VERSION ""

NS_ :

BS_:

BU_: Vector__XXX
BA_DEF_ BO_ "VFrameFormat" ENUM "StandardCAN","ExtendedCAN","reserved","J1939PG";
BA_DEF_DEF_ "VFrameFormat" 0;

BO_ 2565933008 ZT_18F107D0: 8 Vector__XXX
 SG_ 驱动电机序号 : 0|8@1+ (1,0) [0|0] "" Vector__XXX
 SG_ 加速踏板行程值 : 40|8@1+ (1,0) [0|0] "%" Vector__XXX
 SG_ 制动踏板状态 : 48|8@1+ (1,0) [0|0] "%" Vector__XXX
 SG_ 电机控制器输入电压 : 15|16@0+ (0.1,0) [0|0] "V" Vector__XXX

BA_ "VFrameFormat" BO_ 2565933008 1;
CM_ BO_ 2565933008 "制动踏板状态 / 加速踏板行程值 | 信号数 5";
CM_ SG_ 2565933008 驱动电机序号 "驱动电机序号";
CM_ SG_ 2565933008 加速踏板行程值 "加速踏板行程值";
CM_ SG_ 2565933008 制动踏板状态 "制动踏板状态";
CM_ SG_ 2565933008 电机控制器输入电压 "电机控制器输入电压";

BO_ 2565933043 ZT_UNKNOWN_18F107F3: 8 Vector__XXX
 SG_ 字节0 : 0|8@1+ (1,0) [0|255] "" Vector__XXX
 SG_ 字节1 : 8|8@1+ (1,0) [0|255] "" Vector__XXX
 SG_ 字节2 : 16|8@1+ (1,0) [0|255] "" Vector__XXX
 SG_ 字节3 : 24|8@1+ (1,0) [0|255] "" Vector__XXX
 SG_ 字节4 : 32|8@1+ (1,0) [0|255] "" Vector__XXX
 SG_ 字节5 : 40|8@1+ (1,0) [0|255] "" Vector__XXX
 SG_ 字节6 : 48|8@1+ (1,0) [0|255] "" Vector__XXX
 SG_ 字节7 : 56|8@1+ (1,0) [0|255] "" Vector__XXX

BA_ "VFrameFormat" BO_ 2565933043 1;
CM_ BO_ 2565933043 "电池管理系统 | 无信号定义, 按原始字节输出";
CM_ SG_ 2565933043 字节0 "字节0（原始值，无信号定义）";
CM_ SG_ 2565933043 字节1 "字节1（原始值，无信号定义）";
CM_ SG_ 2565933043 字节2 "字节2（原始值，无信号定义）";
CM_ SG_ 2565933043 字节3 "字节3（原始值，无信号定义）";
CM_ SG_ 2565933043 字节4 "字节4（原始值，无信号定义）";
CM_ SG_ 2565933043 字节5 "字节5（原始值，无信号定义）";
CM_ SG_ 2565933043 字节6 "字节6（原始值，无信号定义）";
CM_ SG_ 2565933043 字节7 "字节7（原始值，无信号定义）";

BO_ 2565933264 ZT_18F108D0: 8 Vector__XXX
 SG_ 温度差异报警 : 8|1@1+ (1,0) [0|0] "" Vector__XXX
 SG_ 电池高温报警 : 9|1@1+ (1,0) [0|0] "" Vector__XXX
 SG_ 车载储能装置过压报警 : 10|1@1+ (1,0) [0|0] "" Vector__XXX
 SG_ 车载储能装置欠压报警 : 11|1@1+ (1,0) [0|0] "" Vector__XXX
 SG_ SOC(电池可用容量)低报警 : 12|1@1+ (1,0) [0|0] "" Vector__XXX
 SG_ 单体过压报警 : 13|1@1+ (1,0) [0|0] "" Vector__XXX
 SG_ 单体欠压报警 : 14|1@1+ (1,0) [0|0] "" Vector__XXX
 SG_ SOC(电池可用容量)过高报警 : 15|1@1+ (1,0) [0|0] "" Vector__XXX
 SG_ SOC(电池可用容量)跳变报警 : 16|1@1+ (1,0) [0|0] "" Vector__XXX
 SG_ 可充电储能系统不匹配报警 : 17|1@1+ (1,0) [0|0] "" Vector__XXX
 SG_ 电池单体一致性差报警 : 18|1@1+ (1,0) [0|0] "" Vector__XXX
 SG_ 绝缘报警 : 19|1@1+ (1,0) [0|0] "" Vector__XXX
 SG_ DCDC(直流转化直流)温度报警 : 20|1@1+ (1,0) [0|0] "" Vector__XXX
 SG_ 制动系统报警 : 21|1@1+ (1,0) [0|0] "" Vector__XXX
 SG_ DCDC(直流转化直流)状态报警 : 22|1@1+ (1,0) [0|0] "" Vector__XXX
 SG_ 驱动电机控制器温度报警 : 23|1@1+ (1,0) [0|0] "" Vector__XXX
 SG_ 高压互锁状态报警 : 24|1@1+ (1,0) [0|0] "" Vector__XXX
 SG_ 驱动电机温度报警 : 25|1@1+ (1,0) [0|0] "" Vector__XXX
 SG_ 车载储能装置过充 : 26|1@1+ (1,0) [0|0] "" Vector__XXX
 SG_ 最高报警等级 : 0|8@1+ (1,0) [0|0] "" Vector__XXX
 SG_ 可充电储能装置故障总数 : 40|8@1+ (1,0) [0|0] "" Vector__XXX
 SG_ 驱动电机故障总数 : 48|8@1+ (1,0) [0|0] "" Vector__XXX
 SG_ 其他故障总数 : 56|8@1+ (1,0) [0|0] "" Vector__XXX

BA_ "VFrameFormat" BO_ 2565933264 1;
CM_ BO_ 2565933264 "DCDC(直流转化直流)温度报警 / DCDC(直流转化直流)状态报警 | 信号数 23";
CM_ SG_ 2565933264 温度差异报警 "温度差异报警 [枚举: 报警|无]";
VAL_ 2565933264 温度差异报警 0 "无" 1 "报警";
CM_ SG_ 2565933264 电池高温报警 "电池高温报警 [枚举: 报警|无]";
VAL_ 2565933264 电池高温报警 0 "无" 1 "报警";
CM_ SG_ 2565933264 车载储能装置过压报警 "车载储能装置过压报警 [枚举: 报警|无]";
VAL_ 2565933264 车载储能装置过压报警 0 "无" 1 "报警";
CM_ SG_ 2565933264 车载储能装置欠压报警 "车载储能装置欠压报警 [枚举: 报警|无]";
VAL_ 2565933264 车载储能装置欠压报警 0 "无" 1 "报警";
CM_ SG_ 2565933264 SOC(电池可用容量)低报警 "SOC(电池可用容量)低报警 [枚举: 报警|无]";
VAL_ 2565933264 SOC(电池可用容量)低报警 0 "无" 1 "报警";
CM_ SG_ 2565933264 单体过压报警 "单体过压报警 [枚举: 报警|无]";
VAL_ 2565933264 单体过压报警 0 "无" 1 "报警";
CM_ SG_ 2565933264 单体欠压报警 "单体欠压报警 [枚举: 报警|无]";
VAL_ 2565933264 单体欠压报警 0 "无" 1 "报警";
CM_ SG_ 2565933264 SOC(电池可用容量)过高报警 "SOC(电池可用容量)过高报警 [枚举: 报警|无]";
VAL_ 2565933264 SOC(电池可用容量)过高报警 0 "无" 1 "报警";
CM_ SG_ 2565933264 SOC(电池可用容量)跳变报警 "SOC(电池可用容量)跳变报警 [枚举: 报警|无]";
VAL_ 2565933264 SOC(电池可用容量)跳变报警 0 "无" 1 "报警";
CM_ SG_ 2565933264 可充电储能系统不匹配报警 "可充电储能系统不匹配报警 [枚举: 报警|无]";
VAL_ 2565933264 可充电储能系统不匹配报警 0 "无" 1 "报警";
CM_ SG_ 2565933264 电池单体一致性差报警 "电池单体一致性差报警 [枚举: 报警|无]";
VAL_ 2565933264 电池单体一致性差报警 0 "无" 1 "报警";
CM_ SG_ 2565933264 绝缘报警 "绝缘报警 [枚举: 报警|无]";
VAL_ 2565933264 绝缘报警 0 "无" 1 "报警";
CM_ SG_ 2565933264 DCDC(直流转化直流)温度报警 "DCDC(直流转化直流)温度报警 [枚举: 报警|无]";
VAL_ 2565933264 DCDC(直流转化直流)温度报警 0 "无" 1 "报警";
CM_ SG_ 2565933264 制动系统报警 "制动系统报警 [枚举: 报警|无]";
VAL_ 2565933264 制动系统报警 0 "无" 1 "报警";
CM_ SG_ 2565933264 DCDC(直流转化直流)状态报警 "DCDC(直流转化直流)状态报警 [枚举: 报警|无]";
VAL_ 2565933264 DCDC(直流转化直流)状态报警 0 "无" 1 "报警";
CM_ SG_ 2565933264 驱动电机控制器温度报警 "驱动电机控制器温度报警 [枚举: 报警|无]";
VAL_ 2565933264 驱动电机控制器温度报警 0 "无" 1 "报警";
CM_ SG_ 2565933264 高压互锁状态报警 "高压互锁状态报警 [枚举: 报警|无]";
VAL_ 2565933264 高压互锁状态报警 0 "无" 1 "报警";
CM_ SG_ 2565933264 驱动电机温度报警 "驱动电机温度报警 [枚举: 报警|无]";
VAL_ 2565933264 驱动电机温度报警 0 "无" 1 "报警";
CM_ SG_ 2565933264 车载储能装置过充 "车载储能装置过充 [枚举: 报警|无]";
VAL_ 2565933264 车载储能装置过充 0 "无" 1 "报警";
CM_ SG_ 2565933264 最高报警等级 "最高报警等级 [枚举: 无故障|1级故障（轻微）|2级故障（较严重）|3级故障（严重）|异常|无效|无效数据]";
VAL_ 2565933264 最高报警等级 0 "无故障" 1 "1级故障（轻微）" 2 "2级故障（较严重）" 3 "3级故障（严重）" 254 "异常" 255 "无效";
CM_ SG_ 2565933264 可充电储能装置故障总数 "可充电储能装置故障总数";
CM_ SG_ 2565933264 驱动电机故障总数 "驱动电机故障总数";
CM_ SG_ 2565933264 其他故障总数 "其他故障总数";

BO_ 2565933299 ZT_UNKNOWN_18F108F3: 8 Vector__XXX
 SG_ 字节0 : 0|8@1+ (1,0) [0|255] "" Vector__XXX
 SG_ 字节1 : 8|8@1+ (1,0) [0|255] "" Vector__XXX
 SG_ 字节2 : 16|8@1+ (1,0) [0|255] "" Vector__XXX
 SG_ 字节3 : 24|8@1+ (1,0) [0|255] "" Vector__XXX
 SG_ 字节4 : 32|8@1+ (1,0) [0|255] "" Vector__XXX
 SG_ 字节5 : 40|8@1+ (1,0) [0|255] "" Vector__XXX
 SG_ 字节6 : 48|8@1+ (1,0) [0|255] "" Vector__XXX
 SG_ 字节7 : 56|8@1+ (1,0) [0|255] "" Vector__XXX

BA_ "VFrameFormat" BO_ 2565933299 1;
CM_ BO_ 2565933299 "电池管理系统 | 无信号定义, 按原始字节输出";
CM_ SG_ 2565933299 字节0 "字节0（原始值，无信号定义）";
CM_ SG_ 2565933299 字节1 "字节1（原始值，无信号定义）";
CM_ SG_ 2565933299 字节2 "字节2（原始值，无信号定义）";
CM_ SG_ 2565933299 字节3 "字节3（原始值，无信号定义）";
CM_ SG_ 2565933299 字节4 "字节4（原始值，无信号定义）";
CM_ SG_ 2565933299 字节5 "字节5（原始值，无信号定义）";
CM_ SG_ 2565933299 字节6 "字节6（原始值，无信号定义）";
CM_ SG_ 2565933299 字节7 "字节7（原始值，无信号定义）";

BO_ 2565933520 ZT_18F109D0: 8 Vector__XXX
 SG_ 母线过流三级故障 : 0|1@1+ (1,0) [0|0] "" Vector__XXX
 SG_ 母线过压三级故障 : 1|1@1+ (1,0) [0|0] "" Vector__XXX
 SG_ 逆变器过温三级故障 : 2|1@1+ (1,0) [0|0] "" Vector__XXX
 SG_ 电机过温三级故障 : 3|1@1+ (1,0) [0|0] "" Vector__XXX
 SG_ 模块故障三级故障 : 4|1@1+ (1,0) [0|0] "" Vector__XXX
 SG_ CAN通信故障三级故障 : 5|1@1+ (1,0) [0|0] "" Vector__XXX
 SG_ 相电流过流三级故障 : 6|1@1+ (1,0) [0|0] "" Vector__XXX
 SG_ 电机欠压三级故障 : 7|1@1+ (1,0) [0|0] "" Vector__XXX
 SG_ 电机超速三级故障 : 8|1@1+ (1,0) [0|0] "" Vector__XXX
 SG_ 电机温度偏大一级故障 : 9|1@1+ (1,0) [0|0] "" Vector__XXX
 SG_ 母线电压偏小一级故障 : 10|1@1+ (1,0) [0|0] "" Vector__XXX
 SG_ 母线电压偏大一级故障 : 11|1@1+ (1,0) [0|0] "" Vector__XXX
 SG_ 逆变器温度偏大一级故障 : 12|1@1+ (1,0) [0|0] "" Vector__XXX
 SG_ 相电流过载一级故障 : 13|1@1+ (1,0) [0|0] "" Vector__XXX
 SG_ 电机堵转故障三级故障 : 14|1@1+ (1,0) [0|0] "" Vector__XXX
 SG_ 软件检测过流三级故障 : 15|1@1+ (1,0) [0|0] "" Vector__XXX
 SG_ 控制器硬件检测有故障三级故障 : 16|1@1+ (1,0) [0|0] "" Vector__XXX
 SG_ 控制器过温三级故障 : 17|1@1+ (1,0) [0|0] "" Vector__XXX
 SG_ SDUerror三级故障 : 18|1@1+ (1,0) [0|0] "" Vector__XXX
 SG_ 初始化故障一级故障 : 19|1@1+ (1,0) [0|0] "" Vector__XXX
 SG_ VCU(整车控制器)硬件三级故障 : 32|1@1+ (1,0) [0|0] "" Vector__XXX
 SG_ VCU(整车控制器)供电异常三级故障 : 33|1@1+ (1,0) [0|0] "" Vector__XXX
 SG_ 电机控制器预充三级故障 : 34|1@1+ (1,0) [0|0] "" Vector__XXX
 SG_ VCU(整车控制器)与BMS(电池管理系统)通信三级故障 : 35|1@1+ (1,0) [0|0] "" Vector__XXX
 SG_ VCU(整车控制器)与MCU(驱动电机控制单元)通信三级故障 : 36|1@1+ (1,0) [0|0] "" Vector__XXX
 SG_ VCU(整车控制器)与换档面板通信三级故障 : 37|1@1+ (1,0) [0|0] "" Vector__XXX
 SG_ 制动踏板三级故障 : 38|1@1+ (1,0) [0|0] "" Vector__XXX
 SG_ 加速踏板三级故障 : 39|1@1+ (1,0) [0|0] "" Vector__XXX
 SG_ 换档面板三级故障 : 40|1@1+ (1,0) [0|0] "" Vector__XXX
 SG_ 电机转速传感器故障三级故障 : 41|1@1+ (1,0) [0|0] "" Vector__XXX
 SG_ 变速器三级故障 : 42|1@1+ (1,0) [0|0] "" Vector__XXX
 SG_ 变速器转速传感器三级故障 : 43|1@1+ (1,0) [0|0] "" Vector__XXX
 SG_ 变速器位置传感器三级故障 : 44|1@1+ (1,0) [0|0] "" Vector__XXX
 SG_ 变速器执行器三级故障 : 45|1@1+ (1,0) [0|0] "" Vector__XXX
 SG_ 档位啮合三级故障 : 46|1@1+ (1,0) [0|0] "" Vector__XXX
 SG_ 摘挡三级故障 : 47|1@1+ (1,0) [0|0] "" Vector__XXX
 SG_ 选档三级故障 : 48|1@1+ (1,0) [0|0] "" Vector__XXX
 SG_ 挂档三级故障 : 49|1@1+ (1,0) [0|0] "" Vector__XXX
 SG_ VCU(整车控制器)系统三级故障 : 50|1@1+ (1,0) [0|0] "" Vector__XXX
 SG_ 车速二级故障 : 56|1@1+ (1,0) [0|0] "" Vector__XXX

BA_ "VFrameFormat" BO_ 2565933520 1;
CM_ BO_ 2565933520 "CAN通信故障三级故障 / SDUerror三级故障 | 信号数 40";
CM_ SG_ 2565933520 母线过流三级故障 "母线过流三级故障 [枚举: 故障|无故障]";
VAL_ 2565933520 母线过流三级故障 0 "无故障" 1 "故障";
CM_ SG_ 2565933520 母线过压三级故障 "母线过压三级故障 [枚举: 故障|无故障]";
VAL_ 2565933520 母线过压三级故障 0 "无故障" 1 "故障";
CM_ SG_ 2565933520 逆变器过温三级故障 "逆变器过温三级故障 [枚举: 故障|无故障]";
VAL_ 2565933520 逆变器过温三级故障 0 "无故障" 1 "故障";
CM_ SG_ 2565933520 电机过温三级故障 "电机过温三级故障 [枚举: 故障|无故障]";
VAL_ 2565933520 电机过温三级故障 0 "无故障" 1 "故障";
CM_ SG_ 2565933520 模块故障三级故障 "模块故障三级故障 [枚举: 故障|无故障]";
VAL_ 2565933520 模块故障三级故障 0 "无故障" 1 "故障";
CM_ SG_ 2565933520 CAN通信故障三级故障 "CAN通信故障三级故障 [枚举: 故障|无故障]";
VAL_ 2565933520 CAN通信故障三级故障 0 "无故障" 1 "故障";
CM_ SG_ 2565933520 相电流过流三级故障 "相电流过流三级故障 [枚举: 故障|无故障]";
VAL_ 2565933520 相电流过流三级故障 0 "无故障" 1 "故障";
CM_ SG_ 2565933520 电机欠压三级故障 "电机欠压三级故障 [枚举: 故障|无故障]";
VAL_ 2565933520 电机欠压三级故障 0 "无故障" 1 "故障";
CM_ SG_ 2565933520 电机超速三级故障 "电机超速三级故障 [枚举: 故障|无故障]";
VAL_ 2565933520 电机超速三级故障 0 "无故障" 1 "故障";
CM_ SG_ 2565933520 电机温度偏大一级故障 "电机温度偏大一级故障 [枚举: 故障|无故障]";
VAL_ 2565933520 电机温度偏大一级故障 0 "无故障" 1 "故障";
CM_ SG_ 2565933520 母线电压偏小一级故障 "母线电压偏小一级故障 [枚举: 故障|无故障]";
VAL_ 2565933520 母线电压偏小一级故障 0 "无故障" 1 "故障";
CM_ SG_ 2565933520 母线电压偏大一级故障 "母线电压偏大一级故障 [枚举: 故障|无故障]";
VAL_ 2565933520 母线电压偏大一级故障 0 "无故障" 1 "故障";
CM_ SG_ 2565933520 逆变器温度偏大一级故障 "逆变器温度偏大一级故障 [枚举: 故障|无故障]";
VAL_ 2565933520 逆变器温度偏大一级故障 0 "无故障" 1 "故障";
CM_ SG_ 2565933520 相电流过载一级故障 "相电流过载一级故障 [枚举: 故障|无故障]";
VAL_ 2565933520 相电流过载一级故障 0 "无故障" 1 "故障";
CM_ SG_ 2565933520 电机堵转故障三级故障 "电机堵转故障三级故障 [枚举: 故障|无故障]";
VAL_ 2565933520 电机堵转故障三级故障 0 "无故障" 1 "故障";
CM_ SG_ 2565933520 软件检测过流三级故障 "软件检测过流三级故障 [枚举: 故障|无故障]";
VAL_ 2565933520 软件检测过流三级故障 0 "无故障" 1 "故障";
CM_ SG_ 2565933520 控制器硬件检测有故障三级故障 "控制器硬件检测有故障三级故障 [枚举: 故障|无故障]";
VAL_ 2565933520 控制器硬件检测有故障三级故障 0 "无故障" 1 "故障";
CM_ SG_ 2565933520 控制器过温三级故障 "控制器过温三级故障 [枚举: 故障|无故障]";
VAL_ 2565933520 控制器过温三级故障 0 "无故障" 1 "故障";
CM_ SG_ 2565933520 SDUerror三级故障 "SDUerror三级故障 [枚举: 故障|无故障]";
VAL_ 2565933520 SDUerror三级故障 0 "无故障" 1 "故障";
CM_ SG_ 2565933520 初始化故障一级故障 "初始化故障一级故障 [枚举: 故障|无故障]";
VAL_ 2565933520 初始化故障一级故障 0 "无故障" 1 "故障";
CM_ SG_ 2565933520 VCU(整车控制器)硬件三级故障 "VCU(整车控制器)硬件三级故障 [枚举: 故障|无故障]";
VAL_ 2565933520 VCU(整车控制器)硬件三级故障 0 "无故障" 1 "故障";
CM_ SG_ 2565933520 VCU(整车控制器)供电异常三级故障 "VCU(整车控制器)供电异常三级故障 [枚举: 故障|无故障]";
VAL_ 2565933520 VCU(整车控制器)供电异常三级故障 0 "无故障" 1 "故障";
CM_ SG_ 2565933520 电机控制器预充三级故障 "电机控制器预充三级故障 [枚举: 故障|无故障]";
VAL_ 2565933520 电机控制器预充三级故障 0 "无故障" 1 "故障";
CM_ SG_ 2565933520 VCU(整车控制器)与BMS(电池管理系统)通信三级故障 "VCU(整车控制器)与BMS(电池管理系统)通信三级故障 [枚举: 故障|无故障]";
VAL_ 2565933520 VCU(整车控制器)与BMS(电池管理系统)通信三级故障 0 "无故障" 1 "故障";
CM_ SG_ 2565933520 VCU(整车控制器)与MCU(驱动电机控制单元)通信三级故障 "VCU(整车控制器)与MCU(驱动电机控制单元)通信三级故障 [枚举: 故障|无故障]";
VAL_ 2565933520 VCU(整车控制器)与MCU(驱动电机控制单元)通信三级故障 0 "无故障" 1 "故障";
CM_ SG_ 2565933520 VCU(整车控制器)与换档面板通信三级故障 "VCU(整车控制器)与换档面板通信三级故障 [枚举: 故障|无故障]";
VAL_ 2565933520 VCU(整车控制器)与换档面板通信三级故障 0 "无故障" 1 "故障";
CM_ SG_ 2565933520 制动踏板三级故障 "制动踏板三级故障 [枚举: 故障|无故障]";
VAL_ 2565933520 制动踏板三级故障 0 "无故障" 1 "故障";
CM_ SG_ 2565933520 加速踏板三级故障 "加速踏板三级故障 [枚举: 故障|无故障]";
VAL_ 2565933520 加速踏板三级故障 0 "无故障" 1 "故障";
CM_ SG_ 2565933520 换档面板三级故障 "换档面板三级故障 [枚举: 故障|无故障]";
VAL_ 2565933520 换档面板三级故障 0 "无故障" 1 "故障";
CM_ SG_ 2565933520 电机转速传感器故障三级故障 "电机转速传感器故障三级故障 [枚举: 故障|无故障]";
VAL_ 2565933520 电机转速传感器故障三级故障 0 "无故障" 1 "故障";
CM_ SG_ 2565933520 变速器三级故障 "变速器三级故障 [枚举: 故障|无故障]";
VAL_ 2565933520 变速器三级故障 0 "无故障" 1 "故障";
CM_ SG_ 2565933520 变速器转速传感器三级故障 "变速器转速传感器三级故障 [枚举: 故障|无故障]";
VAL_ 2565933520 变速器转速传感器三级故障 0 "无故障" 1 "故障";
CM_ SG_ 2565933520 变速器位置传感器三级故障 "变速器位置传感器三级故障 [枚举: 故障|无故障]";
VAL_ 2565933520 变速器位置传感器三级故障 0 "无故障" 1 "故障";
CM_ SG_ 2565933520 变速器执行器三级故障 "变速器执行器三级故障 [枚举: 故障|无故障]";
VAL_ 2565933520 变速器执行器三级故障 0 "无故障" 1 "故障";
CM_ SG_ 2565933520 档位啮合三级故障 "档位啮合三级故障 [枚举: 故障|无故障]";
VAL_ 2565933520 档位啮合三级故障 0 "无故障" 1 "故障";
CM_ SG_ 2565933520 摘挡三级故障 "摘挡三级故障 [枚举: 故障|无故障]";
VAL_ 2565933520 摘挡三级故障 0 "无故障" 1 "故障";
CM_ SG_ 2565933520 选档三级故障 "选档三级故障 [枚举: 故障|无故障]";
VAL_ 2565933520 选档三级故障 0 "无故障" 1 "故障";
CM_ SG_ 2565933520 挂档三级故障 "挂档三级故障 [枚举: 故障|无故障]";
VAL_ 2565933520 挂档三级故障 0 "无故障" 1 "故障";
CM_ SG_ 2565933520 VCU(整车控制器)系统三级故障 "VCU(整车控制器)系统三级故障 [枚举: 故障|无故障]";
VAL_ 2565933520 VCU(整车控制器)系统三级故障 0 "无故障" 1 "故障";
CM_ SG_ 2565933520 车速二级故障 "车速二级故障 [枚举: 故障|无故障]";
VAL_ 2565933520 车速二级故障 0 "无故障" 1 "故障";

BO_ 2565933555 ZT_UNKNOWN_18F109F3: 8 Vector__XXX
 SG_ 字节0 : 0|8@1+ (1,0) [0|255] "" Vector__XXX
 SG_ 字节1 : 8|8@1+ (1,0) [0|255] "" Vector__XXX
 SG_ 字节2 : 16|8@1+ (1,0) [0|255] "" Vector__XXX
 SG_ 字节3 : 24|8@1+ (1,0) [0|255] "" Vector__XXX
 SG_ 字节4 : 32|8@1+ (1,0) [0|255] "" Vector__XXX
 SG_ 字节5 : 40|8@1+ (1,0) [0|255] "" Vector__XXX
 SG_ 字节6 : 48|8@1+ (1,0) [0|255] "" Vector__XXX
 SG_ 字节7 : 56|8@1+ (1,0) [0|255] "" Vector__XXX

BA_ "VFrameFormat" BO_ 2565933555 1;
CM_ BO_ 2565933555 "电池管理系统 | 无信号定义, 按原始字节输出";
CM_ SG_ 2565933555 字节0 "字节0（原始值，无信号定义）";
CM_ SG_ 2565933555 字节1 "字节1（原始值，无信号定义）";
CM_ SG_ 2565933555 字节2 "字节2（原始值，无信号定义）";
CM_ SG_ 2565933555 字节3 "字节3（原始值，无信号定义）";
CM_ SG_ 2565933555 字节4 "字节4（原始值，无信号定义）";
CM_ SG_ 2565933555 字节5 "字节5（原始值，无信号定义）";
CM_ SG_ 2565933555 字节6 "字节6（原始值，无信号定义）";
CM_ SG_ 2565933555 字节7 "字节7（原始值，无信号定义）";

BO_ 2565933776 ZT_18F10AD0: 8 Vector__XXX
 SG_ 发送包序号 : 0|8@1+ (1,0) [0|0] "" Vector__XXX

BA_ "VFrameFormat" BO_ 2565933776 1;
CM_ BO_ 2565933776 "发送包序号 | 信号数 1";
CM_ SG_ 2565933776 发送包序号 "发送包序号";

BO_ 2565933811 ZT_UNKNOWN_18F10AF3: 8 Vector__XXX
 SG_ 字节0 : 0|8@1+ (1,0) [0|255] "" Vector__XXX
 SG_ 字节1 : 8|8@1+ (1,0) [0|255] "" Vector__XXX
 SG_ 字节2 : 16|8@1+ (1,0) [0|255] "" Vector__XXX
 SG_ 字节3 : 24|8@1+ (1,0) [0|255] "" Vector__XXX
 SG_ 字节4 : 32|8@1+ (1,0) [0|255] "" Vector__XXX
 SG_ 字节5 : 40|8@1+ (1,0) [0|255] "" Vector__XXX
 SG_ 字节6 : 48|8@1+ (1,0) [0|255] "" Vector__XXX
 SG_ 字节7 : 56|8@1+ (1,0) [0|255] "" Vector__XXX

BA_ "VFrameFormat" BO_ 2565933811 1;
CM_ BO_ 2565933811 "电池管理系统 | 无信号定义, 按原始字节输出";
CM_ SG_ 2565933811 字节0 "字节0（原始值，无信号定义）";
CM_ SG_ 2565933811 字节1 "字节1（原始值，无信号定义）";
CM_ SG_ 2565933811 字节2 "字节2（原始值，无信号定义）";
CM_ SG_ 2565933811 字节3 "字节3（原始值，无信号定义）";
CM_ SG_ 2565933811 字节4 "字节4（原始值，无信号定义）";
CM_ SG_ 2565933811 字节5 "字节5（原始值，无信号定义）";
CM_ SG_ 2565933811 字节6 "字节6（原始值，无信号定义）";
CM_ SG_ 2565933811 字节7 "字节7（原始值，无信号定义）";

BO_ 2565934032 ZT_18F10BD0: 8 Vector__XXX
 SG_ 驱动电机状态 : 8|8@1+ (1,0) [0|0] "" Vector__XXX
 SG_ 驱动电机序号 : 0|8@1+ (1,0) [0|0] "" Vector__XXX
 SG_ 驱动电机控制器温度 : 16|8@1+ (1,-40) [0|0] "℃" Vector__XXX
 SG_ 驱动电机温度 : 56|8@1+ (1,-40) [0|0] "℃" Vector__XXX
 SG_ 驱动电机转速 : 31|16@0+ (1,-20000) [0|0] "rpm" Vector__XXX

BA_ "VFrameFormat" BO_ 2565934032 1;
CM_ BO_ 2565934032 "驱动电机序号 / 驱动电机控制器温度 | 信号数 6";
CM_ SG_ 2565934032 驱动电机状态 "驱动电机状态 [枚举: 耗电|发电|关闭状态|准备状态|异常|无效|无效数据]";
VAL_ 2565934032 驱动电机状态 1 "耗电" 2 "发电" 3 "关闭状态" 4 "准备状态" 254 "异常" 255 "无效";
CM_ SG_ 2565934032 驱动电机序号 "驱动电机序号";
CM_ SG_ 2565934032 驱动电机控制器温度 "驱动电机控制器温度";
CM_ SG_ 2565934032 驱动电机温度 "驱动电机温度";
CM_ SG_ 2565934032 驱动电机转速 "驱动电机转速";

BO_ 2565934067 ZT_UNKNOWN_18F10BF3: 8 Vector__XXX
 SG_ 字节0 : 0|8@1+ (1,0) [0|255] "" Vector__XXX
 SG_ 字节1 : 8|8@1+ (1,0) [0|255] "" Vector__XXX
 SG_ 字节2 : 16|8@1+ (1,0) [0|255] "" Vector__XXX
 SG_ 字节3 : 24|8@1+ (1,0) [0|255] "" Vector__XXX
 SG_ 字节4 : 32|8@1+ (1,0) [0|255] "" Vector__XXX
 SG_ 字节5 : 40|8@1+ (1,0) [0|255] "" Vector__XXX
 SG_ 字节6 : 48|8@1+ (1,0) [0|255] "" Vector__XXX
 SG_ 字节7 : 56|8@1+ (1,0) [0|255] "" Vector__XXX

BA_ "VFrameFormat" BO_ 2565934067 1;
CM_ BO_ 2565934067 "电池管理系统 | 无信号定义, 按原始字节输出";
CM_ SG_ 2565934067 字节0 "字节0（原始值，无信号定义）";
CM_ SG_ 2565934067 字节1 "字节1（原始值，无信号定义）";
CM_ SG_ 2565934067 字节2 "字节2（原始值，无信号定义）";
CM_ SG_ 2565934067 字节3 "字节3（原始值，无信号定义）";
CM_ SG_ 2565934067 字节4 "字节4（原始值，无信号定义）";
CM_ SG_ 2565934067 字节5 "字节5（原始值，无信号定义）";
CM_ SG_ 2565934067 字节6 "字节6（原始值，无信号定义）";
CM_ SG_ 2565934067 字节7 "字节7（原始值，无信号定义）";

BO_ 2565934323 ZT_UNKNOWN_18F10CF3: 8 Vector__XXX
 SG_ 字节0 : 0|8@1+ (1,0) [0|255] "" Vector__XXX
 SG_ 字节1 : 8|8@1+ (1,0) [0|255] "" Vector__XXX
 SG_ 字节2 : 16|8@1+ (1,0) [0|255] "" Vector__XXX
 SG_ 字节3 : 24|8@1+ (1,0) [0|255] "" Vector__XXX
 SG_ 字节4 : 32|8@1+ (1,0) [0|255] "" Vector__XXX
 SG_ 字节5 : 40|8@1+ (1,0) [0|255] "" Vector__XXX
 SG_ 字节6 : 48|8@1+ (1,0) [0|255] "" Vector__XXX
 SG_ 字节7 : 56|8@1+ (1,0) [0|255] "" Vector__XXX

BA_ "VFrameFormat" BO_ 2565934323 1;
CM_ BO_ 2565934323 "电池管理系统 | 无信号定义, 按原始字节输出";
CM_ SG_ 2565934323 字节0 "字节0（原始值，无信号定义）";
CM_ SG_ 2565934323 字节1 "字节1（原始值，无信号定义）";
CM_ SG_ 2565934323 字节2 "字节2（原始值，无信号定义）";
CM_ SG_ 2565934323 字节3 "字节3（原始值，无信号定义）";
CM_ SG_ 2565934323 字节4 "字节4（原始值，无信号定义）";
CM_ SG_ 2565934323 字节5 "字节5（原始值，无信号定义）";
CM_ SG_ 2565934323 字节6 "字节6（原始值，无信号定义）";
CM_ SG_ 2565934323 字节7 "字节7（原始值，无信号定义）";

BO_ 2565934579 ZT_UNKNOWN_18F10DF3: 8 Vector__XXX
 SG_ 字节0 : 0|8@1+ (1,0) [0|255] "" Vector__XXX
 SG_ 字节1 : 8|8@1+ (1,0) [0|255] "" Vector__XXX
 SG_ 字节2 : 16|8@1+ (1,0) [0|255] "" Vector__XXX
 SG_ 字节3 : 24|8@1+ (1,0) [0|255] "" Vector__XXX
 SG_ 字节4 : 32|8@1+ (1,0) [0|255] "" Vector__XXX
 SG_ 字节5 : 40|8@1+ (1,0) [0|255] "" Vector__XXX
 SG_ 字节6 : 48|8@1+ (1,0) [0|255] "" Vector__XXX
 SG_ 字节7 : 56|8@1+ (1,0) [0|255] "" Vector__XXX

BA_ "VFrameFormat" BO_ 2565934579 1;
CM_ BO_ 2565934579 "电池管理系统 | 无信号定义, 按原始字节输出";
CM_ SG_ 2565934579 字节0 "字节0（原始值，无信号定义）";
CM_ SG_ 2565934579 字节1 "字节1（原始值，无信号定义）";
CM_ SG_ 2565934579 字节2 "字节2（原始值，无信号定义）";
CM_ SG_ 2565934579 字节3 "字节3（原始值，无信号定义）";
CM_ SG_ 2565934579 字节4 "字节4（原始值，无信号定义）";
CM_ SG_ 2565934579 字节5 "字节5（原始值，无信号定义）";
CM_ SG_ 2565934579 字节6 "字节6（原始值，无信号定义）";
CM_ SG_ 2565934579 字节7 "字节7（原始值，无信号定义）";

BO_ 2565934835 ZT_UNKNOWN_18F10EF3: 8 Vector__XXX
 SG_ 字节0 : 0|8@1+ (1,0) [0|255] "" Vector__XXX
 SG_ 字节1 : 8|8@1+ (1,0) [0|255] "" Vector__XXX
 SG_ 字节2 : 16|8@1+ (1,0) [0|255] "" Vector__XXX
 SG_ 字节3 : 24|8@1+ (1,0) [0|255] "" Vector__XXX
 SG_ 字节4 : 32|8@1+ (1,0) [0|255] "" Vector__XXX
 SG_ 字节5 : 40|8@1+ (1,0) [0|255] "" Vector__XXX
 SG_ 字节6 : 48|8@1+ (1,0) [0|255] "" Vector__XXX
 SG_ 字节7 : 56|8@1+ (1,0) [0|255] "" Vector__XXX

BA_ "VFrameFormat" BO_ 2565934835 1;
CM_ BO_ 2565934835 "电池管理系统 | 无信号定义, 按原始字节输出";
CM_ SG_ 2565934835 字节0 "字节0（原始值，无信号定义）";
CM_ SG_ 2565934835 字节1 "字节1（原始值，无信号定义）";
CM_ SG_ 2565934835 字节2 "字节2（原始值，无信号定义）";
CM_ SG_ 2565934835 字节3 "字节3（原始值，无信号定义）";
CM_ SG_ 2565934835 字节4 "字节4（原始值，无信号定义）";
CM_ SG_ 2565934835 字节5 "字节5（原始值，无信号定义）";
CM_ SG_ 2565934835 字节6 "字节6（原始值，无信号定义）";
CM_ SG_ 2565934835 字节7 "字节7（原始值，无信号定义）";

BO_ 2565935091 ZT_UNKNOWN_18F10FF3: 8 Vector__XXX
 SG_ 字节0 : 0|8@1+ (1,0) [0|255] "" Vector__XXX
 SG_ 字节1 : 8|8@1+ (1,0) [0|255] "" Vector__XXX
 SG_ 字节2 : 16|8@1+ (1,0) [0|255] "" Vector__XXX
 SG_ 字节3 : 24|8@1+ (1,0) [0|255] "" Vector__XXX
 SG_ 字节4 : 32|8@1+ (1,0) [0|255] "" Vector__XXX
 SG_ 字节5 : 40|8@1+ (1,0) [0|255] "" Vector__XXX
 SG_ 字节6 : 48|8@1+ (1,0) [0|255] "" Vector__XXX
 SG_ 字节7 : 56|8@1+ (1,0) [0|255] "" Vector__XXX

BA_ "VFrameFormat" BO_ 2565935091 1;
CM_ BO_ 2565935091 "电池管理系统 | 无信号定义, 按原始字节输出";
CM_ SG_ 2565935091 字节0 "字节0（原始值，无信号定义）";
CM_ SG_ 2565935091 字节1 "字节1（原始值，无信号定义）";
CM_ SG_ 2565935091 字节2 "字节2（原始值，无信号定义）";
CM_ SG_ 2565935091 字节3 "字节3（原始值，无信号定义）";
CM_ SG_ 2565935091 字节4 "字节4（原始值，无信号定义）";
CM_ SG_ 2565935091 字节5 "字节5（原始值，无信号定义）";
CM_ SG_ 2565935091 字节6 "字节6（原始值，无信号定义）";
CM_ SG_ 2565935091 字节7 "字节7（原始值，无信号定义）";

BO_ 2565935347 ZT_UNKNOWN_18F110F3: 8 Vector__XXX
 SG_ 字节0 : 0|8@1+ (1,0) [0|255] "" Vector__XXX
 SG_ 字节1 : 8|8@1+ (1,0) [0|255] "" Vector__XXX
 SG_ 字节2 : 16|8@1+ (1,0) [0|255] "" Vector__XXX
 SG_ 字节3 : 24|8@1+ (1,0) [0|255] "" Vector__XXX
 SG_ 字节4 : 32|8@1+ (1,0) [0|255] "" Vector__XXX
 SG_ 字节5 : 40|8@1+ (1,0) [0|255] "" Vector__XXX
 SG_ 字节6 : 48|8@1+ (1,0) [0|255] "" Vector__XXX
 SG_ 字节7 : 56|8@1+ (1,0) [0|255] "" Vector__XXX

BA_ "VFrameFormat" BO_ 2565935347 1;
CM_ BO_ 2565935347 "电池管理系统 | 无信号定义, 按原始字节输出";
CM_ SG_ 2565935347 字节0 "字节0（原始值，无信号定义）";
CM_ SG_ 2565935347 字节1 "字节1（原始值，无信号定义）";
CM_ SG_ 2565935347 字节2 "字节2（原始值，无信号定义）";
CM_ SG_ 2565935347 字节3 "字节3（原始值，无信号定义）";
CM_ SG_ 2565935347 字节4 "字节4（原始值，无信号定义）";
CM_ SG_ 2565935347 字节5 "字节5（原始值，无信号定义）";
CM_ SG_ 2565935347 字节6 "字节6（原始值，无信号定义）";
CM_ SG_ 2565935347 字节7 "字节7（原始值，无信号定义）";

BO_ 2565935603 ZT_UNKNOWN_18F111F3: 8 Vector__XXX
 SG_ 字节0 : 0|8@1+ (1,0) [0|255] "" Vector__XXX
 SG_ 字节1 : 8|8@1+ (1,0) [0|255] "" Vector__XXX
 SG_ 字节2 : 16|8@1+ (1,0) [0|255] "" Vector__XXX
 SG_ 字节3 : 24|8@1+ (1,0) [0|255] "" Vector__XXX
 SG_ 字节4 : 32|8@1+ (1,0) [0|255] "" Vector__XXX
 SG_ 字节5 : 40|8@1+ (1,0) [0|255] "" Vector__XXX
 SG_ 字节6 : 48|8@1+ (1,0) [0|255] "" Vector__XXX
 SG_ 字节7 : 56|8@1+ (1,0) [0|255] "" Vector__XXX

BA_ "VFrameFormat" BO_ 2565935603 1;
CM_ BO_ 2565935603 "电池管理系统 | 无信号定义, 按原始字节输出";
CM_ SG_ 2565935603 字节0 "字节0（原始值，无信号定义）";
CM_ SG_ 2565935603 字节1 "字节1（原始值，无信号定义）";
CM_ SG_ 2565935603 字节2 "字节2（原始值，无信号定义）";
CM_ SG_ 2565935603 字节3 "字节3（原始值，无信号定义）";
CM_ SG_ 2565935603 字节4 "字节4（原始值，无信号定义）";
CM_ SG_ 2565935603 字节5 "字节5（原始值，无信号定义）";
CM_ SG_ 2565935603 字节6 "字节6（原始值，无信号定义）";
CM_ SG_ 2565935603 字节7 "字节7（原始值，无信号定义）";

BO_ 2565935859 ZT_18F112F3: 8 Vector__XXX
 SG_ 电池组18-单体电压4 : 48|16@1+ (0.001,0) [0|60] "V" Vector__XXX

BA_ "VFrameFormat" BO_ 2565935859 1;
CM_ BO_ 2565935859 "电池组18-单体电压4 | 信号数 1";
CM_ SG_ 2565935859 电池组18-单体电压4 "电池组18-单体电压4";

BO_ 2565936115 ZT_18F113F3: 8 Vector__XXX
 SG_ 电池组19-单体电压1 : 0|16@1+ (0.001,0) [0|60] "V" Vector__XXX
 SG_ 电池组19-单体电压2 : 16|16@1+ (0.001,0) [0|60] "V" Vector__XXX
 SG_ 电池组19-单体电压3 : 32|16@1+ (0.001,0) [0|60] "V" Vector__XXX
 SG_ 电池组19-单体电压4 : 48|16@1+ (0.001,0) [0|60] "V" Vector__XXX

BA_ "VFrameFormat" BO_ 2565936115 1;
CM_ BO_ 2565936115 "电池组19-单体电压1 / 电池组19-单体电压2 | 信号数 4";
CM_ SG_ 2565936115 电池组19-单体电压1 "电池组19-单体电压1";
CM_ SG_ 2565936115 电池组19-单体电压2 "电池组19-单体电压2";
CM_ SG_ 2565936115 电池组19-单体电压3 "电池组19-单体电压3";
CM_ SG_ 2565936115 电池组19-单体电压4 "电池组19-单体电压4";

BO_ 2565936371 ZT_18F114F3: 8 Vector__XXX
 SG_ 电池组20-单体电压1 : 0|16@1+ (0.001,0) [0|60] "V" Vector__XXX
 SG_ 电池组20-单体电压2 : 16|16@1+ (0.001,0) [0|60] "V" Vector__XXX
 SG_ 电池组20-单体电压3 : 32|16@1+ (0.001,0) [0|60] "V" Vector__XXX
 SG_ 电池组20-单体电压4 : 48|16@1+ (0.001,0) [0|60] "V" Vector__XXX

BA_ "VFrameFormat" BO_ 2565936371 1;
CM_ BO_ 2565936371 "电池组20-单体电压1 / 电池组20-单体电压2 | 信号数 4";
CM_ SG_ 2565936371 电池组20-单体电压1 "电池组20-单体电压1";
CM_ SG_ 2565936371 电池组20-单体电压2 "电池组20-单体电压2";
CM_ SG_ 2565936371 电池组20-单体电压3 "电池组20-单体电压3";
CM_ SG_ 2565936371 电池组20-单体电压4 "电池组20-单体电压4";

BO_ 2565936627 ZT_18F115F3: 8 Vector__XXX
 SG_ 电池组21-单体电压1 : 0|16@1+ (0.001,0) [0|60] "V" Vector__XXX
 SG_ 电池组21-单体电压2 : 16|16@1+ (0.001,0) [0|60] "V" Vector__XXX
 SG_ 电池组21-单体电压3 : 32|16@1+ (0.001,0) [0|60] "V" Vector__XXX
 SG_ 电池组21-单体电压4 : 48|16@1+ (0.001,0) [0|60] "V" Vector__XXX

BA_ "VFrameFormat" BO_ 2565936627 1;
CM_ BO_ 2565936627 "电池组21-单体电压1 / 电池组21-单体电压2 | 信号数 4";
CM_ SG_ 2565936627 电池组21-单体电压1 "电池组21-单体电压1";
CM_ SG_ 2565936627 电池组21-单体电压2 "电池组21-单体电压2";
CM_ SG_ 2565936627 电池组21-单体电压3 "电池组21-单体电压3";
CM_ SG_ 2565936627 电池组21-单体电压4 "电池组21-单体电压4";

BO_ 2565936883 ZT_18F116F3: 8 Vector__XXX
 SG_ 电池组22-单体电压1 : 0|16@1+ (0.001,0) [0|60] "V" Vector__XXX
 SG_ 电池组22-单体电压2 : 16|16@1+ (0.001,0) [0|60] "V" Vector__XXX
 SG_ 电池组22-单体电压3 : 32|16@1+ (0.001,0) [0|60] "V" Vector__XXX
 SG_ 电池组22-单体电压4 : 48|16@1+ (0.001,0) [0|60] "V" Vector__XXX

BA_ "VFrameFormat" BO_ 2565936883 1;
CM_ BO_ 2565936883 "电池组22-单体电压1 / 电池组22-单体电压2 | 信号数 4";
CM_ SG_ 2565936883 电池组22-单体电压1 "电池组22-单体电压1";
CM_ SG_ 2565936883 电池组22-单体电压2 "电池组22-单体电压2";
CM_ SG_ 2565936883 电池组22-单体电压3 "电池组22-单体电压3";
CM_ SG_ 2565936883 电池组22-单体电压4 "电池组22-单体电压4";

BO_ 2565937139 ZT_18F117F3: 8 Vector__XXX
 SG_ 电池组23-单体电压1 : 0|16@1+ (0.001,0) [0|60] "V" Vector__XXX
 SG_ 电池组23-单体电压2 : 16|16@1+ (0.001,0) [0|60] "V" Vector__XXX
 SG_ 电池组23-单体电压3 : 32|16@1+ (0.001,0) [0|60] "V" Vector__XXX
 SG_ 电池组23-单体电压4 : 48|16@1+ (0.001,0) [0|60] "V" Vector__XXX

BA_ "VFrameFormat" BO_ 2565937139 1;
CM_ BO_ 2565937139 "电池组23-单体电压1 / 电池组23-单体电压2 | 信号数 4";
CM_ SG_ 2565937139 电池组23-单体电压1 "电池组23-单体电压1";
CM_ SG_ 2565937139 电池组23-单体电压2 "电池组23-单体电压2";
CM_ SG_ 2565937139 电池组23-单体电压3 "电池组23-单体电压3";
CM_ SG_ 2565937139 电池组23-单体电压4 "电池组23-单体电压4";

BO_ 2565937395 ZT_18F118F3: 8 Vector__XXX
 SG_ 电池组24-单体电压1 : 0|16@1+ (0.001,0) [0|60] "V" Vector__XXX
 SG_ 电池组24-单体电压2 : 16|16@1+ (0.001,0) [0|60] "V" Vector__XXX
 SG_ 电池组24-单体电压3 : 32|16@1+ (0.001,0) [0|60] "V" Vector__XXX
 SG_ 电池组24-单体电压4 : 48|16@1+ (0.001,0) [0|60] "V" Vector__XXX

BA_ "VFrameFormat" BO_ 2565937395 1;
CM_ BO_ 2565937395 "电池组24-单体电压1 / 电池组24-单体电压2 | 信号数 4";
CM_ SG_ 2565937395 电池组24-单体电压1 "电池组24-单体电压1";
CM_ SG_ 2565937395 电池组24-单体电压2 "电池组24-单体电压2";
CM_ SG_ 2565937395 电池组24-单体电压3 "电池组24-单体电压3";
CM_ SG_ 2565937395 电池组24-单体电压4 "电池组24-单体电压4";

BO_ 2565937651 ZT_18F119F3: 8 Vector__XXX
 SG_ 电池组25-单体电压1 : 0|16@1+ (0.001,0) [0|60] "V" Vector__XXX
 SG_ 电池组25-单体电压2 : 16|16@1+ (0.001,0) [0|60] "V" Vector__XXX
 SG_ 电池组25-单体电压3 : 32|16@1+ (0.001,0) [0|60] "V" Vector__XXX
 SG_ 电池组25-单体电压4 : 48|16@1+ (0.001,0) [0|60] "V" Vector__XXX

BA_ "VFrameFormat" BO_ 2565937651 1;
CM_ BO_ 2565937651 "电池组25-单体电压1 / 电池组25-单体电压2 | 信号数 4";
CM_ SG_ 2565937651 电池组25-单体电压1 "电池组25-单体电压1";
CM_ SG_ 2565937651 电池组25-单体电压2 "电池组25-单体电压2";
CM_ SG_ 2565937651 电池组25-单体电压3 "电池组25-单体电压3";
CM_ SG_ 2565937651 电池组25-单体电压4 "电池组25-单体电压4";

BO_ 2565937907 ZT_18F11AF3: 8 Vector__XXX
 SG_ 电池组26-单体电压1 : 0|16@1+ (0.001,0) [0|60] "V" Vector__XXX
 SG_ 电池组26-单体电压2 : 16|16@1+ (0.001,0) [0|60] "V" Vector__XXX
 SG_ 电池组26-单体电压3 : 32|16@1+ (0.001,0) [0|60] "V" Vector__XXX
 SG_ 电池组26-单体电压4 : 48|16@1+ (0.001,0) [0|60] "V" Vector__XXX

BA_ "VFrameFormat" BO_ 2565937907 1;
CM_ BO_ 2565937907 "电池组26-单体电压1 / 电池组26-单体电压2 | 信号数 4";
CM_ SG_ 2565937907 电池组26-单体电压1 "电池组26-单体电压1";
CM_ SG_ 2565937907 电池组26-单体电压2 "电池组26-单体电压2";
CM_ SG_ 2565937907 电池组26-单体电压3 "电池组26-单体电压3";
CM_ SG_ 2565937907 电池组26-单体电压4 "电池组26-单体电压4";

BO_ 2565938163 ZT_18F11BF3: 8 Vector__XXX
 SG_ 电池组27-单体电压1 : 0|16@1+ (0.001,0) [0|60] "V" Vector__XXX
 SG_ 电池组27-单体电压2 : 16|16@1+ (0.001,0) [0|60] "V" Vector__XXX
 SG_ 电池组27-单体电压3 : 32|16@1+ (0.001,0) [0|60] "V" Vector__XXX
 SG_ 电池组27-单体电压4 : 48|16@1+ (0.001,0) [0|60] "V" Vector__XXX

BA_ "VFrameFormat" BO_ 2565938163 1;
CM_ BO_ 2565938163 "电池组27-单体电压1 / 电池组27-单体电压2 | 信号数 4";
CM_ SG_ 2565938163 电池组27-单体电压1 "电池组27-单体电压1";
CM_ SG_ 2565938163 电池组27-单体电压2 "电池组27-单体电压2";
CM_ SG_ 2565938163 电池组27-单体电压3 "电池组27-单体电压3";
CM_ SG_ 2565938163 电池组27-单体电压4 "电池组27-单体电压4";

BO_ 2565938419 ZT_18F11CF3: 8 Vector__XXX
 SG_ 电池组28-单体电压1 : 0|16@1+ (0.001,0) [0|60] "V" Vector__XXX
 SG_ 电池组28-单体电压2 : 16|16@1+ (0.001,0) [0|60] "V" Vector__XXX
 SG_ 电池组28-单体电压3 : 32|16@1+ (0.001,0) [0|60] "V" Vector__XXX
 SG_ 电池组28-单体电压4 : 48|16@1+ (0.001,0) [0|60] "V" Vector__XXX

BA_ "VFrameFormat" BO_ 2565938419 1;
CM_ BO_ 2565938419 "电池组28-单体电压1 / 电池组28-单体电压2 | 信号数 4";
CM_ SG_ 2565938419 电池组28-单体电压1 "电池组28-单体电压1";
CM_ SG_ 2565938419 电池组28-单体电压2 "电池组28-单体电压2";
CM_ SG_ 2565938419 电池组28-单体电压3 "电池组28-单体电压3";
CM_ SG_ 2565938419 电池组28-单体电压4 "电池组28-单体电压4";

BO_ 2565938675 ZT_18F11DF3: 8 Vector__XXX
 SG_ 电池组29-单体电压1 : 0|16@1+ (0.001,0) [0|60] "V" Vector__XXX
 SG_ 电池组29-单体电压2 : 16|16@1+ (0.001,0) [0|60] "V" Vector__XXX
 SG_ 电池组29-单体电压3 : 32|16@1+ (0.001,0) [0|60] "V" Vector__XXX
 SG_ 电池组29-单体电压4 : 48|16@1+ (0.001,0) [0|60] "V" Vector__XXX

BA_ "VFrameFormat" BO_ 2565938675 1;
CM_ BO_ 2565938675 "电池组29-单体电压1 / 电池组29-单体电压2 | 信号数 4";
CM_ SG_ 2565938675 电池组29-单体电压1 "电池组29-单体电压1";
CM_ SG_ 2565938675 电池组29-单体电压2 "电池组29-单体电压2";
CM_ SG_ 2565938675 电池组29-单体电压3 "电池组29-单体电压3";
CM_ SG_ 2565938675 电池组29-单体电压4 "电池组29-单体电压4";

BO_ 2565938931 ZT_18F11EF3: 8 Vector__XXX
 SG_ 电池组30-单体电压1 : 0|16@1+ (0.001,0) [0|60] "V" Vector__XXX
 SG_ 电池组30-单体电压2 : 16|16@1+ (0.001,0) [0|60] "V" Vector__XXX
 SG_ 电池组30-单体电压3 : 32|16@1+ (0.001,0) [0|60] "V" Vector__XXX
 SG_ 电池组30-单体电压4 : 48|16@1+ (0.001,0) [0|60] "V" Vector__XXX

BA_ "VFrameFormat" BO_ 2565938931 1;
CM_ BO_ 2565938931 "电池组30-单体电压1 / 电池组30-单体电压2 | 信号数 4";
CM_ SG_ 2565938931 电池组30-单体电压1 "电池组30-单体电压1";
CM_ SG_ 2565938931 电池组30-单体电压2 "电池组30-单体电压2";
CM_ SG_ 2565938931 电池组30-单体电压3 "电池组30-单体电压3";
CM_ SG_ 2565938931 电池组30-单体电压4 "电池组30-单体电压4";

BO_ 2565939184 ZT_18F11FF0: 8 Vector__XXX
 SG_ 通讯协议版本 : 56|8@1+ (1,0) [0|255] "" Vector__XXX
 SG_ 电机系统当前控制模式 : 32|8@1+ (1,0) [0|255] "" Vector__XXX
 SG_ 控制器母线电流 : 16|16@1+ (0.1,-1000) [-1000|500] "A" Vector__XXX
 SG_ 控制器母线电压 : 0|16@1+ (0.1,0) [0|1000] "V" Vector__XXX

BA_ "VFrameFormat" BO_ 2565939184 1;
CM_ BO_ 2565939184 "控制器母线电压 / 控制器母线电流 | 信号数 4";
CM_ SG_ 2565939184 通讯协议版本 "通讯协议版本";
CM_ SG_ 2565939184 电机系统当前控制模式 "电机系统当前控制模式 [原始公式: if(((BYTE[4]>>2)&31)==0) 0; else if(((BYTE[4]>>2)&31)==1) 1; else if(((BYTE[4]>>2)&31)==2) 2; else if(((BYTE[4]>>2)&31)==3) 3; else if(((BYTE[4]>>2)&31)==10) 4; else if(((BYTE[4]>>2)&31)==18) 5; else if(((BYTE[4]>>2)&31)==26) 6; else 7] [枚举: 关闭|错误模式|零转矩模式|转速模式|制动模式|前进模式|倒车模式|预留]";
CM_ SG_ 2565939184 控制器母线电流 "控制器母线电流";
CM_ SG_ 2565939184 控制器母线电压 "控制器母线电压";

BO_ 2565939187 ZT_18F11FF3: 8 Vector__XXX
 SG_ 电池组31-单体电压1 : 0|16@1+ (0.001,0) [0|60] "V" Vector__XXX
 SG_ 电池组31-单体电压2 : 16|16@1+ (0.001,0) [0|60] "V" Vector__XXX
 SG_ 电池组31-单体电压3 : 32|16@1+ (0.001,0) [0|60] "V" Vector__XXX
 SG_ 电池组31-单体电压4 : 48|16@1+ (0.001,0) [0|60] "V" Vector__XXX

BA_ "VFrameFormat" BO_ 2565939187 1;
CM_ BO_ 2565939187 "电池组31-单体电压1 / 电池组31-单体电压2 | 信号数 4";
CM_ SG_ 2565939187 电池组31-单体电压1 "电池组31-单体电压1";
CM_ SG_ 2565939187 电池组31-单体电压2 "电池组31-单体电压2";
CM_ SG_ 2565939187 电池组31-单体电压3 "电池组31-单体电压3";
CM_ SG_ 2565939187 电池组31-单体电压4 "电池组31-单体电压4";

BO_ 2565939440 ZT_18F120F0: 8 Vector__XXX
 SG_ 电机温度 : 48|8@1+ (1,-40) [-40|215] "℃" Vector__XXX
 SG_ 电机控制器温度 : 56|8@1+ (1,-40) [-40|215] "℃" Vector__XXX
 SG_ 电机最大可用力矩 : 0|16@1+ (0.1,-3000) [-3000|3000] "Nm" Vector__XXX
 SG_ 电机当前转速 : 16|16@1+ (1,-12000) [-12000|12000] "rpm" Vector__XXX
 SG_ 电机实际转矩 : 32|16@1+ (0.1,-3000) [-3000|3000] "Nm" Vector__XXX

BA_ "VFrameFormat" BO_ 2565939440 1;
CM_ BO_ 2565939440 "电机实际转矩 / 电机当前转速 | 信号数 5";
CM_ SG_ 2565939440 电机温度 "电机温度";
CM_ SG_ 2565939440 电机控制器温度 "电机控制器温度";
CM_ SG_ 2565939440 电机最大可用力矩 "电机最大可用力矩";
CM_ SG_ 2565939440 电机当前转速 "电机当前转速";
CM_ SG_ 2565939440 电机实际转矩 "电机实际转矩";

BO_ 2565939443 ZT_18F120F3: 8 Vector__XXX
 SG_ 电池组32-单体电压1 : 0|16@1+ (0.001,0) [0|60] "V" Vector__XXX
 SG_ 电池组32-单体电压2 : 16|16@1+ (0.001,0) [0|60] "V" Vector__XXX
 SG_ 电池组32-单体电压3 : 32|16@1+ (0.001,0) [0|60] "V" Vector__XXX
 SG_ 电池组32-单体电压4 : 48|16@1+ (0.001,0) [0|60] "V" Vector__XXX

BA_ "VFrameFormat" BO_ 2565939443 1;
CM_ BO_ 2565939443 "电池组32-单体电压1 / 电池组32-单体电压2 | 信号数 4";
CM_ SG_ 2565939443 电池组32-单体电压1 "电池组32-单体电压1";
CM_ SG_ 2565939443 电池组32-单体电压2 "电池组32-单体电压2";
CM_ SG_ 2565939443 电池组32-单体电压3 "电池组32-单体电压3";
CM_ SG_ 2565939443 电池组32-单体电压4 "电池组32-单体电压4";

BO_ 2565939696 ZT_18F121F0: 8 Vector__XXX
 SG_ 电机控制器状态1-启动状态 : 24|1@1+ (1,0) [0|1] "" Vector__XXX
 SG_ 电机控制器状态2-怠速 : 25|1@1+ (1,0) [0|1] "" Vector__XXX
 SG_ 电机控制器状态3-行驶方向 : 26|1@1+ (1,0) [0|1] "" Vector__XXX
 SG_ 电机控制器状态4-驱动状态 : 27|1@1+ (1,0) [0|1] "" Vector__XXX
 SG_ 电机控制器系统状态 : 0|8@1+ (1,0) [0|255] "" Vector__XXX
 SG_ 电控故障代码 : 8|8@1+ (1,0) [0|255] "" Vector__XXX
 SG_ 电机控制器请求下高压 : 16|8@1+ (1,0) [0|255] "" Vector__XXX
 SG_ MCU次版本号 : 56|8@1+ (1,0) [0|255] "" Vector__XXX
 SG_ MCU程序主版本号 : 40|16@1+ (1,0) [0|65535] "" Vector__XXX

BA_ "VFrameFormat" BO_ 2565939696 1;
CM_ BO_ 2565939696 "MCU次版本号 / MCU程序主版本号 | 信号数 10";
CM_ SG_ 2565939696 电机控制器状态1-启动状态 "电机控制器状态1-启动状态 [枚举: 停机|启动]";
VAL_ 2565939696 电机控制器状态1-启动状态 0 "停机" 1 "启动";
CM_ SG_ 2565939696 电机控制器状态2-怠速 "电机控制器状态2-怠速 [枚举: 怠速无效|怠速有效]";
VAL_ 2565939696 电机控制器状态2-怠速 0 "怠速无效" 1 "怠速有效";
CM_ SG_ 2565939696 电机控制器状态3-行驶方向 "电机控制器状态3-行驶方向 [枚举: 向后|向前]";
VAL_ 2565939696 电机控制器状态3-行驶方向 0 "向后" 1 "向前";
CM_ SG_ 2565939696 电机控制器状态4-驱动状态 "电机控制器状态4-驱动状态 [枚举: 制动|驱动]";
VAL_ 2565939696 电机控制器状态4-驱动状态 0 "制动" 1 "驱动";
CM_ SG_ 2565939696 电机控制器系统状态 "电机控制器系统状态 [枚举: 停止|运行中|报警|故障]";
VAL_ 2565939696 电机控制器系统状态 0 "停止" 1 "运行中" 2 "报警" 3 "故障";
CM_ SG_ 2565939696 电控故障代码 "电控故障代码";
CM_ SG_ 2565939696 电机控制器请求下高压 "电机控制器请求下高压 [原始公式: if((BYTE[2])==85) 0; else if((BYTE[2])==170) 1; else 2] [枚举: 无请求|有请求|预留]";
CM_ SG_ 2565939696 MCU次版本号 "MCU次版本号";
CM_ SG_ 2565939696 MCU程序主版本号 "MCU程序主版本号";

BO_ 2565939699 ZT_18F121F3: 8 Vector__XXX
 SG_ 电池组33-单体电压1 : 0|16@1+ (0.001,0) [0|60] "V" Vector__XXX
 SG_ 电池组33-单体电压2 : 16|16@1+ (0.001,0) [0|60] "V" Vector__XXX
 SG_ 电池组33-单体电压3 : 32|16@1+ (0.001,0) [0|60] "V" Vector__XXX
 SG_ 电池组33-单体电压4 : 48|16@1+ (0.001,0) [0|60] "V" Vector__XXX

BA_ "VFrameFormat" BO_ 2565939699 1;
CM_ BO_ 2565939699 "电池组33-单体电压1 / 电池组33-单体电压2 | 信号数 4";
CM_ SG_ 2565939699 电池组33-单体电压1 "电池组33-单体电压1";
CM_ SG_ 2565939699 电池组33-单体电压2 "电池组33-单体电压2";
CM_ SG_ 2565939699 电池组33-单体电压3 "电池组33-单体电压3";
CM_ SG_ 2565939699 电池组33-单体电压4 "电池组33-单体电压4";

BO_ 2565939952 ZT_18F122F0: 8 Vector__XXX
 SG_ 月-1 : 7|4@1+ (1,0) [0|12] "" Vector__XXX
 SG_ 日-1 : 11|5@1+ (1,0) [0|31] "" Vector__XXX
 SG_ 年-1 : 0|7@1+ (1,0) [0|255] "" Vector__XXX

BA_ "VFrameFormat" BO_ 2565939952 1;
CM_ BO_ 2565939952 "年-1 / 日-1 | 信号数 3";
CM_ SG_ 2565939952 月-1 "月-1";
CM_ SG_ 2565939952 日-1 "日-1";
CM_ SG_ 2565939952 年-1 "年-1";

BO_ 2565939955 ZT_18F122F3: 8 Vector__XXX
 SG_ 电池组34-单体电压1 : 0|16@1+ (0.001,0) [0|60] "V" Vector__XXX
 SG_ 电池组34-单体电压2 : 16|16@1+ (0.001,0) [0|60] "V" Vector__XXX
 SG_ 电池组34-单体电压3 : 32|16@1+ (0.001,0) [0|60] "V" Vector__XXX
 SG_ 电池组34-单体电压4 : 48|16@1+ (0.001,0) [0|60] "V" Vector__XXX

BA_ "VFrameFormat" BO_ 2565939955 1;
CM_ BO_ 2565939955 "电池组34-单体电压1 / 电池组34-单体电压2 | 信号数 4";
CM_ SG_ 2565939955 电池组34-单体电压1 "电池组34-单体电压1";
CM_ SG_ 2565939955 电池组34-单体电压2 "电池组34-单体电压2";
CM_ SG_ 2565939955 电池组34-单体电压3 "电池组34-单体电压3";
CM_ SG_ 2565939955 电池组34-单体电压4 "电池组34-单体电压4";

BO_ 2565940211 ZT_18F123F3: 8 Vector__XXX
 SG_ 电池组35-单体电压1 : 0|16@1+ (0.001,0) [0|60] "V" Vector__XXX
 SG_ 电池组35-单体电压2 : 16|16@1+ (0.001,0) [0|60] "V" Vector__XXX
 SG_ 电池组35-单体电压3 : 32|16@1+ (0.001,0) [0|60] "V" Vector__XXX
 SG_ 电池组35-单体电压4 : 48|16@1+ (0.001,0) [0|60] "V" Vector__XXX

BA_ "VFrameFormat" BO_ 2565940211 1;
CM_ BO_ 2565940211 "电池组35-单体电压1 / 电池组35-单体电压2 | 信号数 4";
CM_ SG_ 2565940211 电池组35-单体电压1 "电池组35-单体电压1";
CM_ SG_ 2565940211 电池组35-单体电压2 "电池组35-单体电压2";
CM_ SG_ 2565940211 电池组35-单体电压3 "电池组35-单体电压3";
CM_ SG_ 2565940211 电池组35-单体电压4 "电池组35-单体电压4";

BO_ 2565940467 ZT_18F124F3: 8 Vector__XXX
 SG_ 电池组36-单体电压1 : 0|16@1+ (0.001,0) [0|60] "V" Vector__XXX
 SG_ 电池组36-单体电压2 : 16|16@1+ (0.001,0) [0|60] "V" Vector__XXX
 SG_ 电池组36-单体电压3 : 32|16@1+ (0.001,0) [0|60] "V" Vector__XXX
 SG_ 电池组36-单体电压4 : 48|16@1+ (0.001,0) [0|60] "V" Vector__XXX

BA_ "VFrameFormat" BO_ 2565940467 1;
CM_ BO_ 2565940467 "电池组36-单体电压1 / 电池组36-单体电压2 | 信号数 4";
CM_ SG_ 2565940467 电池组36-单体电压1 "电池组36-单体电压1";
CM_ SG_ 2565940467 电池组36-单体电压2 "电池组36-单体电压2";
CM_ SG_ 2565940467 电池组36-单体电压3 "电池组36-单体电压3";
CM_ SG_ 2565940467 电池组36-单体电压4 "电池组36-单体电压4";

BO_ 2565940723 ZT_18F125F3: 8 Vector__XXX
 SG_ 电池组37-单体电压1 : 0|16@1+ (0.001,0) [0|60] "V" Vector__XXX
 SG_ 电池组37-单体电压2 : 16|16@1+ (0.001,0) [0|60] "V" Vector__XXX
 SG_ 电池组37-单体电压3 : 32|16@1+ (0.001,0) [0|60] "V" Vector__XXX
 SG_ 电池组37-单体电压4 : 48|16@1+ (0.001,0) [0|60] "V" Vector__XXX

BA_ "VFrameFormat" BO_ 2565940723 1;
CM_ BO_ 2565940723 "电池组37-单体电压1 / 电池组37-单体电压2 | 信号数 4";
CM_ SG_ 2565940723 电池组37-单体电压1 "电池组37-单体电压1";
CM_ SG_ 2565940723 电池组37-单体电压2 "电池组37-单体电压2";
CM_ SG_ 2565940723 电池组37-单体电压3 "电池组37-单体电压3";
CM_ SG_ 2565940723 电池组37-单体电压4 "电池组37-单体电压4";

BO_ 2565940979 ZT_18F126F3: 8 Vector__XXX
 SG_ 电池组38-单体电压1 : 0|16@1+ (0.001,0) [0|60] "V" Vector__XXX
 SG_ 电池组38-单体电压2 : 16|16@1+ (0.001,0) [0|60] "V" Vector__XXX
 SG_ 电池组38-单体电压3 : 32|16@1+ (0.001,0) [0|60] "V" Vector__XXX
 SG_ 电池组38-单体电压4 : 48|16@1+ (0.001,0) [0|60] "V" Vector__XXX

BA_ "VFrameFormat" BO_ 2565940979 1;
CM_ BO_ 2565940979 "电池组38-单体电压1 / 电池组38-单体电压2 | 信号数 4";
CM_ SG_ 2565940979 电池组38-单体电压1 "电池组38-单体电压1";
CM_ SG_ 2565940979 电池组38-单体电压2 "电池组38-单体电压2";
CM_ SG_ 2565940979 电池组38-单体电压3 "电池组38-单体电压3";
CM_ SG_ 2565940979 电池组38-单体电压4 "电池组38-单体电压4";

BO_ 2565941235 ZT_18F127F3: 8 Vector__XXX
 SG_ 电池组77-单体电压3 : 32|16@1+ (0.001,0) [0|60] "V" Vector__XXX
 SG_ 电池组77-单体电压4 : 48|16@1+ (0.001,0) [0|60] "V" Vector__XXX
 SG_ 电池组78-单体电压1 : 0|16@1+ (0.001,0) [0|60] "V" Vector__XXX
 SG_ 电池组78-单体电压2 : 16|16@1+ (0.001,0) [0|60] "V" Vector__XXX

BA_ "VFrameFormat" BO_ 2565941235 1;
CM_ BO_ 2565941235 "电池组39-单体电压1 / 电池组39-单体电压2 | 信号数 10";
CM_ SG_ 2565941235 电池组77-单体电压3 "电池组77-单体电压3";
CM_ SG_ 2565941235 电池组77-单体电压4 "电池组77-单体电压4";
CM_ SG_ 2565941235 电池组78-单体电压1 "电池组78-单体电压1";
CM_ SG_ 2565941235 电池组78-单体电压2 "电池组78-单体电压2";

BO_ 2565941491 ZT_18F128F3: 8 Vector__XXX
 SG_ 电池组79-单体电压1 : 0|16@1+ (0.001,0) [0|60] "V" Vector__XXX
 SG_ 电池组79-单体电压2 : 16|16@1+ (0.001,0) [0|60] "V" Vector__XXX
 SG_ 电池组79-单体电压3 : 32|16@1+ (0.001,0) [0|60] "V" Vector__XXX
 SG_ 电池组79-单体电压4 : 48|16@1+ (0.001,0) [0|60] "V" Vector__XXX

BA_ "VFrameFormat" BO_ 2565941491 1;
CM_ BO_ 2565941491 "电池组40-单体电压1 / 电池组40-单体电压2 | 信号数 12";
CM_ SG_ 2565941491 电池组79-单体电压1 "电池组79-单体电压1";
CM_ SG_ 2565941491 电池组79-单体电压2 "电池组79-单体电压2";
CM_ SG_ 2565941491 电池组79-单体电压3 "电池组79-单体电压3";
CM_ SG_ 2565941491 电池组79-单体电压4 "电池组79-单体电压4";

BO_ 2565941747 ZT_18F129F3: 8 Vector__XXX
 SG_ 电池组81-单体电压1 : 0|16@1+ (0.001,0) [0|60] "V" Vector__XXX
 SG_ 电池组81-单体电压2 : 16|16@1+ (0.001,0) [0|60] "V" Vector__XXX
 SG_ 电池组81-单体电压3 : 32|16@1+ (0.001,0) [0|60] "V" Vector__XXX
 SG_ 电池组81-单体电压4 : 48|16@1+ (0.001,0) [0|60] "V" Vector__XXX

BA_ "VFrameFormat" BO_ 2565941747 1;
CM_ BO_ 2565941747 "电池组41-单体电压1 / 电池组41-单体电压2 | 信号数 12";
CM_ SG_ 2565941747 电池组81-单体电压1 "电池组81-单体电压1";
CM_ SG_ 2565941747 电池组81-单体电压2 "电池组81-单体电压2";
CM_ SG_ 2565941747 电池组81-单体电压3 "电池组81-单体电压3";
CM_ SG_ 2565941747 电池组81-单体电压4 "电池组81-单体电压4";

BO_ 2565942003 ZT_18F12AF3: 8 Vector__XXX
 SG_ 电池组83-单体电压1 : 0|16@1+ (0.001,0) [0|60] "V" Vector__XXX
 SG_ 电池组83-单体电压2 : 16|16@1+ (0.001,0) [0|60] "V" Vector__XXX
 SG_ 电池组83-单体电压3 : 32|16@1+ (0.001,0) [0|60] "V" Vector__XXX
 SG_ 电池组83-单体电压4 : 48|16@1+ (0.001,0) [0|60] "V" Vector__XXX

BA_ "VFrameFormat" BO_ 2565942003 1;
CM_ BO_ 2565942003 "电池组42-单体电压1 / 电池组42-单体电压2 | 信号数 12";
CM_ SG_ 2565942003 电池组83-单体电压1 "电池组83-单体电压1";
CM_ SG_ 2565942003 电池组83-单体电压2 "电池组83-单体电压2";
CM_ SG_ 2565942003 电池组83-单体电压3 "电池组83-单体电压3";
CM_ SG_ 2565942003 电池组83-单体电压4 "电池组83-单体电压4";

BO_ 2565942259 ZT_18F12BF3: 8 Vector__XXX
 SG_ 电池组85-单体电压1 : 0|16@1+ (0.001,0) [0|60] "V" Vector__XXX
 SG_ 电池组85-单体电压2 : 16|16@1+ (0.001,0) [0|60] "V" Vector__XXX
 SG_ 电池组85-单体电压3 : 32|16@1+ (0.001,0) [0|60] "V" Vector__XXX
 SG_ 电池组85-单体电压4 : 48|16@1+ (0.001,0) [0|60] "V" Vector__XXX

BA_ "VFrameFormat" BO_ 2565942259 1;
CM_ BO_ 2565942259 "电池组43-单体电压1 / 电池组43-单体电压2 | 信号数 12";
CM_ SG_ 2565942259 电池组85-单体电压1 "电池组85-单体电压1";
CM_ SG_ 2565942259 电池组85-单体电压2 "电池组85-单体电压2";
CM_ SG_ 2565942259 电池组85-单体电压3 "电池组85-单体电压3";
CM_ SG_ 2565942259 电池组85-单体电压4 "电池组85-单体电压4";

BO_ 2565942515 ZT_18F12CF3: 8 Vector__XXX
 SG_ 电池组87-单体电压1 : 0|16@1+ (0.001,0) [0|60] "V" Vector__XXX
 SG_ 电池组87-单体电压2 : 16|16@1+ (0.001,0) [0|60] "V" Vector__XXX
 SG_ 电池组87-单体电压3 : 32|16@1+ (0.001,0) [0|60] "V" Vector__XXX
 SG_ 电池组87-单体电压4 : 48|16@1+ (0.001,0) [0|60] "V" Vector__XXX

BA_ "VFrameFormat" BO_ 2565942515 1;
CM_ BO_ 2565942515 "电池组44-单体电压1 / 电池组44-单体电压2 | 信号数 12";
CM_ SG_ 2565942515 电池组87-单体电压1 "电池组87-单体电压1";
CM_ SG_ 2565942515 电池组87-单体电压2 "电池组87-单体电压2";
CM_ SG_ 2565942515 电池组87-单体电压3 "电池组87-单体电压3";
CM_ SG_ 2565942515 电池组87-单体电压4 "电池组87-单体电压4";

BO_ 2565942771 ZT_18F12DF3: 8 Vector__XXX
 SG_ 电池组90-单体电压1 : 0|16@1+ (0.001,0) [0|60] "V" Vector__XXX
 SG_ 电池组90-单体电压2 : 16|16@1+ (0.001,0) [0|60] "V" Vector__XXX
 SG_ 电池组90-单体电压3 : 32|16@1+ (0.001,0) [0|60] "V" Vector__XXX
 SG_ 电池组90-单体电压4 : 48|16@1+ (0.001,0) [0|60] "V" Vector__XXX

BA_ "VFrameFormat" BO_ 2565942771 1;
CM_ BO_ 2565942771 "电池组45-单体电压1 / 电池组45-单体电压2 | 信号数 12";
CM_ SG_ 2565942771 电池组90-单体电压1 "电池组90-单体电压1";
CM_ SG_ 2565942771 电池组90-单体电压2 "电池组90-单体电压2";
CM_ SG_ 2565942771 电池组90-单体电压3 "电池组90-单体电压3";
CM_ SG_ 2565942771 电池组90-单体电压4 "电池组90-单体电压4";

BO_ 2565943027 ZT_18F12EF3: 8 Vector__XXX
 SG_ 电池组92-单体电压1 : 0|16@1+ (0.001,0) [0|60] "V" Vector__XXX
 SG_ 电池组92-单体电压2 : 16|16@1+ (0.001,0) [0|60] "V" Vector__XXX
 SG_ 电池组92-单体电压3 : 32|16@1+ (0.001,0) [0|60] "V" Vector__XXX
 SG_ 电池组92-单体电压4 : 48|16@1+ (0.001,0) [0|60] "V" Vector__XXX

BA_ "VFrameFormat" BO_ 2565943027 1;
CM_ BO_ 2565943027 "电池组46-单体电压1 / 电池组46-单体电压2 | 信号数 12";
CM_ SG_ 2565943027 电池组92-单体电压1 "电池组92-单体电压1";
CM_ SG_ 2565943027 电池组92-单体电压2 "电池组92-单体电压2";
CM_ SG_ 2565943027 电池组92-单体电压3 "电池组92-单体电压3";
CM_ SG_ 2565943027 电池组92-单体电压4 "电池组92-单体电压4";

BO_ 2565943283 ZT_18F12FF3: 8 Vector__XXX
 SG_ 电池组94-单体电压1 : 0|16@1+ (0.001,0) [0|60] "V" Vector__XXX
 SG_ 电池组94-单体电压2 : 16|16@1+ (0.001,0) [0|60] "V" Vector__XXX
 SG_ 电池组94-单体电压3 : 32|16@1+ (0.001,0) [0|60] "V" Vector__XXX
 SG_ 电池组94-单体电压4 : 48|16@1+ (0.001,0) [0|60] "V" Vector__XXX

BA_ "VFrameFormat" BO_ 2565943283 1;
CM_ BO_ 2565943283 "电池组47-单体电压1 / 电池组47-单体电压2 | 信号数 12";
CM_ SG_ 2565943283 电池组94-单体电压1 "电池组94-单体电压1";
CM_ SG_ 2565943283 电池组94-单体电压2 "电池组94-单体电压2";
CM_ SG_ 2565943283 电池组94-单体电压3 "电池组94-单体电压3";
CM_ SG_ 2565943283 电池组94-单体电压4 "电池组94-单体电压4";

BO_ 2565943539 ZT_18F130F3: 8 Vector__XXX
 SG_ 电池组49-单体电压1 : 0|16@1+ (0.001,0) [0|60] "V" Vector__XXX

BA_ "VFrameFormat" BO_ 2565943539 1;
CM_ BO_ 2565943539 "电池组49-单体电压1 | 信号数 1";
CM_ SG_ 2565943539 电池组49-单体电压1 "电池组49-单体电压1";

BO_ 2565943795 ZT_UNKNOWN_18F131F3: 8 Vector__XXX
 SG_ 字节0 : 0|8@1+ (1,0) [0|255] "" Vector__XXX
 SG_ 字节1 : 8|8@1+ (1,0) [0|255] "" Vector__XXX
 SG_ 字节2 : 16|8@1+ (1,0) [0|255] "" Vector__XXX
 SG_ 字节3 : 24|8@1+ (1,0) [0|255] "" Vector__XXX
 SG_ 字节4 : 32|8@1+ (1,0) [0|255] "" Vector__XXX
 SG_ 字节5 : 40|8@1+ (1,0) [0|255] "" Vector__XXX
 SG_ 字节6 : 48|8@1+ (1,0) [0|255] "" Vector__XXX
 SG_ 字节7 : 56|8@1+ (1,0) [0|255] "" Vector__XXX

BA_ "VFrameFormat" BO_ 2565943795 1;
CM_ BO_ 2565943795 "电池管理系统 | 无信号定义, 按原始字节输出";
CM_ SG_ 2565943795 字节0 "字节0（原始值，无信号定义）";
CM_ SG_ 2565943795 字节1 "字节1（原始值，无信号定义）";
CM_ SG_ 2565943795 字节2 "字节2（原始值，无信号定义）";
CM_ SG_ 2565943795 字节3 "字节3（原始值，无信号定义）";
CM_ SG_ 2565943795 字节4 "字节4（原始值，无信号定义）";
CM_ SG_ 2565943795 字节5 "字节5（原始值，无信号定义）";
CM_ SG_ 2565943795 字节6 "字节6（原始值，无信号定义）";
CM_ SG_ 2565943795 字节7 "字节7（原始值，无信号定义）";

BO_ 2565944051 ZT_UNKNOWN_18F132F3: 8 Vector__XXX
 SG_ 字节0 : 0|8@1+ (1,0) [0|255] "" Vector__XXX
 SG_ 字节1 : 8|8@1+ (1,0) [0|255] "" Vector__XXX
 SG_ 字节2 : 16|8@1+ (1,0) [0|255] "" Vector__XXX
 SG_ 字节3 : 24|8@1+ (1,0) [0|255] "" Vector__XXX
 SG_ 字节4 : 32|8@1+ (1,0) [0|255] "" Vector__XXX
 SG_ 字节5 : 40|8@1+ (1,0) [0|255] "" Vector__XXX
 SG_ 字节6 : 48|8@1+ (1,0) [0|255] "" Vector__XXX
 SG_ 字节7 : 56|8@1+ (1,0) [0|255] "" Vector__XXX

BA_ "VFrameFormat" BO_ 2565944051 1;
CM_ BO_ 2565944051 "电池管理系统 | 无信号定义, 按原始字节输出";
CM_ SG_ 2565944051 字节0 "字节0（原始值，无信号定义）";
CM_ SG_ 2565944051 字节1 "字节1（原始值，无信号定义）";
CM_ SG_ 2565944051 字节2 "字节2（原始值，无信号定义）";
CM_ SG_ 2565944051 字节3 "字节3（原始值，无信号定义）";
CM_ SG_ 2565944051 字节4 "字节4（原始值，无信号定义）";
CM_ SG_ 2565944051 字节5 "字节5（原始值，无信号定义）";
CM_ SG_ 2565944051 字节6 "字节6（原始值，无信号定义）";
CM_ SG_ 2565944051 字节7 "字节7（原始值，无信号定义）";

BO_ 2565944307 ZT_UNKNOWN_18F133F3: 8 Vector__XXX
 SG_ 字节0 : 0|8@1+ (1,0) [0|255] "" Vector__XXX
 SG_ 字节1 : 8|8@1+ (1,0) [0|255] "" Vector__XXX
 SG_ 字节2 : 16|8@1+ (1,0) [0|255] "" Vector__XXX
 SG_ 字节3 : 24|8@1+ (1,0) [0|255] "" Vector__XXX
 SG_ 字节4 : 32|8@1+ (1,0) [0|255] "" Vector__XXX
 SG_ 字节5 : 40|8@1+ (1,0) [0|255] "" Vector__XXX
 SG_ 字节6 : 48|8@1+ (1,0) [0|255] "" Vector__XXX
 SG_ 字节7 : 56|8@1+ (1,0) [0|255] "" Vector__XXX

BA_ "VFrameFormat" BO_ 2565944307 1;
CM_ BO_ 2565944307 "电池管理系统 | 无信号定义, 按原始字节输出";
CM_ SG_ 2565944307 字节0 "字节0（原始值，无信号定义）";
CM_ SG_ 2565944307 字节1 "字节1（原始值，无信号定义）";
CM_ SG_ 2565944307 字节2 "字节2（原始值，无信号定义）";
CM_ SG_ 2565944307 字节3 "字节3（原始值，无信号定义）";
CM_ SG_ 2565944307 字节4 "字节4（原始值，无信号定义）";
CM_ SG_ 2565944307 字节5 "字节5（原始值，无信号定义）";
CM_ SG_ 2565944307 字节6 "字节6（原始值，无信号定义）";
CM_ SG_ 2565944307 字节7 "字节7（原始值，无信号定义）";

BO_ 2565944563 ZT_UNKNOWN_18F134F3: 8 Vector__XXX
 SG_ 字节0 : 0|8@1+ (1,0) [0|255] "" Vector__XXX
 SG_ 字节1 : 8|8@1+ (1,0) [0|255] "" Vector__XXX
 SG_ 字节2 : 16|8@1+ (1,0) [0|255] "" Vector__XXX
 SG_ 字节3 : 24|8@1+ (1,0) [0|255] "" Vector__XXX
 SG_ 字节4 : 32|8@1+ (1,0) [0|255] "" Vector__XXX
 SG_ 字节5 : 40|8@1+ (1,0) [0|255] "" Vector__XXX
 SG_ 字节6 : 48|8@1+ (1,0) [0|255] "" Vector__XXX
 SG_ 字节7 : 56|8@1+ (1,0) [0|255] "" Vector__XXX

BA_ "VFrameFormat" BO_ 2565944563 1;
CM_ BO_ 2565944563 "电池管理系统 | 无信号定义, 按原始字节输出";
CM_ SG_ 2565944563 字节0 "字节0（原始值，无信号定义）";
CM_ SG_ 2565944563 字节1 "字节1（原始值，无信号定义）";
CM_ SG_ 2565944563 字节2 "字节2（原始值，无信号定义）";
CM_ SG_ 2565944563 字节3 "字节3（原始值，无信号定义）";
CM_ SG_ 2565944563 字节4 "字节4（原始值，无信号定义）";
CM_ SG_ 2565944563 字节5 "字节5（原始值，无信号定义）";
CM_ SG_ 2565944563 字节6 "字节6（原始值，无信号定义）";
CM_ SG_ 2565944563 字节7 "字节7（原始值，无信号定义）";

BO_ 2565944819 ZT_UNKNOWN_18F135F3: 8 Vector__XXX
 SG_ 字节0 : 0|8@1+ (1,0) [0|255] "" Vector__XXX
 SG_ 字节1 : 8|8@1+ (1,0) [0|255] "" Vector__XXX
 SG_ 字节2 : 16|8@1+ (1,0) [0|255] "" Vector__XXX
 SG_ 字节3 : 24|8@1+ (1,0) [0|255] "" Vector__XXX
 SG_ 字节4 : 32|8@1+ (1,0) [0|255] "" Vector__XXX
 SG_ 字节5 : 40|8@1+ (1,0) [0|255] "" Vector__XXX
 SG_ 字节6 : 48|8@1+ (1,0) [0|255] "" Vector__XXX
 SG_ 字节7 : 56|8@1+ (1,0) [0|255] "" Vector__XXX

BA_ "VFrameFormat" BO_ 2565944819 1;
CM_ BO_ 2565944819 "电池管理系统 | 无信号定义, 按原始字节输出";
CM_ SG_ 2565944819 字节0 "字节0（原始值，无信号定义）";
CM_ SG_ 2565944819 字节1 "字节1（原始值，无信号定义）";
CM_ SG_ 2565944819 字节2 "字节2（原始值，无信号定义）";
CM_ SG_ 2565944819 字节3 "字节3（原始值，无信号定义）";
CM_ SG_ 2565944819 字节4 "字节4（原始值，无信号定义）";
CM_ SG_ 2565944819 字节5 "字节5（原始值，无信号定义）";
CM_ SG_ 2565944819 字节6 "字节6（原始值，无信号定义）";
CM_ SG_ 2565944819 字节7 "字节7（原始值，无信号定义）";

BO_ 2565945075 ZT_UNKNOWN_18F136F3: 8 Vector__XXX
 SG_ 字节0 : 0|8@1+ (1,0) [0|255] "" Vector__XXX
 SG_ 字节1 : 8|8@1+ (1,0) [0|255] "" Vector__XXX
 SG_ 字节2 : 16|8@1+ (1,0) [0|255] "" Vector__XXX
 SG_ 字节3 : 24|8@1+ (1,0) [0|255] "" Vector__XXX
 SG_ 字节4 : 32|8@1+ (1,0) [0|255] "" Vector__XXX
 SG_ 字节5 : 40|8@1+ (1,0) [0|255] "" Vector__XXX
 SG_ 字节6 : 48|8@1+ (1,0) [0|255] "" Vector__XXX
 SG_ 字节7 : 56|8@1+ (1,0) [0|255] "" Vector__XXX

BA_ "VFrameFormat" BO_ 2565945075 1;
CM_ BO_ 2565945075 "电池管理系统 | 无信号定义, 按原始字节输出";
CM_ SG_ 2565945075 字节0 "字节0（原始值，无信号定义）";
CM_ SG_ 2565945075 字节1 "字节1（原始值，无信号定义）";
CM_ SG_ 2565945075 字节2 "字节2（原始值，无信号定义）";
CM_ SG_ 2565945075 字节3 "字节3（原始值，无信号定义）";
CM_ SG_ 2565945075 字节4 "字节4（原始值，无信号定义）";
CM_ SG_ 2565945075 字节5 "字节5（原始值，无信号定义）";
CM_ SG_ 2565945075 字节6 "字节6（原始值，无信号定义）";
CM_ SG_ 2565945075 字节7 "字节7（原始值，无信号定义）";

BO_ 2565945331 ZT_UNKNOWN_18F137F3: 8 Vector__XXX
 SG_ 字节0 : 0|8@1+ (1,0) [0|255] "" Vector__XXX
 SG_ 字节1 : 8|8@1+ (1,0) [0|255] "" Vector__XXX
 SG_ 字节2 : 16|8@1+ (1,0) [0|255] "" Vector__XXX
 SG_ 字节3 : 24|8@1+ (1,0) [0|255] "" Vector__XXX
 SG_ 字节4 : 32|8@1+ (1,0) [0|255] "" Vector__XXX
 SG_ 字节5 : 40|8@1+ (1,0) [0|255] "" Vector__XXX
 SG_ 字节6 : 48|8@1+ (1,0) [0|255] "" Vector__XXX
 SG_ 字节7 : 56|8@1+ (1,0) [0|255] "" Vector__XXX

BA_ "VFrameFormat" BO_ 2565945331 1;
CM_ BO_ 2565945331 "电池管理系统 | 无信号定义, 按原始字节输出";
CM_ SG_ 2565945331 字节0 "字节0（原始值，无信号定义）";
CM_ SG_ 2565945331 字节1 "字节1（原始值，无信号定义）";
CM_ SG_ 2565945331 字节2 "字节2（原始值，无信号定义）";
CM_ SG_ 2565945331 字节3 "字节3（原始值，无信号定义）";
CM_ SG_ 2565945331 字节4 "字节4（原始值，无信号定义）";
CM_ SG_ 2565945331 字节5 "字节5（原始值，无信号定义）";
CM_ SG_ 2565945331 字节6 "字节6（原始值，无信号定义）";
CM_ SG_ 2565945331 字节7 "字节7（原始值，无信号定义）";

BO_ 2565945587 ZT_UNKNOWN_18F138F3: 8 Vector__XXX
 SG_ 字节0 : 0|8@1+ (1,0) [0|255] "" Vector__XXX
 SG_ 字节1 : 8|8@1+ (1,0) [0|255] "" Vector__XXX
 SG_ 字节2 : 16|8@1+ (1,0) [0|255] "" Vector__XXX
 SG_ 字节3 : 24|8@1+ (1,0) [0|255] "" Vector__XXX
 SG_ 字节4 : 32|8@1+ (1,0) [0|255] "" Vector__XXX
 SG_ 字节5 : 40|8@1+ (1,0) [0|255] "" Vector__XXX
 SG_ 字节6 : 48|8@1+ (1,0) [0|255] "" Vector__XXX
 SG_ 字节7 : 56|8@1+ (1,0) [0|255] "" Vector__XXX

BA_ "VFrameFormat" BO_ 2565945587 1;
CM_ BO_ 2565945587 "电池管理系统 | 无信号定义, 按原始字节输出";
CM_ SG_ 2565945587 字节0 "字节0（原始值，无信号定义）";
CM_ SG_ 2565945587 字节1 "字节1（原始值，无信号定义）";
CM_ SG_ 2565945587 字节2 "字节2（原始值，无信号定义）";
CM_ SG_ 2565945587 字节3 "字节3（原始值，无信号定义）";
CM_ SG_ 2565945587 字节4 "字节4（原始值，无信号定义）";
CM_ SG_ 2565945587 字节5 "字节5（原始值，无信号定义）";
CM_ SG_ 2565945587 字节6 "字节6（原始值，无信号定义）";
CM_ SG_ 2565945587 字节7 "字节7（原始值，无信号定义）";

BO_ 2565945843 ZT_UNKNOWN_18F139F3: 8 Vector__XXX
 SG_ 字节0 : 0|8@1+ (1,0) [0|255] "" Vector__XXX
 SG_ 字节1 : 8|8@1+ (1,0) [0|255] "" Vector__XXX
 SG_ 字节2 : 16|8@1+ (1,0) [0|255] "" Vector__XXX
 SG_ 字节3 : 24|8@1+ (1,0) [0|255] "" Vector__XXX
 SG_ 字节4 : 32|8@1+ (1,0) [0|255] "" Vector__XXX
 SG_ 字节5 : 40|8@1+ (1,0) [0|255] "" Vector__XXX
 SG_ 字节6 : 48|8@1+ (1,0) [0|255] "" Vector__XXX
 SG_ 字节7 : 56|8@1+ (1,0) [0|255] "" Vector__XXX

BA_ "VFrameFormat" BO_ 2565945843 1;
CM_ BO_ 2565945843 "电池管理系统 | 无信号定义, 按原始字节输出";
CM_ SG_ 2565945843 字节0 "字节0（原始值，无信号定义）";
CM_ SG_ 2565945843 字节1 "字节1（原始值，无信号定义）";
CM_ SG_ 2565945843 字节2 "字节2（原始值，无信号定义）";
CM_ SG_ 2565945843 字节3 "字节3（原始值，无信号定义）";
CM_ SG_ 2565945843 字节4 "字节4（原始值，无信号定义）";
CM_ SG_ 2565945843 字节5 "字节5（原始值，无信号定义）";
CM_ SG_ 2565945843 字节6 "字节6（原始值，无信号定义）";
CM_ SG_ 2565945843 字节7 "字节7（原始值，无信号定义）";

BO_ 2565946099 ZT_UNKNOWN_18F13AF3: 8 Vector__XXX
 SG_ 字节0 : 0|8@1+ (1,0) [0|255] "" Vector__XXX
 SG_ 字节1 : 8|8@1+ (1,0) [0|255] "" Vector__XXX
 SG_ 字节2 : 16|8@1+ (1,0) [0|255] "" Vector__XXX
 SG_ 字节3 : 24|8@1+ (1,0) [0|255] "" Vector__XXX
 SG_ 字节4 : 32|8@1+ (1,0) [0|255] "" Vector__XXX
 SG_ 字节5 : 40|8@1+ (1,0) [0|255] "" Vector__XXX
 SG_ 字节6 : 48|8@1+ (1,0) [0|255] "" Vector__XXX
 SG_ 字节7 : 56|8@1+ (1,0) [0|255] "" Vector__XXX

BA_ "VFrameFormat" BO_ 2565946099 1;
CM_ BO_ 2565946099 "电池管理系统 | 无信号定义, 按原始字节输出";
CM_ SG_ 2565946099 字节0 "字节0（原始值，无信号定义）";
CM_ SG_ 2565946099 字节1 "字节1（原始值，无信号定义）";
CM_ SG_ 2565946099 字节2 "字节2（原始值，无信号定义）";
CM_ SG_ 2565946099 字节3 "字节3（原始值，无信号定义）";
CM_ SG_ 2565946099 字节4 "字节4（原始值，无信号定义）";
CM_ SG_ 2565946099 字节5 "字节5（原始值，无信号定义）";
CM_ SG_ 2565946099 字节6 "字节6（原始值，无信号定义）";
CM_ SG_ 2565946099 字节7 "字节7（原始值，无信号定义）";

BO_ 2565946355 ZT_UNKNOWN_18F13BF3: 8 Vector__XXX
 SG_ 字节0 : 0|8@1+ (1,0) [0|255] "" Vector__XXX
 SG_ 字节1 : 8|8@1+ (1,0) [0|255] "" Vector__XXX
 SG_ 字节2 : 16|8@1+ (1,0) [0|255] "" Vector__XXX
 SG_ 字节3 : 24|8@1+ (1,0) [0|255] "" Vector__XXX
 SG_ 字节4 : 32|8@1+ (1,0) [0|255] "" Vector__XXX
 SG_ 字节5 : 40|8@1+ (1,0) [0|255] "" Vector__XXX
 SG_ 字节6 : 48|8@1+ (1,0) [0|255] "" Vector__XXX
 SG_ 字节7 : 56|8@1+ (1,0) [0|255] "" Vector__XXX

BA_ "VFrameFormat" BO_ 2565946355 1;
CM_ BO_ 2565946355 "电池管理系统 | 无信号定义, 按原始字节输出";
CM_ SG_ 2565946355 字节0 "字节0（原始值，无信号定义）";
CM_ SG_ 2565946355 字节1 "字节1（原始值，无信号定义）";
CM_ SG_ 2565946355 字节2 "字节2（原始值，无信号定义）";
CM_ SG_ 2565946355 字节3 "字节3（原始值，无信号定义）";
CM_ SG_ 2565946355 字节4 "字节4（原始值，无信号定义）";
CM_ SG_ 2565946355 字节5 "字节5（原始值，无信号定义）";
CM_ SG_ 2565946355 字节6 "字节6（原始值，无信号定义）";
CM_ SG_ 2565946355 字节7 "字节7（原始值，无信号定义）";

BO_ 2565946611 ZT_UNKNOWN_18F13CF3: 8 Vector__XXX
 SG_ 字节0 : 0|8@1+ (1,0) [0|255] "" Vector__XXX
 SG_ 字节1 : 8|8@1+ (1,0) [0|255] "" Vector__XXX
 SG_ 字节2 : 16|8@1+ (1,0) [0|255] "" Vector__XXX
 SG_ 字节3 : 24|8@1+ (1,0) [0|255] "" Vector__XXX
 SG_ 字节4 : 32|8@1+ (1,0) [0|255] "" Vector__XXX
 SG_ 字节5 : 40|8@1+ (1,0) [0|255] "" Vector__XXX
 SG_ 字节6 : 48|8@1+ (1,0) [0|255] "" Vector__XXX
 SG_ 字节7 : 56|8@1+ (1,0) [0|255] "" Vector__XXX

BA_ "VFrameFormat" BO_ 2565946611 1;
CM_ BO_ 2565946611 "电池管理系统 | 无信号定义, 按原始字节输出";
CM_ SG_ 2565946611 字节0 "字节0（原始值，无信号定义）";
CM_ SG_ 2565946611 字节1 "字节1（原始值，无信号定义）";
CM_ SG_ 2565946611 字节2 "字节2（原始值，无信号定义）";
CM_ SG_ 2565946611 字节3 "字节3（原始值，无信号定义）";
CM_ SG_ 2565946611 字节4 "字节4（原始值，无信号定义）";
CM_ SG_ 2565946611 字节5 "字节5（原始值，无信号定义）";
CM_ SG_ 2565946611 字节6 "字节6（原始值，无信号定义）";
CM_ SG_ 2565946611 字节7 "字节7（原始值，无信号定义）";

BO_ 2565946867 ZT_UNKNOWN_18F13DF3: 8 Vector__XXX
 SG_ 字节0 : 0|8@1+ (1,0) [0|255] "" Vector__XXX
 SG_ 字节1 : 8|8@1+ (1,0) [0|255] "" Vector__XXX
 SG_ 字节2 : 16|8@1+ (1,0) [0|255] "" Vector__XXX
 SG_ 字节3 : 24|8@1+ (1,0) [0|255] "" Vector__XXX
 SG_ 字节4 : 32|8@1+ (1,0) [0|255] "" Vector__XXX
 SG_ 字节5 : 40|8@1+ (1,0) [0|255] "" Vector__XXX
 SG_ 字节6 : 48|8@1+ (1,0) [0|255] "" Vector__XXX
 SG_ 字节7 : 56|8@1+ (1,0) [0|255] "" Vector__XXX

BA_ "VFrameFormat" BO_ 2565946867 1;
CM_ BO_ 2565946867 "电池管理系统 | 无信号定义, 按原始字节输出";
CM_ SG_ 2565946867 字节0 "字节0（原始值，无信号定义）";
CM_ SG_ 2565946867 字节1 "字节1（原始值，无信号定义）";
CM_ SG_ 2565946867 字节2 "字节2（原始值，无信号定义）";
CM_ SG_ 2565946867 字节3 "字节3（原始值，无信号定义）";
CM_ SG_ 2565946867 字节4 "字节4（原始值，无信号定义）";
CM_ SG_ 2565946867 字节5 "字节5（原始值，无信号定义）";
CM_ SG_ 2565946867 字节6 "字节6（原始值，无信号定义）";
CM_ SG_ 2565946867 字节7 "字节7（原始值，无信号定义）";

BO_ 2565947123 ZT_UNKNOWN_18F13EF3: 8 Vector__XXX
 SG_ 字节0 : 0|8@1+ (1,0) [0|255] "" Vector__XXX
 SG_ 字节1 : 8|8@1+ (1,0) [0|255] "" Vector__XXX
 SG_ 字节2 : 16|8@1+ (1,0) [0|255] "" Vector__XXX
 SG_ 字节3 : 24|8@1+ (1,0) [0|255] "" Vector__XXX
 SG_ 字节4 : 32|8@1+ (1,0) [0|255] "" Vector__XXX
 SG_ 字节5 : 40|8@1+ (1,0) [0|255] "" Vector__XXX
 SG_ 字节6 : 48|8@1+ (1,0) [0|255] "" Vector__XXX
 SG_ 字节7 : 56|8@1+ (1,0) [0|255] "" Vector__XXX

BA_ "VFrameFormat" BO_ 2565947123 1;
CM_ BO_ 2565947123 "电池管理系统 | 无信号定义, 按原始字节输出";
CM_ SG_ 2565947123 字节0 "字节0（原始值，无信号定义）";
CM_ SG_ 2565947123 字节1 "字节1（原始值，无信号定义）";
CM_ SG_ 2565947123 字节2 "字节2（原始值，无信号定义）";
CM_ SG_ 2565947123 字节3 "字节3（原始值，无信号定义）";
CM_ SG_ 2565947123 字节4 "字节4（原始值，无信号定义）";
CM_ SG_ 2565947123 字节5 "字节5（原始值，无信号定义）";
CM_ SG_ 2565947123 字节6 "字节6（原始值，无信号定义）";
CM_ SG_ 2565947123 字节7 "字节7（原始值，无信号定义）";

BO_ 2565947379 ZT_UNKNOWN_18F13FF3: 8 Vector__XXX
 SG_ 字节0 : 0|8@1+ (1,0) [0|255] "" Vector__XXX
 SG_ 字节1 : 8|8@1+ (1,0) [0|255] "" Vector__XXX
 SG_ 字节2 : 16|8@1+ (1,0) [0|255] "" Vector__XXX
 SG_ 字节3 : 24|8@1+ (1,0) [0|255] "" Vector__XXX
 SG_ 字节4 : 32|8@1+ (1,0) [0|255] "" Vector__XXX
 SG_ 字节5 : 40|8@1+ (1,0) [0|255] "" Vector__XXX
 SG_ 字节6 : 48|8@1+ (1,0) [0|255] "" Vector__XXX
 SG_ 字节7 : 56|8@1+ (1,0) [0|255] "" Vector__XXX

BA_ "VFrameFormat" BO_ 2565947379 1;
CM_ BO_ 2565947379 "电池管理系统 | 无信号定义, 按原始字节输出";
CM_ SG_ 2565947379 字节0 "字节0（原始值，无信号定义）";
CM_ SG_ 2565947379 字节1 "字节1（原始值，无信号定义）";
CM_ SG_ 2565947379 字节2 "字节2（原始值，无信号定义）";
CM_ SG_ 2565947379 字节3 "字节3（原始值，无信号定义）";
CM_ SG_ 2565947379 字节4 "字节4（原始值，无信号定义）";
CM_ SG_ 2565947379 字节5 "字节5（原始值，无信号定义）";
CM_ SG_ 2565947379 字节6 "字节6（原始值，无信号定义）";
CM_ SG_ 2565947379 字节7 "字节7（原始值，无信号定义）";

BO_ 2565947635 ZT_UNKNOWN_18F140F3: 8 Vector__XXX
 SG_ 字节0 : 0|8@1+ (1,0) [0|255] "" Vector__XXX
 SG_ 字节1 : 8|8@1+ (1,0) [0|255] "" Vector__XXX
 SG_ 字节2 : 16|8@1+ (1,0) [0|255] "" Vector__XXX
 SG_ 字节3 : 24|8@1+ (1,0) [0|255] "" Vector__XXX
 SG_ 字节4 : 32|8@1+ (1,0) [0|255] "" Vector__XXX
 SG_ 字节5 : 40|8@1+ (1,0) [0|255] "" Vector__XXX
 SG_ 字节6 : 48|8@1+ (1,0) [0|255] "" Vector__XXX
 SG_ 字节7 : 56|8@1+ (1,0) [0|255] "" Vector__XXX

BA_ "VFrameFormat" BO_ 2565947635 1;
CM_ BO_ 2565947635 "电池管理系统 | 无信号定义, 按原始字节输出";
CM_ SG_ 2565947635 字节0 "字节0（原始值，无信号定义）";
CM_ SG_ 2565947635 字节1 "字节1（原始值，无信号定义）";
CM_ SG_ 2565947635 字节2 "字节2（原始值，无信号定义）";
CM_ SG_ 2565947635 字节3 "字节3（原始值，无信号定义）";
CM_ SG_ 2565947635 字节4 "字节4（原始值，无信号定义）";
CM_ SG_ 2565947635 字节5 "字节5（原始值，无信号定义）";
CM_ SG_ 2565947635 字节6 "字节6（原始值，无信号定义）";
CM_ SG_ 2565947635 字节7 "字节7（原始值，无信号定义）";

BO_ 2565947891 ZT_UNKNOWN_18F141F3: 8 Vector__XXX
 SG_ 字节0 : 0|8@1+ (1,0) [0|255] "" Vector__XXX
 SG_ 字节1 : 8|8@1+ (1,0) [0|255] "" Vector__XXX
 SG_ 字节2 : 16|8@1+ (1,0) [0|255] "" Vector__XXX
 SG_ 字节3 : 24|8@1+ (1,0) [0|255] "" Vector__XXX
 SG_ 字节4 : 32|8@1+ (1,0) [0|255] "" Vector__XXX
 SG_ 字节5 : 40|8@1+ (1,0) [0|255] "" Vector__XXX
 SG_ 字节6 : 48|8@1+ (1,0) [0|255] "" Vector__XXX
 SG_ 字节7 : 56|8@1+ (1,0) [0|255] "" Vector__XXX

BA_ "VFrameFormat" BO_ 2565947891 1;
CM_ BO_ 2565947891 "电池管理系统 | 无信号定义, 按原始字节输出";
CM_ SG_ 2565947891 字节0 "字节0（原始值，无信号定义）";
CM_ SG_ 2565947891 字节1 "字节1（原始值，无信号定义）";
CM_ SG_ 2565947891 字节2 "字节2（原始值，无信号定义）";
CM_ SG_ 2565947891 字节3 "字节3（原始值，无信号定义）";
CM_ SG_ 2565947891 字节4 "字节4（原始值，无信号定义）";
CM_ SG_ 2565947891 字节5 "字节5（原始值，无信号定义）";
CM_ SG_ 2565947891 字节6 "字节6（原始值，无信号定义）";
CM_ SG_ 2565947891 字节7 "字节7（原始值，无信号定义）";

BO_ 2565948147 ZT_UNKNOWN_18F142F3: 8 Vector__XXX
 SG_ 字节0 : 0|8@1+ (1,0) [0|255] "" Vector__XXX
 SG_ 字节1 : 8|8@1+ (1,0) [0|255] "" Vector__XXX
 SG_ 字节2 : 16|8@1+ (1,0) [0|255] "" Vector__XXX
 SG_ 字节3 : 24|8@1+ (1,0) [0|255] "" Vector__XXX
 SG_ 字节4 : 32|8@1+ (1,0) [0|255] "" Vector__XXX
 SG_ 字节5 : 40|8@1+ (1,0) [0|255] "" Vector__XXX
 SG_ 字节6 : 48|8@1+ (1,0) [0|255] "" Vector__XXX
 SG_ 字节7 : 56|8@1+ (1,0) [0|255] "" Vector__XXX

BA_ "VFrameFormat" BO_ 2565948147 1;
CM_ BO_ 2565948147 "电池管理系统 | 无信号定义, 按原始字节输出";
CM_ SG_ 2565948147 字节0 "字节0（原始值，无信号定义）";
CM_ SG_ 2565948147 字节1 "字节1（原始值，无信号定义）";
CM_ SG_ 2565948147 字节2 "字节2（原始值，无信号定义）";
CM_ SG_ 2565948147 字节3 "字节3（原始值，无信号定义）";
CM_ SG_ 2565948147 字节4 "字节4（原始值，无信号定义）";
CM_ SG_ 2565948147 字节5 "字节5（原始值，无信号定义）";
CM_ SG_ 2565948147 字节6 "字节6（原始值，无信号定义）";
CM_ SG_ 2565948147 字节7 "字节7（原始值，无信号定义）";

BO_ 2565948403 ZT_UNKNOWN_18F143F3: 8 Vector__XXX
 SG_ 字节0 : 0|8@1+ (1,0) [0|255] "" Vector__XXX
 SG_ 字节1 : 8|8@1+ (1,0) [0|255] "" Vector__XXX
 SG_ 字节2 : 16|8@1+ (1,0) [0|255] "" Vector__XXX
 SG_ 字节3 : 24|8@1+ (1,0) [0|255] "" Vector__XXX
 SG_ 字节4 : 32|8@1+ (1,0) [0|255] "" Vector__XXX
 SG_ 字节5 : 40|8@1+ (1,0) [0|255] "" Vector__XXX
 SG_ 字节6 : 48|8@1+ (1,0) [0|255] "" Vector__XXX
 SG_ 字节7 : 56|8@1+ (1,0) [0|255] "" Vector__XXX

BA_ "VFrameFormat" BO_ 2565948403 1;
CM_ BO_ 2565948403 "电池管理系统 | 无信号定义, 按原始字节输出";
CM_ SG_ 2565948403 字节0 "字节0（原始值，无信号定义）";
CM_ SG_ 2565948403 字节1 "字节1（原始值，无信号定义）";
CM_ SG_ 2565948403 字节2 "字节2（原始值，无信号定义）";
CM_ SG_ 2565948403 字节3 "字节3（原始值，无信号定义）";
CM_ SG_ 2565948403 字节4 "字节4（原始值，无信号定义）";
CM_ SG_ 2565948403 字节5 "字节5（原始值，无信号定义）";
CM_ SG_ 2565948403 字节6 "字节6（原始值，无信号定义）";
CM_ SG_ 2565948403 字节7 "字节7（原始值，无信号定义）";

BO_ 2565948659 ZT_UNKNOWN_18F144F3: 8 Vector__XXX
 SG_ 字节0 : 0|8@1+ (1,0) [0|255] "" Vector__XXX
 SG_ 字节1 : 8|8@1+ (1,0) [0|255] "" Vector__XXX
 SG_ 字节2 : 16|8@1+ (1,0) [0|255] "" Vector__XXX
 SG_ 字节3 : 24|8@1+ (1,0) [0|255] "" Vector__XXX
 SG_ 字节4 : 32|8@1+ (1,0) [0|255] "" Vector__XXX
 SG_ 字节5 : 40|8@1+ (1,0) [0|255] "" Vector__XXX
 SG_ 字节6 : 48|8@1+ (1,0) [0|255] "" Vector__XXX
 SG_ 字节7 : 56|8@1+ (1,0) [0|255] "" Vector__XXX

BA_ "VFrameFormat" BO_ 2565948659 1;
CM_ BO_ 2565948659 "电池管理系统 | 无信号定义, 按原始字节输出";
CM_ SG_ 2565948659 字节0 "字节0（原始值，无信号定义）";
CM_ SG_ 2565948659 字节1 "字节1（原始值，无信号定义）";
CM_ SG_ 2565948659 字节2 "字节2（原始值，无信号定义）";
CM_ SG_ 2565948659 字节3 "字节3（原始值，无信号定义）";
CM_ SG_ 2565948659 字节4 "字节4（原始值，无信号定义）";
CM_ SG_ 2565948659 字节5 "字节5（原始值，无信号定义）";
CM_ SG_ 2565948659 字节6 "字节6（原始值，无信号定义）";
CM_ SG_ 2565948659 字节7 "字节7（原始值，无信号定义）";

BO_ 2565948915 ZT_UNKNOWN_18F145F3: 8 Vector__XXX
 SG_ 字节0 : 0|8@1+ (1,0) [0|255] "" Vector__XXX
 SG_ 字节1 : 8|8@1+ (1,0) [0|255] "" Vector__XXX
 SG_ 字节2 : 16|8@1+ (1,0) [0|255] "" Vector__XXX
 SG_ 字节3 : 24|8@1+ (1,0) [0|255] "" Vector__XXX
 SG_ 字节4 : 32|8@1+ (1,0) [0|255] "" Vector__XXX
 SG_ 字节5 : 40|8@1+ (1,0) [0|255] "" Vector__XXX
 SG_ 字节6 : 48|8@1+ (1,0) [0|255] "" Vector__XXX
 SG_ 字节7 : 56|8@1+ (1,0) [0|255] "" Vector__XXX

BA_ "VFrameFormat" BO_ 2565948915 1;
CM_ BO_ 2565948915 "电池管理系统 | 无信号定义, 按原始字节输出";
CM_ SG_ 2565948915 字节0 "字节0（原始值，无信号定义）";
CM_ SG_ 2565948915 字节1 "字节1（原始值，无信号定义）";
CM_ SG_ 2565948915 字节2 "字节2（原始值，无信号定义）";
CM_ SG_ 2565948915 字节3 "字节3（原始值，无信号定义）";
CM_ SG_ 2565948915 字节4 "字节4（原始值，无信号定义）";
CM_ SG_ 2565948915 字节5 "字节5（原始值，无信号定义）";
CM_ SG_ 2565948915 字节6 "字节6（原始值，无信号定义）";
CM_ SG_ 2565948915 字节7 "字节7（原始值，无信号定义）";

BO_ 2565949171 ZT_UNKNOWN_18F146F3: 8 Vector__XXX
 SG_ 字节0 : 0|8@1+ (1,0) [0|255] "" Vector__XXX
 SG_ 字节1 : 8|8@1+ (1,0) [0|255] "" Vector__XXX
 SG_ 字节2 : 16|8@1+ (1,0) [0|255] "" Vector__XXX
 SG_ 字节3 : 24|8@1+ (1,0) [0|255] "" Vector__XXX
 SG_ 字节4 : 32|8@1+ (1,0) [0|255] "" Vector__XXX
 SG_ 字节5 : 40|8@1+ (1,0) [0|255] "" Vector__XXX
 SG_ 字节6 : 48|8@1+ (1,0) [0|255] "" Vector__XXX
 SG_ 字节7 : 56|8@1+ (1,0) [0|255] "" Vector__XXX

BA_ "VFrameFormat" BO_ 2565949171 1;
CM_ BO_ 2565949171 "电池管理系统 | 无信号定义, 按原始字节输出";
CM_ SG_ 2565949171 字节0 "字节0（原始值，无信号定义）";
CM_ SG_ 2565949171 字节1 "字节1（原始值，无信号定义）";
CM_ SG_ 2565949171 字节2 "字节2（原始值，无信号定义）";
CM_ SG_ 2565949171 字节3 "字节3（原始值，无信号定义）";
CM_ SG_ 2565949171 字节4 "字节4（原始值，无信号定义）";
CM_ SG_ 2565949171 字节5 "字节5（原始值，无信号定义）";
CM_ SG_ 2565949171 字节6 "字节6（原始值，无信号定义）";
CM_ SG_ 2565949171 字节7 "字节7（原始值，无信号定义）";

BO_ 2565949427 ZT_UNKNOWN_18F147F3: 8 Vector__XXX
 SG_ 字节0 : 0|8@1+ (1,0) [0|255] "" Vector__XXX
 SG_ 字节1 : 8|8@1+ (1,0) [0|255] "" Vector__XXX
 SG_ 字节2 : 16|8@1+ (1,0) [0|255] "" Vector__XXX
 SG_ 字节3 : 24|8@1+ (1,0) [0|255] "" Vector__XXX
 SG_ 字节4 : 32|8@1+ (1,0) [0|255] "" Vector__XXX
 SG_ 字节5 : 40|8@1+ (1,0) [0|255] "" Vector__XXX
 SG_ 字节6 : 48|8@1+ (1,0) [0|255] "" Vector__XXX
 SG_ 字节7 : 56|8@1+ (1,0) [0|255] "" Vector__XXX

BA_ "VFrameFormat" BO_ 2565949427 1;
CM_ BO_ 2565949427 "电池管理系统 | 无信号定义, 按原始字节输出";
CM_ SG_ 2565949427 字节0 "字节0（原始值，无信号定义）";
CM_ SG_ 2565949427 字节1 "字节1（原始值，无信号定义）";
CM_ SG_ 2565949427 字节2 "字节2（原始值，无信号定义）";
CM_ SG_ 2565949427 字节3 "字节3（原始值，无信号定义）";
CM_ SG_ 2565949427 字节4 "字节4（原始值，无信号定义）";
CM_ SG_ 2565949427 字节5 "字节5（原始值，无信号定义）";
CM_ SG_ 2565949427 字节6 "字节6（原始值，无信号定义）";
CM_ SG_ 2565949427 字节7 "字节7（原始值，无信号定义）";

BO_ 2565949683 ZT_UNKNOWN_18F148F3: 8 Vector__XXX
 SG_ 字节0 : 0|8@1+ (1,0) [0|255] "" Vector__XXX
 SG_ 字节1 : 8|8@1+ (1,0) [0|255] "" Vector__XXX
 SG_ 字节2 : 16|8@1+ (1,0) [0|255] "" Vector__XXX
 SG_ 字节3 : 24|8@1+ (1,0) [0|255] "" Vector__XXX
 SG_ 字节4 : 32|8@1+ (1,0) [0|255] "" Vector__XXX
 SG_ 字节5 : 40|8@1+ (1,0) [0|255] "" Vector__XXX
 SG_ 字节6 : 48|8@1+ (1,0) [0|255] "" Vector__XXX
 SG_ 字节7 : 56|8@1+ (1,0) [0|255] "" Vector__XXX

BA_ "VFrameFormat" BO_ 2565949683 1;
CM_ BO_ 2565949683 "电池管理系统 | 无信号定义, 按原始字节输出";
CM_ SG_ 2565949683 字节0 "字节0（原始值，无信号定义）";
CM_ SG_ 2565949683 字节1 "字节1（原始值，无信号定义）";
CM_ SG_ 2565949683 字节2 "字节2（原始值，无信号定义）";
CM_ SG_ 2565949683 字节3 "字节3（原始值，无信号定义）";
CM_ SG_ 2565949683 字节4 "字节4（原始值，无信号定义）";
CM_ SG_ 2565949683 字节5 "字节5（原始值，无信号定义）";
CM_ SG_ 2565949683 字节6 "字节6（原始值，无信号定义）";
CM_ SG_ 2565949683 字节7 "字节7（原始值，无信号定义）";

BO_ 2565949939 ZT_UNKNOWN_18F149F3: 8 Vector__XXX
 SG_ 字节0 : 0|8@1+ (1,0) [0|255] "" Vector__XXX
 SG_ 字节1 : 8|8@1+ (1,0) [0|255] "" Vector__XXX
 SG_ 字节2 : 16|8@1+ (1,0) [0|255] "" Vector__XXX
 SG_ 字节3 : 24|8@1+ (1,0) [0|255] "" Vector__XXX
 SG_ 字节4 : 32|8@1+ (1,0) [0|255] "" Vector__XXX
 SG_ 字节5 : 40|8@1+ (1,0) [0|255] "" Vector__XXX
 SG_ 字节6 : 48|8@1+ (1,0) [0|255] "" Vector__XXX
 SG_ 字节7 : 56|8@1+ (1,0) [0|255] "" Vector__XXX

BA_ "VFrameFormat" BO_ 2565949939 1;
CM_ BO_ 2565949939 "电池管理系统 | 无信号定义, 按原始字节输出";
CM_ SG_ 2565949939 字节0 "字节0（原始值，无信号定义）";
CM_ SG_ 2565949939 字节1 "字节1（原始值，无信号定义）";
CM_ SG_ 2565949939 字节2 "字节2（原始值，无信号定义）";
CM_ SG_ 2565949939 字节3 "字节3（原始值，无信号定义）";
CM_ SG_ 2565949939 字节4 "字节4（原始值，无信号定义）";
CM_ SG_ 2565949939 字节5 "字节5（原始值，无信号定义）";
CM_ SG_ 2565949939 字节6 "字节6（原始值，无信号定义）";
CM_ SG_ 2565949939 字节7 "字节7（原始值，无信号定义）";

BO_ 2565950195 ZT_UNKNOWN_18F14AF3: 8 Vector__XXX
 SG_ 字节0 : 0|8@1+ (1,0) [0|255] "" Vector__XXX
 SG_ 字节1 : 8|8@1+ (1,0) [0|255] "" Vector__XXX
 SG_ 字节2 : 16|8@1+ (1,0) [0|255] "" Vector__XXX
 SG_ 字节3 : 24|8@1+ (1,0) [0|255] "" Vector__XXX
 SG_ 字节4 : 32|8@1+ (1,0) [0|255] "" Vector__XXX
 SG_ 字节5 : 40|8@1+ (1,0) [0|255] "" Vector__XXX
 SG_ 字节6 : 48|8@1+ (1,0) [0|255] "" Vector__XXX
 SG_ 字节7 : 56|8@1+ (1,0) [0|255] "" Vector__XXX

BA_ "VFrameFormat" BO_ 2565950195 1;
CM_ BO_ 2565950195 "电池管理系统 | 无信号定义, 按原始字节输出";
CM_ SG_ 2565950195 字节0 "字节0（原始值，无信号定义）";
CM_ SG_ 2565950195 字节1 "字节1（原始值，无信号定义）";
CM_ SG_ 2565950195 字节2 "字节2（原始值，无信号定义）";
CM_ SG_ 2565950195 字节3 "字节3（原始值，无信号定义）";
CM_ SG_ 2565950195 字节4 "字节4（原始值，无信号定义）";
CM_ SG_ 2565950195 字节5 "字节5（原始值，无信号定义）";
CM_ SG_ 2565950195 字节6 "字节6（原始值，无信号定义）";
CM_ SG_ 2565950195 字节7 "字节7（原始值，无信号定义）";

BO_ 2565950451 ZT_UNKNOWN_18F14BF3: 8 Vector__XXX
 SG_ 字节0 : 0|8@1+ (1,0) [0|255] "" Vector__XXX
 SG_ 字节1 : 8|8@1+ (1,0) [0|255] "" Vector__XXX
 SG_ 字节2 : 16|8@1+ (1,0) [0|255] "" Vector__XXX
 SG_ 字节3 : 24|8@1+ (1,0) [0|255] "" Vector__XXX
 SG_ 字节4 : 32|8@1+ (1,0) [0|255] "" Vector__XXX
 SG_ 字节5 : 40|8@1+ (1,0) [0|255] "" Vector__XXX
 SG_ 字节6 : 48|8@1+ (1,0) [0|255] "" Vector__XXX
 SG_ 字节7 : 56|8@1+ (1,0) [0|255] "" Vector__XXX

BA_ "VFrameFormat" BO_ 2565950451 1;
CM_ BO_ 2565950451 "电池管理系统 | 无信号定义, 按原始字节输出";
CM_ SG_ 2565950451 字节0 "字节0（原始值，无信号定义）";
CM_ SG_ 2565950451 字节1 "字节1（原始值，无信号定义）";
CM_ SG_ 2565950451 字节2 "字节2（原始值，无信号定义）";
CM_ SG_ 2565950451 字节3 "字节3（原始值，无信号定义）";
CM_ SG_ 2565950451 字节4 "字节4（原始值，无信号定义）";
CM_ SG_ 2565950451 字节5 "字节5（原始值，无信号定义）";
CM_ SG_ 2565950451 字节6 "字节6（原始值，无信号定义）";
CM_ SG_ 2565950451 字节7 "字节7（原始值，无信号定义）";

BO_ 2565950707 ZT_UNKNOWN_18F14CF3: 8 Vector__XXX
 SG_ 字节0 : 0|8@1+ (1,0) [0|255] "" Vector__XXX
 SG_ 字节1 : 8|8@1+ (1,0) [0|255] "" Vector__XXX
 SG_ 字节2 : 16|8@1+ (1,0) [0|255] "" Vector__XXX
 SG_ 字节3 : 24|8@1+ (1,0) [0|255] "" Vector__XXX
 SG_ 字节4 : 32|8@1+ (1,0) [0|255] "" Vector__XXX
 SG_ 字节5 : 40|8@1+ (1,0) [0|255] "" Vector__XXX
 SG_ 字节6 : 48|8@1+ (1,0) [0|255] "" Vector__XXX
 SG_ 字节7 : 56|8@1+ (1,0) [0|255] "" Vector__XXX

BA_ "VFrameFormat" BO_ 2565950707 1;
CM_ BO_ 2565950707 "电池管理系统 | 无信号定义, 按原始字节输出";
CM_ SG_ 2565950707 字节0 "字节0（原始值，无信号定义）";
CM_ SG_ 2565950707 字节1 "字节1（原始值，无信号定义）";
CM_ SG_ 2565950707 字节2 "字节2（原始值，无信号定义）";
CM_ SG_ 2565950707 字节3 "字节3（原始值，无信号定义）";
CM_ SG_ 2565950707 字节4 "字节4（原始值，无信号定义）";
CM_ SG_ 2565950707 字节5 "字节5（原始值，无信号定义）";
CM_ SG_ 2565950707 字节6 "字节6（原始值，无信号定义）";
CM_ SG_ 2565950707 字节7 "字节7（原始值，无信号定义）";

BO_ 2565950963 ZT_UNKNOWN_18F14DF3: 8 Vector__XXX
 SG_ 字节0 : 0|8@1+ (1,0) [0|255] "" Vector__XXX
 SG_ 字节1 : 8|8@1+ (1,0) [0|255] "" Vector__XXX
 SG_ 字节2 : 16|8@1+ (1,0) [0|255] "" Vector__XXX
 SG_ 字节3 : 24|8@1+ (1,0) [0|255] "" Vector__XXX
 SG_ 字节4 : 32|8@1+ (1,0) [0|255] "" Vector__XXX
 SG_ 字节5 : 40|8@1+ (1,0) [0|255] "" Vector__XXX
 SG_ 字节6 : 48|8@1+ (1,0) [0|255] "" Vector__XXX
 SG_ 字节7 : 56|8@1+ (1,0) [0|255] "" Vector__XXX

BA_ "VFrameFormat" BO_ 2565950963 1;
CM_ BO_ 2565950963 "电池管理系统 | 无信号定义, 按原始字节输出";
CM_ SG_ 2565950963 字节0 "字节0（原始值，无信号定义）";
CM_ SG_ 2565950963 字节1 "字节1（原始值，无信号定义）";
CM_ SG_ 2565950963 字节2 "字节2（原始值，无信号定义）";
CM_ SG_ 2565950963 字节3 "字节3（原始值，无信号定义）";
CM_ SG_ 2565950963 字节4 "字节4（原始值，无信号定义）";
CM_ SG_ 2565950963 字节5 "字节5（原始值，无信号定义）";
CM_ SG_ 2565950963 字节6 "字节6（原始值，无信号定义）";
CM_ SG_ 2565950963 字节7 "字节7（原始值，无信号定义）";

BO_ 2565951219 ZT_UNKNOWN_18F14EF3: 8 Vector__XXX
 SG_ 字节0 : 0|8@1+ (1,0) [0|255] "" Vector__XXX
 SG_ 字节1 : 8|8@1+ (1,0) [0|255] "" Vector__XXX
 SG_ 字节2 : 16|8@1+ (1,0) [0|255] "" Vector__XXX
 SG_ 字节3 : 24|8@1+ (1,0) [0|255] "" Vector__XXX
 SG_ 字节4 : 32|8@1+ (1,0) [0|255] "" Vector__XXX
 SG_ 字节5 : 40|8@1+ (1,0) [0|255] "" Vector__XXX
 SG_ 字节6 : 48|8@1+ (1,0) [0|255] "" Vector__XXX
 SG_ 字节7 : 56|8@1+ (1,0) [0|255] "" Vector__XXX

BA_ "VFrameFormat" BO_ 2565951219 1;
CM_ BO_ 2565951219 "电池管理系统 | 无信号定义, 按原始字节输出";
CM_ SG_ 2565951219 字节0 "字节0（原始值，无信号定义）";
CM_ SG_ 2565951219 字节1 "字节1（原始值，无信号定义）";
CM_ SG_ 2565951219 字节2 "字节2（原始值，无信号定义）";
CM_ SG_ 2565951219 字节3 "字节3（原始值，无信号定义）";
CM_ SG_ 2565951219 字节4 "字节4（原始值，无信号定义）";
CM_ SG_ 2565951219 字节5 "字节5（原始值，无信号定义）";
CM_ SG_ 2565951219 字节6 "字节6（原始值，无信号定义）";
CM_ SG_ 2565951219 字节7 "字节7（原始值，无信号定义）";

BO_ 2565951475 ZT_18F14FF3: 8 Vector__XXX
 SG_ 电池组79-单体电压2 : 16|16@1+ (0.001,0) [0|60] "V" Vector__XXX
 SG_ 电池组79-单体电压3 : 32|16@1+ (0.001,0) [0|60] "V" Vector__XXX
 SG_ 电池组79-单体电压4 : 48|16@1+ (0.001,0) [0|60] "V" Vector__XXX

BA_ "VFrameFormat" BO_ 2565951475 1;
CM_ BO_ 2565951475 "电池组79-单体电压2 / 电池组79-单体电压3 | 信号数 3";
CM_ SG_ 2565951475 电池组79-单体电压2 "电池组79-单体电压2";
CM_ SG_ 2565951475 电池组79-单体电压3 "电池组79-单体电压3";
CM_ SG_ 2565951475 电池组79-单体电压4 "电池组79-单体电压4";

BO_ 2565951731 ZT_18F150F3: 8 Vector__XXX
 SG_ 电池组80-单体电压1 : 0|16@1+ (0.001,0) [0|60] "V" Vector__XXX
 SG_ 电池组80-单体电压2 : 16|16@1+ (0.001,0) [0|60] "V" Vector__XXX
 SG_ 电池组80-单体电压3 : 32|16@1+ (0.001,0) [0|60] "V" Vector__XXX
 SG_ 电池组80-单体电压4 : 48|16@1+ (0.001,0) [0|60] "V" Vector__XXX

BA_ "VFrameFormat" BO_ 2565951731 1;
CM_ BO_ 2565951731 "电池组80-单体电压1 / 电池组80-单体电压2 | 信号数 4";
CM_ SG_ 2565951731 电池组80-单体电压1 "电池组80-单体电压1";
CM_ SG_ 2565951731 电池组80-单体电压2 "电池组80-单体电压2";
CM_ SG_ 2565951731 电池组80-单体电压3 "电池组80-单体电压3";
CM_ SG_ 2565951731 电池组80-单体电压4 "电池组80-单体电压4";

BO_ 2565951987 ZT_18F151F3: 8 Vector__XXX
 SG_ 电池组81-单体电压1 : 0|16@1+ (0.001,0) [0|60] "V" Vector__XXX
 SG_ 电池组81-单体电压2 : 16|16@1+ (0.001,0) [0|60] "V" Vector__XXX
 SG_ 电池组81-单体电压3 : 32|16@1+ (0.001,0) [0|60] "V" Vector__XXX
 SG_ 电池组81-单体电压4 : 48|16@1+ (0.001,0) [0|60] "V" Vector__XXX

BA_ "VFrameFormat" BO_ 2565951987 1;
CM_ BO_ 2565951987 "电池组81-单体电压1 / 电池组81-单体电压2 | 信号数 4";
CM_ SG_ 2565951987 电池组81-单体电压1 "电池组81-单体电压1";
CM_ SG_ 2565951987 电池组81-单体电压2 "电池组81-单体电压2";
CM_ SG_ 2565951987 电池组81-单体电压3 "电池组81-单体电压3";
CM_ SG_ 2565951987 电池组81-单体电压4 "电池组81-单体电压4";

BO_ 2565997043 ZT_18F201F3: 8 Vector__XXX
 SG_ 单体温度 1 : 0|8@1+ (1,-40) [-40|210] "deg C" Vector__XXX
 SG_ 单体温度 2 : 8|8@1+ (1,-40) [-40|210] "deg C" Vector__XXX
 SG_ 单体温度 3 : 16|8@1+ (1,-40) [-40|210] "deg C" Vector__XXX
 SG_ 单体温度 4 : 24|8@1+ (1,-40) [-40|210] "deg C" Vector__XXX
 SG_ 单体温度 5 : 32|8@1+ (1,-40) [-40|210] "deg C" Vector__XXX
 SG_ 单体温度 6 : 40|8@1+ (1,-40) [-40|210] "deg C" Vector__XXX
 SG_ 单体温度 7 : 48|8@1+ (1,-40) [-40|210] "deg C" Vector__XXX
 SG_ 单体温度 8 : 56|8@1+ (1,-40) [-40|210] "deg C" Vector__XXX

BA_ "VFrameFormat" BO_ 2565997043 1;
CM_ BO_ 2565997043 "单体温度 1 / 单体温度 2 | 信号数 24";
CM_ SG_ 2565997043 单体温度 1 "单体温度 1";
CM_ SG_ 2565997043 单体温度 2 "单体温度 2";
CM_ SG_ 2565997043 单体温度 3 "单体温度 3";
CM_ SG_ 2565997043 单体温度 4 "单体温度 4";
CM_ SG_ 2565997043 单体温度 5 "单体温度 5";
CM_ SG_ 2565997043 单体温度 6 "单体温度 6";
CM_ SG_ 2565997043 单体温度 7 "单体温度 7";
CM_ SG_ 2565997043 单体温度 8 "单体温度 8";

BO_ 2565997299 ZT_18F202F3: 8 Vector__XXX
 SG_ 单体温度 9 : 0|8@1+ (1,-40) [-40|210] "deg C" Vector__XXX
 SG_ 单体温度 10 : 8|8@1+ (1,-40) [-40|210] "deg C" Vector__XXX
 SG_ 单体温度 11 : 16|8@1+ (1,-40) [-40|210] "deg C" Vector__XXX
 SG_ 单体温度 12 : 24|8@1+ (1,-40) [-40|210] "deg C" Vector__XXX
 SG_ 单体温度 13 : 32|8@1+ (1,-40) [-40|210] "deg C" Vector__XXX
 SG_ 单体温度 14 : 40|8@1+ (1,-40) [-40|210] "deg C" Vector__XXX
 SG_ 单体温度 15 : 48|8@1+ (1,-40) [-40|210] "deg C" Vector__XXX
 SG_ 单体温度 16 : 56|8@1+ (1,-40) [-40|210] "deg C" Vector__XXX

BA_ "VFrameFormat" BO_ 2565997299 1;
CM_ BO_ 2565997299 "单体温度 10 / 单体温度 11 | 信号数 24";
CM_ SG_ 2565997299 单体温度 9 "单体温度 9";
CM_ SG_ 2565997299 单体温度 10 "单体温度 10";
CM_ SG_ 2565997299 单体温度 11 "单体温度 11";
CM_ SG_ 2565997299 单体温度 12 "单体温度 12";
CM_ SG_ 2565997299 单体温度 13 "单体温度 13";
CM_ SG_ 2565997299 单体温度 14 "单体温度 14";
CM_ SG_ 2565997299 单体温度 15 "单体温度 15";
CM_ SG_ 2565997299 单体温度 16 "单体温度 16";

BO_ 2565997555 ZT_18F203F3: 8 Vector__XXX
 SG_ 单体温度 17 : 0|8@1+ (1,-40) [-40|210] "deg C" Vector__XXX
 SG_ 单体温度 18 : 8|8@1+ (1,-40) [-40|210] "deg C" Vector__XXX
 SG_ 单体温度 19 : 16|8@1+ (1,-40) [-40|210] "deg C" Vector__XXX
 SG_ 单体温度 20 : 24|8@1+ (1,-40) [-40|210] "deg C" Vector__XXX
 SG_ 单体温度 21 : 32|8@1+ (1,-40) [-40|210] "deg C" Vector__XXX
 SG_ 单体温度 22 : 40|8@1+ (1,-40) [-40|210] "deg C" Vector__XXX
 SG_ 单体温度 23 : 48|8@1+ (1,-40) [-40|210] "deg C" Vector__XXX
 SG_ 单体温度 24 : 56|8@1+ (1,-40) [-40|210] "deg C" Vector__XXX

BA_ "VFrameFormat" BO_ 2565997555 1;
CM_ BO_ 2565997555 "单体温度 17 / 单体温度 18 | 信号数 24";
CM_ SG_ 2565997555 单体温度 17 "单体温度 17";
CM_ SG_ 2565997555 单体温度 18 "单体温度 18";
CM_ SG_ 2565997555 单体温度 19 "单体温度 19";
CM_ SG_ 2565997555 单体温度 20 "单体温度 20";
CM_ SG_ 2565997555 单体温度 21 "单体温度 21";
CM_ SG_ 2565997555 单体温度 22 "单体温度 22";
CM_ SG_ 2565997555 单体温度 23 "单体温度 23";
CM_ SG_ 2565997555 单体温度 24 "单体温度 24";

BO_ 2565997811 ZT_18F204F3: 8 Vector__XXX
 SG_ 单体温度 25 : 0|8@1+ (1,-40) [-40|210] "deg C" Vector__XXX
 SG_ 单体温度 26 : 8|8@1+ (1,-40) [-40|210] "deg C" Vector__XXX
 SG_ 单体温度 27 : 16|8@1+ (1,-40) [-40|210] "deg C" Vector__XXX
 SG_ 单体温度 28 : 24|8@1+ (1,-40) [-40|210] "deg C" Vector__XXX
 SG_ 单体温度 29 : 32|8@1+ (1,-40) [-40|210] "deg C" Vector__XXX
 SG_ 单体温度 30 : 40|8@1+ (1,-40) [-40|210] "deg C" Vector__XXX
 SG_ 单体温度 31 : 48|8@1+ (1,-40) [-40|210] "deg C" Vector__XXX
 SG_ 单体温度 32 : 56|8@1+ (1,-40) [-40|210] "deg C" Vector__XXX

BA_ "VFrameFormat" BO_ 2565997811 1;
CM_ BO_ 2565997811 "单体温度 25 / 单体温度 26 | 信号数 16";
CM_ SG_ 2565997811 单体温度 25 "单体温度 25";
CM_ SG_ 2565997811 单体温度 26 "单体温度 26";
CM_ SG_ 2565997811 单体温度 27 "单体温度 27";
CM_ SG_ 2565997811 单体温度 28 "单体温度 28";
CM_ SG_ 2565997811 单体温度 29 "单体温度 29";
CM_ SG_ 2565997811 单体温度 30 "单体温度 30";
CM_ SG_ 2565997811 单体温度 31 "单体温度 31";
CM_ SG_ 2565997811 单体温度 32 "单体温度 32";

BO_ 2565998067 ZT_18F205F3: 8 Vector__XXX
 SG_ 单体温度 33 : 0|8@1+ (1,-40) [-40|210] "deg C" Vector__XXX
 SG_ 单体温度 34 : 8|8@1+ (1,-40) [-40|210] "deg C" Vector__XXX
 SG_ 单体温度 35 : 16|8@1+ (1,-40) [-40|210] "deg C" Vector__XXX
 SG_ 单体温度 36 : 24|8@1+ (1,-40) [-40|210] "deg C" Vector__XXX
 SG_ 单体温度 37 : 32|8@1+ (1,-40) [-40|210] "deg C" Vector__XXX
 SG_ 单体温度 38 : 40|8@1+ (1,-40) [-40|210] "deg C" Vector__XXX
 SG_ 单体温度 39 : 48|8@1+ (1,-40) [-40|210] "deg C" Vector__XXX
 SG_ 单体温度 40 : 56|8@1+ (1,-40) [-40|210] "deg C" Vector__XXX

BA_ "VFrameFormat" BO_ 2565998067 1;
CM_ BO_ 2565998067 "单体温度 33 / 单体温度 34 | 信号数 8";
CM_ SG_ 2565998067 单体温度 33 "单体温度 33";
CM_ SG_ 2565998067 单体温度 34 "单体温度 34";
CM_ SG_ 2565998067 单体温度 35 "单体温度 35";
CM_ SG_ 2565998067 单体温度 36 "单体温度 36";
CM_ SG_ 2565998067 单体温度 37 "单体温度 37";
CM_ SG_ 2565998067 单体温度 38 "单体温度 38";
CM_ SG_ 2565998067 单体温度 39 "单体温度 39";
CM_ SG_ 2565998067 单体温度 40 "单体温度 40";

BO_ 2565998323 ZT_18F206F3: 8 Vector__XXX
 SG_ 单体温度 41 : 0|8@1+ (1,-40) [-40|210] "deg C" Vector__XXX
 SG_ 单体温度 42 : 8|8@1+ (1,-40) [-40|210] "deg C" Vector__XXX
 SG_ 单体温度 43 : 16|8@1+ (1,-40) [-40|210] "deg C" Vector__XXX
 SG_ 单体温度 44 : 24|8@1+ (1,-40) [-40|210] "deg C" Vector__XXX
 SG_ 单体温度 45 : 32|8@1+ (1,-40) [-40|210] "deg C" Vector__XXX
 SG_ 单体温度 46 : 40|8@1+ (1,-40) [-40|210] "deg C" Vector__XXX
 SG_ 单体温度 47 : 48|8@1+ (1,-40) [-40|210] "deg C" Vector__XXX
 SG_ 单体温度 48 : 56|8@1+ (1,-40) [-40|210] "deg C" Vector__XXX

BA_ "VFrameFormat" BO_ 2565998323 1;
CM_ BO_ 2565998323 "单体温度 41 / 单体温度 42 | 信号数 8";
CM_ SG_ 2565998323 单体温度 41 "单体温度 41";
CM_ SG_ 2565998323 单体温度 42 "单体温度 42";
CM_ SG_ 2565998323 单体温度 43 "单体温度 43";
CM_ SG_ 2565998323 单体温度 44 "单体温度 44";
CM_ SG_ 2565998323 单体温度 45 "单体温度 45";
CM_ SG_ 2565998323 单体温度 46 "单体温度 46";
CM_ SG_ 2565998323 单体温度 47 "单体温度 47";
CM_ SG_ 2565998323 单体温度 48 "单体温度 48";

BO_ 2565998579 ZT_18F207F3: 8 Vector__XXX
 SG_ 单体温度 49 : 0|8@1+ (1,-40) [-40|210] "deg C" Vector__XXX
 SG_ 单体温度 50 : 8|8@1+ (1,-40) [-40|210] "deg C" Vector__XXX
 SG_ 单体温度 51 : 16|8@1+ (1,-40) [-40|210] "deg C" Vector__XXX
 SG_ 单体温度 52 : 24|8@1+ (1,-40) [-40|210] "deg C" Vector__XXX
 SG_ 单体温度 53 : 32|8@1+ (1,-40) [-40|210] "deg C" Vector__XXX
 SG_ 单体温度 54 : 40|8@1+ (1,-40) [-40|210] "deg C" Vector__XXX
 SG_ 单体温度 55 : 48|8@1+ (1,-40) [-40|210] "deg C" Vector__XXX
 SG_ 单体温度 56 : 56|8@1+ (1,-40) [-40|210] "deg C" Vector__XXX

BA_ "VFrameFormat" BO_ 2565998579 1;
CM_ BO_ 2565998579 "单体温度 49 / 单体温度 50 | 信号数 8";
CM_ SG_ 2565998579 单体温度 49 "单体温度 49";
CM_ SG_ 2565998579 单体温度 50 "单体温度 50";
CM_ SG_ 2565998579 单体温度 51 "单体温度 51";
CM_ SG_ 2565998579 单体温度 52 "单体温度 52";
CM_ SG_ 2565998579 单体温度 53 "单体温度 53";
CM_ SG_ 2565998579 单体温度 54 "单体温度 54";
CM_ SG_ 2565998579 单体温度 55 "单体温度 55";
CM_ SG_ 2565998579 单体温度 56 "单体温度 56";

BO_ 2565998835 ZT_18F208F3: 8 Vector__XXX
 SG_ 单体温度 57 : 0|8@1+ (1,-40) [-40|210] "deg C" Vector__XXX
 SG_ 单体温度 58 : 8|8@1+ (1,-40) [-40|210] "deg C" Vector__XXX
 SG_ 单体温度 59 : 16|8@1+ (1,-40) [-40|210] "deg C" Vector__XXX
 SG_ 单体温度 60 : 24|8@1+ (1,-40) [-40|210] "deg C" Vector__XXX

BA_ "VFrameFormat" BO_ 2565998835 1;
CM_ BO_ 2565998835 "单体温度 57 / 单体温度 58 | 信号数 4";
CM_ SG_ 2565998835 单体温度 57 "单体温度 57";
CM_ SG_ 2565998835 单体温度 58 "单体温度 58";
CM_ SG_ 2565998835 单体温度 59 "单体温度 59";
CM_ SG_ 2565998835 单体温度 60 "单体温度 60";

BO_ 2566000663 ZT_18F21017: 8 Vector__XXX
 SG_ 制动液位状态 : 0|1@1+ (1,0) [0|1] "" Vector__XXX
 SG_ 运动模式 : 8|1@1+ (1,0) [0|2] "" Vector__XXX

BA_ "VFrameFormat" BO_ 2566000663 1;
CM_ BO_ 2566000663 "制动液位状态 / 运动模式 | 信号数 3";
CM_ SG_ 2566000663 制动液位状态 "制动液位状态 [枚举: 制动液位正常|制动液位过低]";
VAL_ 2566000663 制动液位状态 0 "制动液位正常" 1 "制动液位过低";
CM_ SG_ 2566000663 运动模式 "运动模式 [枚举: 普通模式|运动模式]";
VAL_ 2566000663 运动模式 0 "普通模式" 1 "运动模式";

BO_ 2566127895 ZT_18F40117: 8 Vector__XXX
 SG_ 车辆状态-中门状态 : 8|1@1+ (1,0) [0|0] "" Vector__XXX
 SG_ 车辆状态-前门状态 : 9|1@1+ (1,0) [0|0] "" Vector__XXX
 SG_ 车辆状态-后舱门状态 : 10|1@1+ (1,0) [0|0] "" Vector__XXX
 SG_ 车辆状态-ON档信号 : 11|1@1+ (1,0) [0|0] "" Vector__XXX
 SG_ 车辆状态-START信号 : 12|1@1+ (1,0) [0|0] "" Vector__XXX
 SG_ 手刹状态 : 18|1@1+ (1,0) [0|0] "" Vector__XXX
 SG_ STOP(强制停车)状态 : 19|1@1+ (1,0) [0|0] "" Vector__XXX
 SG_ 制动故障报警 : 16|2@1+ (1,0) [0|0] "" Vector__XXX
 SG_ 低压电池电压 : 0|8@1+ (0.2,0) [0|0] "V" Vector__XXX

BA_ "VFrameFormat" BO_ 2566127895 1;
CM_ BO_ 2566127895 "STOP(强制停车)状态 / 低压电池电压 | 信号数 9";
CM_ SG_ 2566127895 车辆状态-中门状态 "车辆状态-中门状态 [枚举: 开门|关门]";
VAL_ 2566127895 车辆状态-中门状态 0 "关门" 1 "开门";
CM_ SG_ 2566127895 车辆状态-前门状态 "车辆状态-前门状态 [枚举: 开门|关门]";
VAL_ 2566127895 车辆状态-前门状态 0 "关门" 1 "开门";
CM_ SG_ 2566127895 车辆状态-后舱门状态 "车辆状态-后舱门状态 [枚举: 开门|关门]";
VAL_ 2566127895 车辆状态-后舱门状态 0 "关门" 1 "开门";
CM_ SG_ 2566127895 车辆状态-ON档信号 "车辆状态-ON档信号 [枚举: 有效|无效]";
VAL_ 2566127895 车辆状态-ON档信号 0 "无效" 1 "有效";
CM_ SG_ 2566127895 车辆状态-START信号 "车辆状态-START信号 [枚举: 有效|无效]";
VAL_ 2566127895 车辆状态-START信号 0 "无效" 1 "有效";
CM_ SG_ 2566127895 手刹状态 "手刹状态 [枚举: 有效|无效]";
VAL_ 2566127895 手刹状态 0 "无效" 1 "有效";
CM_ SG_ 2566127895 STOP(强制停车)状态 "STOP(强制停车)状态 [枚举: 报警|无效]";
VAL_ 2566127895 STOP(强制停车)状态 0 "无效" 1 "报警";
CM_ SG_ 2566127895 制动故障报警 "制动故障报警 [枚举: 无报警|报警]";
VAL_ 2566127895 制动故障报警 0 "无报警";
CM_ SG_ 2566127895 低压电池电压 "低压电池电压";

BO_ 2566128151 ZT_18F40217: 8 Vector__XXX
 SG_ 总里程 : 0|8@1+ (1,0) [0|0] "km" Vector__XXX
 SG_ 仪表程序版本 : 56|8@1+ (0.1,0) [0|0] "" Vector__XXX

BA_ "VFrameFormat" BO_ 2566128151 1;
CM_ BO_ 2566128151 "仪表程序版本 / 总里程 | 信号数 2";
CM_ SG_ 2566128151 总里程 "总里程 [原始公式: ((x1<<24)+(x2<<16)+(x2<<8)+x4)*0.125]";
CM_ SG_ 2566128151 仪表程序版本 "仪表程序版本";

BO_ 2566193648 ZT_18F501F0: 8 Vector__XXX
 SG_ 驱动 : 42|1@1+ (1,0) [0|0] "" Vector__XXX
 SG_ 制动 : 43|1@1+ (1,0) [0|0] "" Vector__XXX
 SG_ 反转 : 44|1@1+ (1,0) [0|0] "" Vector__XXX
 SG_ 电机控制器过压报警 : 56|1@1+ (1,0) [0|0] "" Vector__XXX
 SG_ 电机控制器欠压报警 : 57|1@1+ (1,0) [0|0] "" Vector__XXX
 SG_ 短路、过流报警 : 58|1@1+ (1,0) [0|0] "" Vector__XXX
 SG_ 电机控制器温度报警 : 59|1@1+ (1,0) [0|0] "" Vector__XXX
 SG_ 电机温度报警 : 60|1@1+ (1,0) [0|0] "" Vector__XXX
 SG_ CAN通讯故障报警 : 61|1@1+ (1,0) [0|0] "" Vector__XXX
 SG_ MCU(驱动电机控制单元)故障状态 : 63|1@1+ (1,0) [0|0] "" Vector__XXX
 SG_ MCU(驱动电机控制单元)自检状态 : 40|2@1+ (1,0) [0|0] "" Vector__XXX
 SG_ 电机温度 : 0|8@1+ (1,-40) [0|0] "℃" Vector__XXX
 SG_ 电机控制器温度 : 8|8@1+ (1,-40) [0|0] "℃" Vector__XXX
 SG_ MCU(驱动电机控制单元)软件版本信息 : 32|8@1+ (0.1,0) [0|0] "" Vector__XXX
 SG_ 驱动变频器母线电压 : 16|16@1+ (1,0) [0|0] "V" Vector__XXX

BA_ "VFrameFormat" BO_ 2566193648 1;
CM_ BO_ 2566193648 "CAN通讯故障报警 / MCU(驱动电机控制单元)故障状态 | 信号数 17";
CM_ SG_ 2566193648 驱动 "驱动 [枚举: 有效|无效]";
VAL_ 2566193648 驱动 0 "无效" 1 "有效";
CM_ SG_ 2566193648 制动 "制动 [枚举: 有效|无效]";
VAL_ 2566193648 制动 0 "无效" 1 "有效";
CM_ SG_ 2566193648 反转 "反转 [枚举: 有效|无效]";
VAL_ 2566193648 反转 0 "无效" 1 "有效";
CM_ SG_ 2566193648 电机控制器过压报警 "电机控制器过压报警 [枚举: 报警|正常]";
VAL_ 2566193648 电机控制器过压报警 0 "正常" 1 "报警";
CM_ SG_ 2566193648 电机控制器欠压报警 "电机控制器欠压报警 [枚举: 报警|正常]";
VAL_ 2566193648 电机控制器欠压报警 0 "正常" 1 "报警";
CM_ SG_ 2566193648 短路、过流报警 "短路、过流报警 [枚举: 故障报警(相电流大于等于500A)|无故障]";
VAL_ 2566193648 短路、过流报警 0 "无故障" 1 "故障报警(相电流大于等于500A)";
CM_ SG_ 2566193648 电机控制器温度报警 "电机控制器温度报警 [枚举: 报警|正常]";
VAL_ 2566193648 电机控制器温度报警 0 "正常" 1 "报警";
CM_ SG_ 2566193648 电机温度报警 "电机温度报警 [枚举: 报警|正常]";
VAL_ 2566193648 电机温度报警 0 "正常" 1 "报警";
CM_ SG_ 2566193648 CAN通讯故障报警 "CAN通讯故障报警 [枚举: 报警|正常]";
VAL_ 2566193648 CAN通讯故障报警 0 "正常" 1 "报警";
CM_ SG_ 2566193648 MCU(驱动电机控制单元)故障状态 "MCU(驱动电机控制单元)故障状态 [枚举: 系统故障|无故障]";
VAL_ 2566193648 MCU(驱动电机控制单元)故障状态 0 "无故障" 1 "系统故障";
CM_ SG_ 2566193648 MCU(驱动电机控制单元)自检状态 "MCU(驱动电机控制单元)自检状态 [枚举: 自检中|自检成功|自检失败|无效数据]";
VAL_ 2566193648 MCU(驱动电机控制单元)自检状态 0 "自检中" 1 "自检成功" 2 "自检失败";
CM_ SG_ 2566193648 电机温度 "电机温度";
CM_ SG_ 2566193648 电机控制器温度 "电机控制器温度";
CM_ SG_ 2566193648 MCU(驱动电机控制单元)软件版本信息 "MCU(驱动电机控制单元)软件版本信息";
CM_ SG_ 2566193648 驱动变频器母线电压 "驱动变频器母线电压";

BO_ 2566193904 ZT_18F502F0: 8 Vector__XXX
 SG_ 驱动电机转速 : 0|16@1+ (1,0) [0|0] "RPM" Vector__XXX
 SG_ 驱动电机扭矩 : 16|16@1+ (1,0) [0|0] "NM" Vector__XXX
 SG_ 驱动电机功率 : 32|16@1+ (1,-200) [0|0] "KW" Vector__XXX
 SG_ 驱动电机母线电流 : 48|16@1+ (1,-1000) [0|0] "A" Vector__XXX

BA_ "VFrameFormat" BO_ 2566193904 1;
CM_ BO_ 2566193904 "驱动电机功率 / 驱动电机扭矩 | 信号数 4";
CM_ SG_ 2566193904 驱动电机转速 "驱动电机转速";
CM_ SG_ 2566193904 驱动电机扭矩 "驱动电机扭矩";
CM_ SG_ 2566193904 驱动电机功率 "驱动电机功率";
CM_ SG_ 2566193904 驱动电机母线电流 "驱动电机母线电流";

BO_ 2566395806 ZT_18F8179E: 8 Vector__XXX
 SG_ 电池最低温度点一(整组最低值) : 0|8@1+ (1,-40) [0|0] "℃" Vector__XXX
 SG_ 电池最低温度点一所在箱体地址编号 : 8|8@1+ (1,0) [0|0] "" Vector__XXX
 SG_ 电池最低温度点二(整组最低值) : 16|8@1+ (1,-40) [0|0] "℃" Vector__XXX
 SG_ 电池最低温度点二所在箱体地址编号 : 24|8@1+ (1,0) [0|0] "" Vector__XXX
 SG_ 电池最低温度点三(整组最低值) : 32|8@1+ (1,-40) [0|0] "℃" Vector__XXX
 SG_ 电池最低温度点三所在箱体地址编号 : 40|8@1+ (1,0) [0|0] "" Vector__XXX
 SG_ 电池最低温度点四(整组最低值) : 48|8@1+ (1,-40) [0|0] "℃" Vector__XXX
 SG_ 电池最低温度点四所在箱体地址编号 : 56|8@1+ (1,0) [0|0] "" Vector__XXX

BA_ "VFrameFormat" BO_ 2566395806 1;
CM_ BO_ 2566395806 "电池最低温度点一(整组最低值) / 电池最低温度点一所在箱体地址编号 | 信号数 8";
CM_ SG_ 2566395806 电池最低温度点一(整组最低值) "电池最低温度点一(整组最低值)";
CM_ SG_ 2566395806 电池最低温度点一所在箱体地址编号 "电池最低温度点一所在箱体地址编号";
CM_ SG_ 2566395806 电池最低温度点二(整组最低值) "电池最低温度点二(整组最低值)";
CM_ SG_ 2566395806 电池最低温度点二所在箱体地址编号 "电池最低温度点二所在箱体地址编号";
CM_ SG_ 2566395806 电池最低温度点三(整组最低值) "电池最低温度点三(整组最低值)";
CM_ SG_ 2566395806 电池最低温度点三所在箱体地址编号 "电池最低温度点三所在箱体地址编号";
CM_ SG_ 2566395806 电池最低温度点四(整组最低值) "电池最低温度点四(整组最低值)";
CM_ SG_ 2566395806 电池最低温度点四所在箱体地址编号 "电池最低温度点四所在箱体地址编号";

BO_ 2566396062 ZT_18F8189E: 8 Vector__XXX
 SG_ 电池最高温度点一(整组最低值) : 0|8@1+ (1,-40) [0|0] "℃" Vector__XXX
 SG_ 电池最高温度点一所在箱体地址编号 : 8|8@1+ (1,0) [0|0] "" Vector__XXX
 SG_ 电池最高温度点二(整组最低值) : 16|8@1+ (1,-40) [0|0] "℃" Vector__XXX
 SG_ 电池最高温度点二所在箱体地址编号 : 24|8@1+ (1,0) [0|0] "" Vector__XXX
 SG_ 电池最高温度点三(整组最低值) : 32|8@1+ (1,-40) [0|0] "℃" Vector__XXX
 SG_ 电池最高温度点三所在箱体地址编号 : 40|8@1+ (1,0) [0|0] "" Vector__XXX
 SG_ 电池最高温度点四(整组最低值) : 48|8@1+ (1,-40) [0|0] "℃" Vector__XXX
 SG_ 电池最高温度点四所在箱体地址编号 : 56|8@1+ (1,0) [0|0] "" Vector__XXX

BA_ "VFrameFormat" BO_ 2566396062 1;
CM_ BO_ 2566396062 "电池最高温度点一(整组最低值) / 电池最高温度点一所在箱体地址编号 | 信号数 8";
CM_ SG_ 2566396062 电池最高温度点一(整组最低值) "电池最高温度点一(整组最低值)";
CM_ SG_ 2566396062 电池最高温度点一所在箱体地址编号 "电池最高温度点一所在箱体地址编号";
CM_ SG_ 2566396062 电池最高温度点二(整组最低值) "电池最高温度点二(整组最低值)";
CM_ SG_ 2566396062 电池最高温度点二所在箱体地址编号 "电池最高温度点二所在箱体地址编号";
CM_ SG_ 2566396062 电池最高温度点三(整组最低值) "电池最高温度点三(整组最低值)";
CM_ SG_ 2566396062 电池最高温度点三所在箱体地址编号 "电池最高温度点三所在箱体地址编号";
CM_ SG_ 2566396062 电池最高温度点四(整组最低值) "电池最高温度点四(整组最低值)";
CM_ SG_ 2566396062 电池最高温度点四所在箱体地址编号 "电池最高温度点四所在箱体地址编号";

BO_ 2566396318 ZT_18F8199E: 8 Vector__XXX
 SG_ 电池单体最低电压一所在箱体中单体组编号 : 16|8@1+ (1,0) [0|0] "" Vector__XXX
 SG_ 电池单体最低电压一所在箱体编号 : 24|8@1+ (1,0) [0|0] "" Vector__XXX
 SG_ 电池单体最低电压二所在箱体中单体组编号 : 48|8@1+ (1,0) [0|0] "" Vector__XXX
 SG_ 电池单体最低电压二所在箱体编号 : 56|8@1+ (1,0) [0|0] "" Vector__XXX
 SG_ 电池单体最低电压一(整组最低值) : 0|16@1+ (0.01,0) [0|0] "V" Vector__XXX
 SG_ 电池单体最低电压二 : 32|16@1+ (0.01,0) [0|0] "V" Vector__XXX

BA_ "VFrameFormat" BO_ 2566396318 1;
CM_ BO_ 2566396318 "电池单体最低电压一(整组最低值) / 电池单体最低电压一所在箱体中单体组编号 | 信号数 6";
CM_ SG_ 2566396318 电池单体最低电压一所在箱体中单体组编号 "电池单体最低电压一所在箱体中单体组编号";
CM_ SG_ 2566396318 电池单体最低电压一所在箱体编号 "电池单体最低电压一所在箱体编号";
CM_ SG_ 2566396318 电池单体最低电压二所在箱体中单体组编号 "电池单体最低电压二所在箱体中单体组编号";
CM_ SG_ 2566396318 电池单体最低电压二所在箱体编号 "电池单体最低电压二所在箱体编号";
CM_ SG_ 2566396318 电池单体最低电压一(整组最低值) "电池单体最低电压一(整组最低值)";
CM_ SG_ 2566396318 电池单体最低电压二 "电池单体最低电压二";

BO_ 2566396574 ZT_18F81A9E: 8 Vector__XXX
 SG_ 电池单体最低电压三所在箱体中单体组编号 : 16|8@1+ (1,0) [0|0] "" Vector__XXX
 SG_ 电池单体最低电压三所在箱体编号 : 24|8@1+ (1,0) [0|0] "" Vector__XXX
 SG_ 电池单体最低电压四所在箱体中单体组编号 : 48|8@1+ (1,0) [0|0] "" Vector__XXX
 SG_ 电池单体最低电压四所在箱体编号 : 56|8@1+ (1,0) [0|0] "" Vector__XXX
 SG_ 电池单体最低电压三 : 0|16@1+ (0.01,0) [0|0] "V" Vector__XXX
 SG_ 电池单体最低电压四 : 32|16@1+ (0.01,0) [0|0] "V" Vector__XXX

BA_ "VFrameFormat" BO_ 2566396574 1;
CM_ BO_ 2566396574 "电池单体最低电压三 / 电池单体最低电压三所在箱体中单体组编号 | 信号数 6";
CM_ SG_ 2566396574 电池单体最低电压三所在箱体中单体组编号 "电池单体最低电压三所在箱体中单体组编号";
CM_ SG_ 2566396574 电池单体最低电压三所在箱体编号 "电池单体最低电压三所在箱体编号";
CM_ SG_ 2566396574 电池单体最低电压四所在箱体中单体组编号 "电池单体最低电压四所在箱体中单体组编号";
CM_ SG_ 2566396574 电池单体最低电压四所在箱体编号 "电池单体最低电压四所在箱体编号";
CM_ SG_ 2566396574 电池单体最低电压三 "电池单体最低电压三";
CM_ SG_ 2566396574 电池单体最低电压四 "电池单体最低电压四";

BO_ 2566396830 ZT_18F81B9E: 8 Vector__XXX
 SG_ 电池单体最高电压一所在箱体中单体组编号 : 16|8@1+ (1,0) [0|0] "" Vector__XXX
 SG_ 电池单体最高电压一所在箱体编号 : 24|8@1+ (1,0) [0|0] "" Vector__XXX
 SG_ 电池单体最高电压二所在箱体中单体组编号 : 48|8@1+ (1,0) [0|0] "" Vector__XXX
 SG_ 电池单体最高电压二所在箱体编号 : 56|8@1+ (1,0) [0|0] "" Vector__XXX
 SG_ 电池单体最高电压一(整组最低值) : 0|16@1+ (0.01,0) [0|0] "V" Vector__XXX
 SG_ 电池单体最高电压二 : 32|16@1+ (0.01,0) [0|0] "V" Vector__XXX

BA_ "VFrameFormat" BO_ 2566396830 1;
CM_ BO_ 2566396830 "电池单体最高电压一(整组最低值) / 电池单体最高电压一所在箱体中单体组编号 | 信号数 6";
CM_ SG_ 2566396830 电池单体最高电压一所在箱体中单体组编号 "电池单体最高电压一所在箱体中单体组编号";
CM_ SG_ 2566396830 电池单体最高电压一所在箱体编号 "电池单体最高电压一所在箱体编号";
CM_ SG_ 2566396830 电池单体最高电压二所在箱体中单体组编号 "电池单体最高电压二所在箱体中单体组编号";
CM_ SG_ 2566396830 电池单体最高电压二所在箱体编号 "电池单体最高电压二所在箱体编号";
CM_ SG_ 2566396830 电池单体最高电压一(整组最低值) "电池单体最高电压一(整组最低值)";
CM_ SG_ 2566396830 电池单体最高电压二 "电池单体最高电压二";

BO_ 2566397086 ZT_18F81C9E: 8 Vector__XXX
 SG_ 电池单体最高电压三所在箱体中单体组编号 : 16|8@1+ (1,0) [0|0] "" Vector__XXX
 SG_ 电池单体最高电压三所在箱体编号 : 24|8@1+ (1,0) [0|0] "" Vector__XXX
 SG_ 电池单体最高电压四所在箱体中单体组编号 : 48|8@1+ (1,0) [0|0] "" Vector__XXX
 SG_ 电池单体最高电压四所在箱体编号 : 56|8@1+ (1,0) [0|0] "" Vector__XXX
 SG_ 电池单体最高电压三 : 0|16@1+ (0.01,0) [0|0] "V" Vector__XXX
 SG_ 电池单体最高电压四 : 32|16@1+ (0.01,0) [0|0] "V" Vector__XXX

BA_ "VFrameFormat" BO_ 2566397086 1;
CM_ BO_ 2566397086 "电池单体最高电压三 / 电池单体最高电压三所在箱体中单体组编号 | 信号数 6";
CM_ SG_ 2566397086 电池单体最高电压三所在箱体中单体组编号 "电池单体最高电压三所在箱体中单体组编号";
CM_ SG_ 2566397086 电池单体最高电压三所在箱体编号 "电池单体最高电压三所在箱体编号";
CM_ SG_ 2566397086 电池单体最高电压四所在箱体中单体组编号 "电池单体最高电压四所在箱体中单体组编号";
CM_ SG_ 2566397086 电池单体最高电压四所在箱体编号 "电池单体最高电压四所在箱体编号";
CM_ SG_ 2566397086 电池单体最高电压三 "电池单体最高电压三";
CM_ SG_ 2566397086 电池单体最高电压四 "电池单体最高电压四";

BO_ 2566398622 ZT_18F8229E: 8 Vector__XXX
 SG_ 充电机状态 : 32|1@1+ (1,0) [0|0] "" Vector__XXX
 SG_ 电池充电状态 : 40|1@1+ (1,0) [0|0] "" Vector__XXX
 SG_ 车载充电线的连接状态 : 41|1@1+ (1,0) [0|0] "" Vector__XXX
 SG_ 快充连接状态 : 42|1@1+ (1,0) [0|0] "" Vector__XXX
 SG_ BMS(电池管理系统)高压输出状态-DC/DC(直流转化直流) : 48|1@1+ (1,0) [0|0] "" Vector__XXX
 SG_ 最高允许充电端电压 : 0|16@1+ (0.1,0) [0|0] "V" Vector__XXX
 SG_ 最高允许充电电流 : 16|16@1+ (0.1,-3200) [0|0] "A" Vector__XXX

BA_ "VFrameFormat" BO_ 2566398622 1;
CM_ BO_ 2566398622 "BMS(电池管理系统)高压输出状态-DC/DC(直流转化直流) / 充电机状态 | 信号数 7";
CM_ SG_ 2566398622 充电机状态 "充电机状态 [枚举: 充电机开启|充电机关闭]";
VAL_ 2566398622 充电机状态 0 "充电机关闭" 1 "充电机开启";
CM_ SG_ 2566398622 电池充电状态 "电池充电状态 [枚举: 正在进行充电|未充电]";
VAL_ 2566398622 电池充电状态 0 "未充电" 1 "正在进行充电";
CM_ SG_ 2566398622 车载充电线的连接状态 "车载充电线的连接状态 [枚举: 连接|未连接]";
VAL_ 2566398622 车载充电线的连接状态 0 "未连接" 1 "连接";
CM_ SG_ 2566398622 快充连接状态 "快充连接状态 [枚举: 快充连接|快充未连接]";
VAL_ 2566398622 快充连接状态 0 "快充未连接" 1 "快充连接";
CM_ SG_ 2566398622 BMS(电池管理系统)高压输出状态-DC/DC(直流转化直流) "BMS(电池管理系统)高压输出状态-DC/DC(直流转化直流) [枚举: 已输出|未输出]";
VAL_ 2566398622 BMS(电池管理系统)高压输出状态-DC/DC(直流转化直流) 0 "未输出" 1 "已输出";
CM_ SG_ 2566398622 最高允许充电端电压 "最高允许充电端电压";
CM_ SG_ 2566398622 最高允许充电电流 "最高允许充电电流";

BO_ 2566399134 ZT_18F8249E: 8 Vector__XXX
 SG_ 充电座一温度1 : 0|8@1+ (1,-40) [0|0] "℃" Vector__XXX
 SG_ 充电座一温度2 : 8|8@1+ (1,-40) [0|0] "℃" Vector__XXX
 SG_ 充电座二温度1 : 16|8@1+ (1,-40) [0|0] "℃" Vector__XXX
 SG_ 充电座二温度2 : 24|8@1+ (1,-40) [0|0] "℃" Vector__XXX

BA_ "VFrameFormat" BO_ 2566399134 1;
CM_ BO_ 2566399134 "充电座一温度1 / 充电座一温度2 | 信号数 4";
CM_ SG_ 2566399134 充电座一温度1 "充电座一温度1";
CM_ SG_ 2566399134 充电座一温度2 "充电座一温度2";
CM_ SG_ 2566399134 充电座二温度1 "充电座二温度1";
CM_ SG_ 2566399134 充电座二温度2 "充电座二温度2";

BO_ 2566400158 ZT_18F8289E: 8 Vector__XXX
 SG_ 最高电压电池子系统号 : 0|8@1+ (1,0) [0|0] "" Vector__XXX
 SG_ 最高电压电池单体号 : 8|8@1+ (1,0) [0|0] "" Vector__XXX
 SG_ 电池单体电压最高值 : 16|8@1+ (1,0) [0|0] "" Vector__XXX
 SG_ 最低电压电池子系统号 : 32|8@1+ (1,0) [0|0] "" Vector__XXX
 SG_ 最低电压电池单体号 : 40|8@1+ (1,0) [0|0] "" Vector__XXX
 SG_ 电池单体电压最低值 : 48|8@1+ (1,0) [0|0] "" Vector__XXX

BA_ "VFrameFormat" BO_ 2566400158 1;
CM_ BO_ 2566400158 "最低电压电池单体号 / 最低电压电池子系统号 | 信号数 6";
CM_ SG_ 2566400158 最高电压电池子系统号 "最高电压电池子系统号 [原始公式: if(x1>=0x01&&x1<=0xFA)x1;else if(x1==0xFE)@1;else if(x1==0xFF)@1;else @2;] [枚举: %d||无效数据]";
CM_ SG_ 2566400158 最高电压电池单体号 "最高电压电池单体号 [原始公式: if(x1>=0x01&&x1<=0xFA)x1;else if(x1==0xFE)@1;else if(x1==0xFF)@1;else @2;] [枚举: %d||无效数据]";
CM_ SG_ 2566400158 电池单体电压最高值 "电池单体电压最高值 [原始公式: if(((x1<<8)+x2)==0xFFFE)@1;else if(((x1<<8)+x2)==0xFFFF)@1;else ((x1<<8)+x2)*0.001;] [枚举: %.3f|无效数据]";
CM_ SG_ 2566400158 最低电压电池子系统号 "最低电压电池子系统号 [原始公式: if(x1>=0x01&&x1<=0xFA)x1;else if(x1==0xFE)@1;else if(x1==0xFF)@1;else @2;] [枚举: %d||无效数据]";
CM_ SG_ 2566400158 最低电压电池单体号 "最低电压电池单体号 [原始公式: if(x1>=0x01&&x1<=0xFA)x1;else if(x1==0xFE)@1;else if(x1==0xFF)@1;else @2;] [枚举: %d||无效数据]";
CM_ SG_ 2566400158 电池单体电压最低值 "电池单体电压最低值 [原始公式: if(((x1<<8)+x2)==0xFFFE)@1;else if(((x1<<8)+x2)==0xFFFF)@1;else ((x1<<8)+x2)*0.001;] [枚举: %.3f|无效数据]";

BO_ 2566400414 ZT_18F8299E: 8 Vector__XXX
 SG_ 最高温度子系统号 : 0|8@1+ (1,0) [0|0] "" Vector__XXX
 SG_ 最高温度探针序号 : 8|8@1+ (1,0) [0|0] "" Vector__XXX
 SG_ 最高温度值 : 16|8@1+ (1,0) [0|0] "" Vector__XXX
 SG_ 最低温度子系统号 : 24|8@1+ (1,0) [0|0] "" Vector__XXX
 SG_ 最低温度探针序号 : 32|8@1+ (1,0) [0|0] "" Vector__XXX
 SG_ 最低温度值 : 40|8@1+ (1,0) [0|0] "" Vector__XXX
 SG_ 绝缘电阻 : 48|8@1+ (1,0) [0|0] "" Vector__XXX

BA_ "VFrameFormat" BO_ 2566400414 1;
CM_ BO_ 2566400414 "最低温度值 / 最低温度子系统号 | 信号数 7";
CM_ SG_ 2566400414 最高温度子系统号 "最高温度子系统号 [原始公式: if(x1>=0x01&&x1<=0xFA)x1;else if(x1==0xFE)@1;else if(x1==0xFF)@1;else @2;] [枚举: %d||无效数据]";
CM_ SG_ 2566400414 最高温度探针序号 "最高温度探针序号 [原始公式: if(x1>=0x01&&x1<=0xFA)x1;else if(x1==0xFE)@1;else if(x1==0xFF)@1;else @2;] [枚举: %d||无效数据]";
CM_ SG_ 2566400414 最高温度值 "最高温度值 [原始公式: if(x1>=0x01&&x1<=0xFA)x1-40;else if(x1==0xFFFE)@1;else if(x1==0xFFFF)@1;else @2;] [枚举: %d||无效数据]";
CM_ SG_ 2566400414 最低温度子系统号 "最低温度子系统号 [原始公式: if(x1>=0x01&&x1<=0xFA)x1;else if(x1==0xFE)@1;else if(x1==0xFF)@1;else @2;] [枚举: %d||无效数据]";
CM_ SG_ 2566400414 最低温度探针序号 "最低温度探针序号 [原始公式: if(x1>=0x01&&x1<=0xFA)x1;else if(x1==0xFE)@1;else if(x1==0xFF)@1;else @2;] [枚举: %d||无效数据]";
CM_ SG_ 2566400414 最低温度值 "最低温度值 [原始公式: if(x1>=0x01&&x1<=0xFA)x1-40;else if(x1==0xFFFE)@1;else if(x1==0xFFFF)@1;else @2;] [枚举: %d||无效数据]";
CM_ SG_ 2566400414 绝缘电阻 "绝缘电阻 [原始公式: if(((x1<<8)+x2)>=0x00&&((x1<<8)+x2)<=0xEA60)((x1<<8)+x2);else @1;] [枚举: %d|无效数据]";

BO_ 2566400670 ZT_UNKNOWN_18F82A9E: 8 Vector__XXX
 SG_ 字节0 : 0|8@1+ (1,0) [0|255] "" Vector__XXX
 SG_ 字节1 : 8|8@1+ (1,0) [0|255] "" Vector__XXX
 SG_ 字节2 : 16|8@1+ (1,0) [0|255] "" Vector__XXX
 SG_ 字节3 : 24|8@1+ (1,0) [0|255] "" Vector__XXX
 SG_ 字节4 : 32|8@1+ (1,0) [0|255] "" Vector__XXX
 SG_ 字节5 : 40|8@1+ (1,0) [0|255] "" Vector__XXX
 SG_ 字节6 : 48|8@1+ (1,0) [0|255] "" Vector__XXX
 SG_ 字节7 : 56|8@1+ (1,0) [0|255] "" Vector__XXX

BA_ "VFrameFormat" BO_ 2566400670 1;
CM_ BO_ 2566400670 "NO_CN_ROOT_ID | 无信号定义, 按原始字节输出";
CM_ SG_ 2566400670 字节0 "字节0（原始值，无信号定义）";
CM_ SG_ 2566400670 字节1 "字节1（原始值，无信号定义）";
CM_ SG_ 2566400670 字节2 "字节2（原始值，无信号定义）";
CM_ SG_ 2566400670 字节3 "字节3（原始值，无信号定义）";
CM_ SG_ 2566400670 字节4 "字节4（原始值，无信号定义）";
CM_ SG_ 2566400670 字节5 "字节5（原始值，无信号定义）";
CM_ SG_ 2566400670 字节6 "字节6（原始值，无信号定义）";
CM_ SG_ 2566400670 字节7 "字节7（原始值，无信号定义）";

BO_ 2566400926 ZT_18F82B9E: 8 Vector__XXX
 SG_ 电池温度过高三级故障 : 16|1@1+ (1,0) [0|0] "" Vector__XXX
 SG_ 电池绝缘故障三级故障 : 17|1@1+ (1,0) [0|0] "" Vector__XXX
 SG_ 单体电压过高三级故障 : 18|1@1+ (1,0) [0|0] "" Vector__XXX
 SG_ 单体电压过低三级故障 : 19|1@1+ (1,0) [0|0] "" Vector__XXX
 SG_ 总电压过高三级故障 : 20|1@1+ (1,0) [0|0] "" Vector__XXX
 SG_ 总电压过低三级故障 : 21|1@1+ (1,0) [0|0] "" Vector__XXX
 SG_ 充电电流过大三级故障 : 22|1@1+ (1,0) [0|0] "" Vector__XXX
 SG_ 放电电流过大三级故障 : 23|1@1+ (1,0) [0|0] "" Vector__XXX
 SG_ 回馈电流过大三级故障 : 24|1@1+ (1,0) [0|0] "" Vector__XXX
 SG_ SOC(电池可用容量)过低三级故障 : 25|1@1+ (1,0) [0|0] "" Vector__XXX
 SG_ 高压连接器三级故障 : 26|1@1+ (1,0) [0|0] "" Vector__XXX
 SG_ 电池温度过高二级故障 : 32|1@1+ (1,0) [0|0] "" Vector__XXX
 SG_ 电池绝缘二级故障 : 33|1@1+ (1,0) [0|0] "" Vector__XXX
 SG_ 单体电压过高二级故障 : 34|1@1+ (1,0) [0|0] "" Vector__XXX
 SG_ 单体电压过低二级故障 : 35|1@1+ (1,0) [0|0] "" Vector__XXX
 SG_ 总电压过高二级故障 : 36|1@1+ (1,0) [0|0] "" Vector__XXX
 SG_ 总电压过低二级故障 : 37|1@1+ (1,0) [0|0] "" Vector__XXX
 SG_ 充电电流过大二级故障 : 38|1@1+ (1,0) [0|0] "" Vector__XXX
 SG_ 放电电流过大二级故障 : 39|1@1+ (1,0) [0|0] "" Vector__XXX
 SG_ 回馈电流过大二级故障 : 40|1@1+ (1,0) [0|0] "" Vector__XXX
 SG_ SOC(电池可用容量)过低二级故障 : 41|1@1+ (1,0) [0|0] "" Vector__XXX
 SG_ 高压连接器二级故障 : 42|1@1+ (1,0) [0|0] "" Vector__XXX
 SG_ 绝缘模块二级故障 : 43|1@1+ (1,0) [0|0] "" Vector__XXX
 SG_ 采集模块二级故障 : 44|1@1+ (1,0) [0|0] "" Vector__XXX
 SG_ 电池温度过高一级故障 : 48|1@1+ (1,0) [0|0] "" Vector__XXX
 SG_ 电池绝缘一级故障 : 49|1@1+ (1,0) [0|0] "" Vector__XXX
 SG_ 单体电压过高一级故障 : 50|1@1+ (1,0) [0|0] "" Vector__XXX
 SG_ 单体电压过低一级故障 : 51|1@1+ (1,0) [0|0] "" Vector__XXX
 SG_ 总电压过高一级故障 : 52|1@1+ (1,0) [0|0] "" Vector__XXX
 SG_ 总电压过低一级故障 : 53|1@1+ (1,0) [0|0] "" Vector__XXX
 SG_ 充电电流过大一级故障 : 54|1@1+ (1,0) [0|0] "" Vector__XXX
 SG_ 放电电流过大一级故障 : 55|1@1+ (1,0) [0|0] "" Vector__XXX
 SG_ 回馈电流过大一级故障 : 56|1@1+ (1,0) [0|0] "" Vector__XXX
 SG_ SOC(电池可用容量)过低一级故障 : 57|1@1+ (1,0) [0|0] "" Vector__XXX
 SG_ 高压连接器过温一级故障 : 58|1@1+ (1,0) [0|0] "" Vector__XXX
 SG_ 最高报警等级-无故障 : 0|8@1+ (1,0) [0|0] "" Vector__XXX
 SG_ 可充电储能装置故障总数 : 8|8@1+ (1,0) [0|0] "" Vector__XXX

BA_ "VFrameFormat" BO_ 2566400926 1;
CM_ BO_ 2566400926 "SOC(电池可用容量)过低一级故障 / SOC(电池可用容量)过低三级故障 | 信号数 42";
CM_ SG_ 2566400926 电池温度过高三级故障 "电池温度过高三级故障 [枚举: 1|0]";
VAL_ 2566400926 电池温度过高三级故障 0 "0" 1 "1";
CM_ SG_ 2566400926 电池绝缘故障三级故障 "电池绝缘故障三级故障 [枚举: 1|0]";
VAL_ 2566400926 电池绝缘故障三级故障 0 "0" 1 "1";
CM_ SG_ 2566400926 单体电压过高三级故障 "单体电压过高三级故障 [枚举: 1|0]";
VAL_ 2566400926 单体电压过高三级故障 0 "0" 1 "1";
CM_ SG_ 2566400926 单体电压过低三级故障 "单体电压过低三级故障 [枚举: 1|0]";
VAL_ 2566400926 单体电压过低三级故障 0 "0" 1 "1";
CM_ SG_ 2566400926 总电压过高三级故障 "总电压过高三级故障 [枚举: 1|0]";
VAL_ 2566400926 总电压过高三级故障 0 "0" 1 "1";
CM_ SG_ 2566400926 总电压过低三级故障 "总电压过低三级故障 [枚举: 1|0]";
VAL_ 2566400926 总电压过低三级故障 0 "0" 1 "1";
CM_ SG_ 2566400926 充电电流过大三级故障 "充电电流过大三级故障 [枚举: 1|0]";
VAL_ 2566400926 充电电流过大三级故障 0 "0" 1 "1";
CM_ SG_ 2566400926 放电电流过大三级故障 "放电电流过大三级故障 [枚举: 1|0]";
VAL_ 2566400926 放电电流过大三级故障 0 "0" 1 "1";
CM_ SG_ 2566400926 回馈电流过大三级故障 "回馈电流过大三级故障 [枚举: 1|0]";
VAL_ 2566400926 回馈电流过大三级故障 0 "0" 1 "1";
CM_ SG_ 2566400926 SOC(电池可用容量)过低三级故障 "SOC(电池可用容量)过低三级故障 [枚举: 1|0]";
VAL_ 2566400926 SOC(电池可用容量)过低三级故障 0 "0" 1 "1";
CM_ SG_ 2566400926 高压连接器三级故障 "高压连接器三级故障 [枚举: 1|0]";
VAL_ 2566400926 高压连接器三级故障 0 "0" 1 "1";
CM_ SG_ 2566400926 电池温度过高二级故障 "电池温度过高二级故障 [枚举: 1|0]";
VAL_ 2566400926 电池温度过高二级故障 0 "0" 1 "1";
CM_ SG_ 2566400926 电池绝缘二级故障 "电池绝缘二级故障 [枚举: 1|0]";
VAL_ 2566400926 电池绝缘二级故障 0 "0" 1 "1";
CM_ SG_ 2566400926 单体电压过高二级故障 "单体电压过高二级故障 [枚举: 1|0]";
VAL_ 2566400926 单体电压过高二级故障 0 "0" 1 "1";
CM_ SG_ 2566400926 单体电压过低二级故障 "单体电压过低二级故障 [枚举: 1|0]";
VAL_ 2566400926 单体电压过低二级故障 0 "0" 1 "1";
CM_ SG_ 2566400926 总电压过高二级故障 "总电压过高二级故障 [枚举: 1|0]";
VAL_ 2566400926 总电压过高二级故障 0 "0" 1 "1";
CM_ SG_ 2566400926 总电压过低二级故障 "总电压过低二级故障 [枚举: 1|0]";
VAL_ 2566400926 总电压过低二级故障 0 "0" 1 "1";
CM_ SG_ 2566400926 充电电流过大二级故障 "充电电流过大二级故障 [枚举: 1|0]";
VAL_ 2566400926 充电电流过大二级故障 0 "0" 1 "1";
CM_ SG_ 2566400926 放电电流过大二级故障 "放电电流过大二级故障 [枚举: 1|0]";
VAL_ 2566400926 放电电流过大二级故障 0 "0" 1 "1";
CM_ SG_ 2566400926 回馈电流过大二级故障 "回馈电流过大二级故障 [枚举: 1|0]";
VAL_ 2566400926 回馈电流过大二级故障 0 "0" 1 "1";
CM_ SG_ 2566400926 SOC(电池可用容量)过低二级故障 "SOC(电池可用容量)过低二级故障 [枚举: 1|0]";
VAL_ 2566400926 SOC(电池可用容量)过低二级故障 0 "0" 1 "1";
CM_ SG_ 2566400926 高压连接器二级故障 "高压连接器二级故障 [枚举: 1|0]";
VAL_ 2566400926 高压连接器二级故障 0 "0" 1 "1";
CM_ SG_ 2566400926 绝缘模块二级故障 "绝缘模块二级故障 [枚举: 1|0]";
VAL_ 2566400926 绝缘模块二级故障 0 "0" 1 "1";
CM_ SG_ 2566400926 采集模块二级故障 "采集模块二级故障 [枚举: 1|0]";
VAL_ 2566400926 采集模块二级故障 0 "0" 1 "1";
CM_ SG_ 2566400926 电池温度过高一级故障 "电池温度过高一级故障 [枚举: 1|0]";
VAL_ 2566400926 电池温度过高一级故障 0 "0" 1 "1";
CM_ SG_ 2566400926 电池绝缘一级故障 "电池绝缘一级故障 [枚举: 1|0]";
VAL_ 2566400926 电池绝缘一级故障 0 "0" 1 "1";
CM_ SG_ 2566400926 单体电压过高一级故障 "单体电压过高一级故障 [枚举: 1|0]";
VAL_ 2566400926 单体电压过高一级故障 0 "0" 1 "1";
CM_ SG_ 2566400926 单体电压过低一级故障 "单体电压过低一级故障 [枚举: 1|0]";
VAL_ 2566400926 单体电压过低一级故障 0 "0" 1 "1";
CM_ SG_ 2566400926 总电压过高一级故障 "总电压过高一级故障 [枚举: 1|0]";
VAL_ 2566400926 总电压过高一级故障 0 "0" 1 "1";
CM_ SG_ 2566400926 总电压过低一级故障 "总电压过低一级故障 [枚举: 1|0]";
VAL_ 2566400926 总电压过低一级故障 0 "0" 1 "1";
CM_ SG_ 2566400926 充电电流过大一级故障 "充电电流过大一级故障 [枚举: 1|0]";
VAL_ 2566400926 充电电流过大一级故障 0 "0" 1 "1";
CM_ SG_ 2566400926 放电电流过大一级故障 "放电电流过大一级故障 [枚举: 1|0]";
VAL_ 2566400926 放电电流过大一级故障 0 "0" 1 "1";
CM_ SG_ 2566400926 回馈电流过大一级故障 "回馈电流过大一级故障 [枚举: 1|0]";
VAL_ 2566400926 回馈电流过大一级故障 0 "0" 1 "1";
CM_ SG_ 2566400926 SOC(电池可用容量)过低一级故障 "SOC(电池可用容量)过低一级故障 [枚举: 1|0]";
VAL_ 2566400926 SOC(电池可用容量)过低一级故障 0 "0" 1 "1";
CM_ SG_ 2566400926 高压连接器过温一级故障 "高压连接器过温一级故障 [枚举: 1|0]";
VAL_ 2566400926 高压连接器过温一级故障 0 "0" 1 "1";
CM_ SG_ 2566400926 最高报警等级-无故障 "最高报警等级-无故障 [枚举: 1|0]";
VAL_ 2566400926 最高报警等级-无故障 0 "0";
CM_ SG_ 2566400926 可充电储能装置故障总数 "可充电储能装置故障总数 [原始公式: if(x1>=0x00&&x1<=0xFC)x1;else if(x1==0xFE)@1;else if(x1==0xFF)@1;else @2;] [枚举: %d||无效数据]";

BO_ 2566401182 ZT_18F82C9E: 8 Vector__XXX
 SG_ 温度差异报警 : 0|1@1+ (1,0) [0|0] "" Vector__XXX
 SG_ 电池高温报警 : 1|1@1+ (1,0) [0|0] "" Vector__XXX
 SG_ 车载储能装置过压报警 : 2|1@1+ (1,0) [0|0] "" Vector__XXX
 SG_ 车载储能装置欠压报警 : 3|1@1+ (1,0) [0|0] "" Vector__XXX
 SG_ SOC(电池可用容量)低报警 : 4|1@1+ (1,0) [0|0] "" Vector__XXX
 SG_ 单体过压报警 : 5|1@1+ (1,0) [0|0] "" Vector__XXX
 SG_ 单体欠压报警 : 6|1@1+ (1,0) [0|0] "" Vector__XXX
 SG_ SOC(电池可用容量)过高报警 : 7|1@1+ (1,0) [0|0] "" Vector__XXX
 SG_ SOC(电池可用容量)跳变报警 : 8|1@1+ (1,0) [0|0] "" Vector__XXX
 SG_ 可充电储能系统不匹配报警 : 9|1@1+ (1,0) [0|0] "" Vector__XXX
 SG_ 电池单体一致性差报警 : 10|1@1+ (1,0) [0|0] "" Vector__XXX
 SG_ 绝缘报警 : 11|1@1+ (1,0) [0|0] "" Vector__XXX
 SG_ SOC(电池可用容量)车载储能装置过充 : 12|1@1+ (1,0) [0|0] "" Vector__XXX
 SG_ 可充电储能装置故障总数-停车充电 : 24|8@1+ (1,0) [0|0] "" Vector__XXX
 SG_ 累计充电电量 : 40|8@1+ (1,0) [0|0] "kWh" Vector__XXX

BA_ "VFrameFormat" BO_ 2566401182 1;
CM_ BO_ 2566401182 "SOC(电池可用容量)低报警 / SOC(电池可用容量)跳变报警 | 信号数 21";
CM_ SG_ 2566401182 温度差异报警 "温度差异报警 [枚举: 1|0]";
VAL_ 2566401182 温度差异报警 0 "0" 1 "1";
CM_ SG_ 2566401182 电池高温报警 "电池高温报警 [枚举: 1|0]";
VAL_ 2566401182 电池高温报警 0 "0" 1 "1";
CM_ SG_ 2566401182 车载储能装置过压报警 "车载储能装置过压报警 [枚举: 1|0]";
VAL_ 2566401182 车载储能装置过压报警 0 "0" 1 "1";
CM_ SG_ 2566401182 车载储能装置欠压报警 "车载储能装置欠压报警 [枚举: 1|0]";
VAL_ 2566401182 车载储能装置欠压报警 0 "0" 1 "1";
CM_ SG_ 2566401182 SOC(电池可用容量)低报警 "SOC(电池可用容量)低报警 [枚举: 1|0]";
VAL_ 2566401182 SOC(电池可用容量)低报警 0 "0" 1 "1";
CM_ SG_ 2566401182 单体过压报警 "单体过压报警 [枚举: 1|0]";
VAL_ 2566401182 单体过压报警 0 "0" 1 "1";
CM_ SG_ 2566401182 单体欠压报警 "单体欠压报警 [枚举: 1|0]";
VAL_ 2566401182 单体欠压报警 0 "0" 1 "1";
CM_ SG_ 2566401182 SOC(电池可用容量)过高报警 "SOC(电池可用容量)过高报警 [枚举: 1|0]";
VAL_ 2566401182 SOC(电池可用容量)过高报警 0 "0" 1 "1";
CM_ SG_ 2566401182 SOC(电池可用容量)跳变报警 "SOC(电池可用容量)跳变报警 [枚举: 1|0]";
VAL_ 2566401182 SOC(电池可用容量)跳变报警 0 "0" 1 "1";
CM_ SG_ 2566401182 可充电储能系统不匹配报警 "可充电储能系统不匹配报警 [枚举: 1|0]";
VAL_ 2566401182 可充电储能系统不匹配报警 0 "0" 1 "1";
CM_ SG_ 2566401182 电池单体一致性差报警 "电池单体一致性差报警 [枚举: 1|0]";
VAL_ 2566401182 电池单体一致性差报警 0 "0" 1 "1";
CM_ SG_ 2566401182 绝缘报警 "绝缘报警 [枚举: 1|0]";
VAL_ 2566401182 绝缘报警 0 "0" 1 "1";
CM_ SG_ 2566401182 SOC(电池可用容量)车载储能装置过充 "SOC(电池可用容量)车载储能装置过充 [枚举: 1|0]";
VAL_ 2566401182 SOC(电池可用容量)车载储能装置过充 0 "0" 1 "1";
CM_ SG_ 2566401182 可充电储能装置故障总数-停车充电 "可充电储能装置故障总数-停车充电 [枚举: 0|1]";
VAL_ 2566401182 可充电储能装置故障总数-停车充电 1 "1";
CM_ SG_ 2566401182 累计充电电量 "累计充电电量 [原始公式: ((x1<<16)+(x2<<8)+x3)*0.1]";

BO_ 2566401438 ZT_18F82D9E: 8 Vector__XXX
 SG_ 可充电储能子系统个数 : 0|8@1+ (1,0) [0|0] "" Vector__XXX
 SG_ 可充电储能子系统号 : 8|8@1+ (1,0) [0|0] "" Vector__XXX
 SG_ 可充储能装置电压 : 16|8@1+ (1,0) [0|0] "" Vector__XXX
 SG_ 可充储能装置电流 : 32|8@1+ (1,0) [0|0] "" Vector__XXX
 SG_ 可充电储能子系统编码长度 : 48|8@1+ (1,0) [0|0] "" Vector__XXX
 SG_ 可充电储能子系统编码 : 56|8@1+ (1,0) [0|0] "" Vector__XXX

BA_ "VFrameFormat" BO_ 2566401438 1;
CM_ BO_ 2566401438 "可充储能装置电压 / 可充储能装置电流 | 信号数 6";
CM_ SG_ 2566401438 可充电储能子系统个数 "可充电储能子系统个数 [原始公式: if(x1>=0x01&&x1<=0xFA)x1;else if(x1==0xFE)@1;else if(x1==0xFF)@1;else @2;] [枚举: %d||无效数据]";
CM_ SG_ 2566401438 可充电储能子系统号 "可充电储能子系统号 [原始公式: if(x1>=0x01&&x1<=0xFA)x1;else if(x1==0xFE)@1;else if(x1==0xFF)@1;else @2;] [枚举: %d||无效数据]";
CM_ SG_ 2566401438 可充储能装置电压 "可充储能装置电压 [原始公式: if(((x1<<8)+x2)==0xFFFE)@1;else if(((x1<<8)+x2)==0xFFFF)@1;else ((x1<<8)+x2)*0.1;] [枚举: %.1f|无效数据]";
CM_ SG_ 2566401438 可充储能装置电流 "可充储能装置电流 [原始公式: if(((x1<<8)+x2)==0xFFFE)@1;else if(((x1<<8)+x2)==0xFFFF)@1;else ((x1<<8)+x2)*0.1-1000;] [枚举: %.1f|无效数据]";
CM_ SG_ 2566401438 可充电储能子系统编码长度 "可充电储能子系统编码长度";
CM_ SG_ 2566401438 可充电储能子系统编码 "可充电储能子系统编码";

BO_ 2566401694 ZT_18F82E9E: 8 Vector__XXX
 SG_ 可充电储能子系统号 : 0|8@1+ (1,0) [0|0] "" Vector__XXX
 SG_ 可充电储能温度探针个数 : 8|8@1+ (1,0) [0|0] "" Vector__XXX
 SG_ 单体电池总数 : 24|8@1+ (1,0) [0|0] "" Vector__XXX

BA_ "VFrameFormat" BO_ 2566401694 1;
CM_ BO_ 2566401694 "单体电池总数 / 可充电储能子系统号 | 信号数 3";
CM_ SG_ 2566401694 可充电储能子系统号 "可充电储能子系统号 [原始公式: if(x1>=0x01&&x1<=0xFA)x2;else if(x1==0xFE)@1;else if(x1==0xFF)@1;else @2;] [枚举: %d||无效数据]";
CM_ SG_ 2566401694 可充电储能温度探针个数 "可充电储能温度探针个数 [原始公式: if(((x1<<8)+x2)>=0x01&&((x1<<8)+x2)<=0xFFFB)((x1<<8)+x2);else if(((x1<<8)+x2)==0xFFFE)@1;else if(((x1<<8)+x2)==0xFFFF)@1;else @2;] [枚举: %d||无效数据]";
CM_ SG_ 2566401694 单体电池总数 "单体电池总数 [原始公式: if(((x1<<8)+x2)>=0x01&&((x1<<8)+x2)<=0xFFFB)((x1<<8)+x2);else if(((x1<<8)+x2)==0xFFFE)@1;else if(((x1<<8)+x2)==0xFFFF)@1;else @2;] [枚举: %d||无效数据]";

BO_ 2566658031 ZT_18FC17EF: 8 Vector__XXX
 SG_ 驱动系统功率百分比 : 48|8@1+ (1,-100) [-100|100] "%" Vector__XXX
 SG_ 保留 : 0|8@1+ (1,0) [0|255] "" Vector__XXX
 SG_ 瞬时电耗-静态 : 16|16@1+ (0.01,-300) [-300|355.35] "kWh/h" Vector__XXX
 SG_ 瞬时电耗-动态 : 32|16@1+ (0.01,-300) [-300|355.35] "kWh/km" Vector__XXX

BA_ "VFrameFormat" BO_ 2566658031 1;
CM_ BO_ 2566658031 "保留 / 瞬时电耗 | 信号数 15";
CM_ SG_ 2566658031 驱动系统功率百分比 "驱动系统功率百分比";
CM_ SG_ 2566658031 保留 "保留";
CM_ SG_ 2566658031 瞬时电耗-静态 "瞬时电耗-静态";
CM_ SG_ 2566658031 瞬时电耗-动态 "瞬时电耗-动态";

BO_ 2566658287 ZT_18FC18EF: 8 Vector__XXX
 SG_ DCDC累计电耗 : 0|8@1+ (1,0) [0|100000000000] "" Vector__XXX
 SG_ 油泵累计电耗 : 16|8@1+ (1,0) [0|10000000000] "" Vector__XXX
 SG_ 气泵累计电耗 : 40|8@1+ (1,0) [0|100000000000] "" Vector__XXX

BA_ "VFrameFormat" BO_ 2566658287 1;
CM_ BO_ 2566658287 "DCDC累计电耗 / 气泵累计电耗 | 信号数 3";
CM_ SG_ 2566658287 DCDC累计电耗 "DCDC累计电耗 [原始公式: ((BYTE[0]+BYTE[1]*256+BYTE[2]*65536)&1048575)*0.1]";
CM_ SG_ 2566658287 油泵累计电耗 "油泵累计电耗 [原始公式: (((BYTE[2]+BYTE[3]*256+BYTE[4]*65536)>>4)&1048575)*0.1]";
CM_ SG_ 2566658287 气泵累计电耗 "气泵累计电耗 [原始公式: ((BYTE[5]+BYTE[6]*256+BYTE[7]*65536)&1048575)*0.1]";

BO_ 2566719232 ZT_18FD0700: 8 Vector__XXX
 SG_ 故障灯 : 8|8@1+ (1,0) [0|255] "" Vector__XXX
 SG_ MI灯-1 : 16|8@1+ (1,0) [0|255] "" Vector__XXX
 SG_ 排气制动灯 : 24|8@1+ (1,0) [0|255] "" Vector__XXX

BA_ "VFrameFormat" BO_ 2566719232 1;
CM_ BO_ 2566719232 "MI灯-1 / 排气制动灯 | 信号数 3";
CM_ SG_ 2566719232 故障灯 "故障灯";
CM_ SG_ 2566719232 MI灯-1 "MI灯-1";
CM_ SG_ 2566719232 排气制动灯 "排气制动灯";

BO_ 2566719247 ZT_18FD070F: 8 Vector__XXX
 SG_ 排气制动指示灯 : 8|8@1+ (1,0) [0|255] "" Vector__XXX
 SG_ 机油压力低报警灯 : 16|8@1+ (1,0) [0|255] "" Vector__XXX
 SG_ 水温高报警灯 : 24|8@1+ (1,0) [0|255] "" Vector__XXX

BA_ "VFrameFormat" BO_ 2566719247 1;
CM_ BO_ 2566719247 "排气制动指示灯 / 机油压力低报警灯 | 信号数 3";
CM_ SG_ 2566719247 排气制动指示灯 "排气制动指示灯";
CM_ SG_ 2566719247 机油压力低报警灯 "机油压力低报警灯";
CM_ SG_ 2566719247 水温高报警灯 "水温高报警灯";

BO_ 2566723567 ZT_18FD17EF: 8 Vector__XXX
 SG_ 剩余可行驶里程 : 0|16@1+ (0.1,0) [0|655.35] "km" Vector__XXX
 SG_ 周期内行驶里程 : 16|16@1+ (0.1,0) [0|655.35] "km" Vector__XXX

BA_ "VFrameFormat" BO_ 2566723567 1;
CM_ BO_ 2566723567 "剩余可行驶里程 / 周期内行驶里程 | 信号数 8";
CM_ SG_ 2566723567 剩余可行驶里程 "剩余可行驶里程";
CM_ SG_ 2566723567 周期内行驶里程 "周期内行驶里程";

BO_ 2566749184 ZT_18FD7C00: 8 Vector__XXX
 SG_ DPF再生状态 : 8|8@1+ (1,0) [0|255] "" Vector__XXX

BA_ "VFrameFormat" BO_ 2566749184 1;
CM_ BO_ 2566749184 "DPF再生状态 | 信号数 1";
CM_ SG_ 2566749184 DPF再生状态 "DPF再生状态";

BO_ 2566757120 ZT_18FD9B00: 8 Vector__XXX
 SG_ 尿素浓度 : 8|8@1+ (1,0) [0|1000] "" Vector__XXX

BA_ "VFrameFormat" BO_ 2566757120 1;
CM_ BO_ 2566757120 "尿素浓度 | 信号数 1";
CM_ SG_ 2566757120 尿素浓度 "尿素浓度";

BO_ 2566787596 ZT_18FE120C: 8 Vector__XXX
 SG_ 制动状态 1 : 0|8@1+ (1,0) [0|3] "" Vector__XXX
 SG_ 故障代码 : 8|8@1+ (1,0) [0|16] "" Vector__XXX
 SG_ 程序代码 : 24|16@1+ (1,0) [0|65535] "" Vector__XXX

BA_ "VFrameFormat" BO_ 2566787596 1;
CM_ BO_ 2566787596 "制动状态 1 / 制动状态2 | 信号数 4";
CM_ SG_ 2566787596 制动状态 1 "制动状态 1 [原始公式: if(((BYTE[0]>>0)&3)==1) 0; else if(((BYTE[0]>>0)&3)==16) 1; else 2] [枚举: 启动电子制动|释放电子制动|预留]";
CM_ SG_ 2566787596 故障代码 "故障代码 [原始公式: if((BYTE[1])==0) 0; else if((BYTE[1])==1) 1; else if((BYTE[1])==34) 2; else if((BYTE[1])==35) 3; else if((BYTE[1])==49) 4; else if((BYTE[1])==50) 5; else if((BYTE[1])==51) 6; else if((BYTE[1])==65) 7; else if((BYTE[1])==66) 8; else if((BYTE[1])==67) 9; else if((BYTE[1])==68) 10; else if((BYTE[1])==69) 11; else if((BYTE[1])==81) 12; else 13] [枚举: 无故障|临时停车阀短路|驻车记忆阀制动端短路|驻车记忆阀缓解端短路|临时停车阀断路|驻车记忆阀制动端断路|驻车记忆阀缓解端短路|阀电电压过高|阀电电压过低|阀电电压短路断路|CAN通讯故障|读写内存故障|EBS系统故障|预留]";
CM_ SG_ 2566787596 程序代码 "程序代码";

BO_ 2566789103 ZT_18FE17EF: 8 Vector__XXX
 SG_ 后仓门状态 : 48|2@1+ (1,0) [0|0] "" Vector__XXX
 SG_ 最高限制车速值 : 16|8@1+ (1,0) [0|250] "km/h" Vector__XXX
 SG_ 整车故障代码 : 56|8@1+ (1,0) [0|255] "" Vector__XXX
 SG_ 车速值 : 0|16@1+ (0.00390625,0) [0|250] "km/h" Vector__XXX

BA_ "VFrameFormat" BO_ 2566789103 1;
CM_ BO_ 2566789103 "加速踏板实际开度 / 后仓门状态 | 信号数 13";
CM_ SG_ 2566789103 后仓门状态 "后仓门状态 [枚举: 无故障|有故障]";
VAL_ 2566789103 后仓门状态 0 "无故障" 1 "有故障";
CM_ SG_ 2566789103 最高限制车速值 "最高限制车速值";
CM_ SG_ 2566789103 整车故障代码 "整车故障代码";
CM_ SG_ 2566789103 车速值 "车速值";

BO_ 2566804992 ZT_18FE5600: 8 Vector__XXX
 SG_ 尿素温度 : 8|8@1+ (1,0) [0|1000] "℃" Vector__XXX
 SG_ 尿素液位 : 16|8@1+ (1,0) [0|1000] "" Vector__XXX

BA_ "VFrameFormat" BO_ 2566804992 1;
CM_ BO_ 2566804992 "尿素液位 / 尿素温度 | 信号数 2";
CM_ SG_ 2566804992 尿素温度 "尿素温度";
CM_ SG_ 2566804992 尿素液位 "尿素液位";

BO_ 2566809856 ZT_18FE6900: 8 Vector__XXX
 SG_ 增压中冷后温度度 : 8|8@1+ (1,0) [0|1000] "℃" Vector__XXX

BA_ "VFrameFormat" BO_ 2566809856 1;
CM_ BO_ 2566809856 "增压中冷后温度度 | 信号数 1";
CM_ SG_ 2566809856 增压中冷后温度度 "增压中冷后温度度";

BO_ 2566827543 ZT_18FEAE17: 8 Vector__XXX
 SG_ 气压1 : 16|8@1+ (8,0) [0|10000] "" Vector__XXX
 SG_ 气压2 : 24|8@1+ (8,0) [0|2000] "kPa" Vector__XXX

BA_ "VFrameFormat" BO_ 2566827543 1;
CM_ BO_ 2566827543 "气压1 / 气压2 | 信号数 5";
CM_ SG_ 2566827543 气压1 "气压1";
CM_ SG_ 2566827543 气压2 "气压2";

BO_ 2566832407 ZT_18FEC117: 8 Vector__XXX
 SG_ 总里程 : 0|32@1+ (0.005,0) [0|1000000] "" Vector__XXX
 SG_ 小计里程 : 32|32@1+ (0.005,0) [0|21055406] "km" Vector__XXX

BA_ "VFrameFormat" BO_ 2566832407 1;
CM_ BO_ 2566832407 "仪表总里程 / 单次里程 | 信号数 5";
CM_ SG_ 2566832407 总里程 "总里程";
CM_ SG_ 2566832407 小计里程 "小计里程";

BO_ 2566834688 ZT_18FECA00: 8 Vector__XXX
 SG_ MI灯-2 : 8|8@1+ (1,0) [0|1000] "" Vector__XXX
 SG_ 故障 : 16|8@1+ (1,0) [0|1000] "" Vector__XXX

BA_ "VFrameFormat" BO_ 2566834688 1;
CM_ BO_ 2566834688 "MI灯-2 / 故障 | 信号数 2";
CM_ SG_ 2566834688 MI灯-2 "MI灯-2";
CM_ SG_ 2566834688 故障 "故障";

BO_ 2566834932 ZT_18FECAF4: 8 Vector__XXX
 SG_ 警告灯状态 : 2|2@1+ (1,0) [0|3] "" Vector__XXX
 SG_ 停车灯状态 : 4|2@1+ (1,0) [0|3] "" Vector__XXX
 SG_ SPN最低有效值 : 37|3@1+ (1,0) [0|524287] "" Vector__XXX
 SG_ FMI值 : 32|5@1+ (1,0) [0|31] "" Vector__XXX
 SG_ 计码数值 : 40|6@1+ (1,0) [0|126] "" Vector__XXX
 SG_ SPN最高有效值 : 16|16@1+ (1,0) [0|524287] "" Vector__XXX

BA_ "VFrameFormat" BO_ 2566834932 1;
CM_ BO_ 2566834932 "FMI值 / SPN最低有效值 | 信号数 6";
CM_ SG_ 2566834932 警告灯状态 "警告灯状态 [枚举: 关闭|打开]";
VAL_ 2566834932 警告灯状态 0 "关闭" 1 "打开";
CM_ SG_ 2566834932 停车灯状态 "停车灯状态 [枚举: 关闭|打开]";
VAL_ 2566834932 停车灯状态 0 "关闭" 1 "打开";
CM_ SG_ 2566834932 SPN最低有效值 "SPN最低有效值";
CM_ SG_ 2566834932 FMI值 "FMI值";
CM_ SG_ 2566834932 计码数值 "计码数值";
CM_ SG_ 2566834932 SPN最高有效值 "SPN最高有效值";

BO_ 2566834933 ZT_18FECAF5: 8 Vector__XXX
 SG_ 警告灯状态 : 2|2@1+ (1,0) [0|3] "" Vector__XXX
 SG_ 停车灯状态 : 4|2@1+ (1,0) [0|3] "" Vector__XXX
 SG_ 最低有效值 : 37|3@1+ (1,0) [0|524287] "" Vector__XXX
 SG_ FMI值 : 32|5@1+ (1,0) [0|31] "" Vector__XXX
 SG_ 计码数值 : 40|6@1+ (1,0) [0|126] "" Vector__XXX
 SG_ SPN最高有效值 : 16|16@1+ (1,0) [0|524287] "" Vector__XXX

BA_ "VFrameFormat" BO_ 2566834933 1;
CM_ BO_ 2566834933 "FMI值 / SPN最高有效值 | 信号数 6";
CM_ SG_ 2566834933 警告灯状态 "警告灯状态 [枚举: 关闭|打开]";
VAL_ 2566834933 警告灯状态 0 "关闭" 1 "打开";
CM_ SG_ 2566834933 停车灯状态 "停车灯状态 [枚举: 关闭|打开]";
VAL_ 2566834933 停车灯状态 0 "关闭" 1 "打开";
CM_ SG_ 2566834933 最低有效值 "最低有效值";
CM_ SG_ 2566834933 FMI值 "FMI值";
CM_ SG_ 2566834933 计码数值 "计码数值";
CM_ SG_ 2566834933 SPN最高有效值 "SPN最高有效值";

BO_ 2566838787 ZT_18FEDA03: 8 Vector__XXX
 SG_ 月 : 39|4@1+ (1,0) [0|12] "" Vector__XXX
 SG_ 日 : 43|5@1+ (1,0) [0|31] "" Vector__XXX
 SG_ 年 : 32|7@1+ (1,0) [18|255] "" Vector__XXX
 SG_ 次版本号 : 16|8@1+ (1,0) [0|255] "" Vector__XXX
 SG_ 主版本号 : 0|16@1+ (1,0) [0|65535] "" Vector__XXX

BA_ "VFrameFormat" BO_ 2566838787 1;
CM_ BO_ 2566838787 "主版本号 / 年 | 信号数 5";
CM_ SG_ 2566838787 月 "月";
CM_ SG_ 2566838787 日 "日";
CM_ SG_ 2566838787 年 "年";
CM_ SG_ 2566838787 次版本号 "次版本号";
CM_ SG_ 2566838787 主版本号 "主版本号";

BO_ 2566838934 ZT_18FEDA96: 8 Vector__XXX
 SG_ 月 : 39|4@1+ (1,0) [0|12] "" Vector__XXX
 SG_ 日 : 43|5@1+ (1,0) [0|31] "" Vector__XXX
 SG_ 年 : 32|7@1+ (1,0) [18|255] "" Vector__XXX
 SG_ 次版本号 : 16|8@1+ (1,0) [0|255] "" Vector__XXX
 SG_ 主版本号 : 0|16@1+ (1,0) [0|65535] "" Vector__XXX

BA_ "VFrameFormat" BO_ 2566838934 1;
CM_ BO_ 2566838934 "主版本号 / 年 | 信号数 5";
CM_ SG_ 2566838934 月 "月";
CM_ SG_ 2566838934 日 "日";
CM_ SG_ 2566838934 年 "年";
CM_ SG_ 2566838934 次版本号 "次版本号";
CM_ SG_ 2566838934 主版本号 "主版本号";

BO_ 2566838940 ZT_18FEDA9C: 8 Vector__XXX
 SG_ 月 : 39|4@1+ (1,0) [0|12] "" Vector__XXX
 SG_ 日 : 43|5@1+ (1,0) [0|31] "" Vector__XXX
 SG_ 年 : 32|7@1+ (1,0) [18|255] "" Vector__XXX
 SG_ 次版本号 : 16|8@1+ (1,0) [0|255] "" Vector__XXX
 SG_ 主版本号 : 0|16@1+ (1,0) [0|65535] "" Vector__XXX

BA_ "VFrameFormat" BO_ 2566838940 1;
CM_ BO_ 2566838940 "主版本号 / 年 | 信号数 5";
CM_ SG_ 2566838940 月 "月";
CM_ SG_ 2566838940 日 "日";
CM_ SG_ 2566838940 年 "年";
CM_ SG_ 2566838940 次版本号 "次版本号";
CM_ SG_ 2566838940 主版本号 "主版本号";

BO_ 2566839024 ZT_18FEDAF0: 8 Vector__XXX
 SG_ 月-2 : 39|4@1+ (1,0) [0|12] "" Vector__XXX
 SG_ 日-2 : 43|5@1+ (1,0) [0|31] "" Vector__XXX
 SG_ 年-2 : 32|7@1+ (1,0) [18|255] "" Vector__XXX
 SG_ 次版本号 : 16|8@1+ (1,0) [0|255] "" Vector__XXX
 SG_ 主版本号 : 0|16@1+ (1,0) [0|65535] "" Vector__XXX

BA_ "VFrameFormat" BO_ 2566839024 1;
CM_ BO_ 2566839024 "主版本号 / 年-2 | 信号数 5";
CM_ SG_ 2566839024 月-2 "月-2";
CM_ SG_ 2566839024 日-2 "日-2";
CM_ SG_ 2566839024 年-2 "年-2";
CM_ SG_ 2566839024 次版本号 "次版本号";
CM_ SG_ 2566839024 主版本号 "主版本号";

BO_ 2566841879 ZT_18FEE617: 8 Vector__XXX
 SG_ 秒 : 0|8@1+ (0.25,0) [0|60] "s" Vector__XXX
 SG_ 月 : 40|8@1+ (1,0) [0|255] "month" Vector__XXX
 SG_ 日 : 24|8@1+ (1,0) [0|255] "day" Vector__XXX
 SG_ 时 : 32|8@1+ (1,0) [0|255] "h" Vector__XXX
 SG_ 分 : 8|8@1+ (1,0) [0|255] "min" Vector__XXX
 SG_ 本地分偏差 : 48|8@1+ (1,-125) [-125|125] "" Vector__XXX
 SG_ 本地时偏差 : 56|8@1+ (1,-125) [-125|125] "" Vector__XXX

BA_ "VFrameFormat" BO_ 2566841879 1;
CM_ BO_ 2566841879 "分 / 天 | 信号数 10";
CM_ SG_ 2566841879 秒 "秒";
CM_ SG_ 2566841879 月 "月";
CM_ SG_ 2566841879 日 "日";
CM_ SG_ 2566841879 时 "时";
CM_ SG_ 2566841879 分 "分";
CM_ SG_ 2566841879 本地分偏差 "本地分偏差";
CM_ SG_ 2566841879 本地时偏差 "本地时偏差";

BO_ 2566842624 ZT_18FEE900: 8 Vector__XXX
 SG_ 总燃油消耗 : 8|8@1+ (1,0) [0|1000] "" Vector__XXX
 SG_ 单程燃油消耗 : 16|8@1+ (1,0) [0|1000] "" Vector__XXX

BA_ "VFrameFormat" BO_ 2566842624 1;
CM_ BO_ 2566842624 "单程燃油消耗 / 总燃油消耗 | 信号数 2";
CM_ SG_ 2566842624 总燃油消耗 "总燃油消耗";
CM_ SG_ 2566842624 单程燃油消耗 "单程燃油消耗";

BO_ 2566843904 ZT_18FEEE00: 8 Vector__XXX
 SG_ 冷却液温度 : 8|8@1+ (1,0) [0|1000] "℃" Vector__XXX
 SG_ 机油温度 : 16|8@1+ (1,0) [0|1000] "℃" Vector__XXX

BA_ "VFrameFormat" BO_ 2566843904 1;
CM_ BO_ 2566843904 "冷却液温度 / 机油温度 | 信号数 2";
CM_ SG_ 2566843904 冷却液温度 "冷却液温度";
CM_ SG_ 2566843904 机油温度 "机油温度";

BO_ 2566844160 ZT_18FEEF00: 8 Vector__XXX
 SG_ 机油压力 : 8|8@1+ (1,0) [0|1000] "" Vector__XXX

BA_ "VFrameFormat" BO_ 2566844160 1;
CM_ BO_ 2566844160 "机油压力 | 信号数 1";
CM_ SG_ 2566844160 机油压力 "机油压力";

BO_ 2566844695 ZT_18FEF117: 8 Vector__XXX
 SG_ 手刹信号 : 2|2@1+ (1,0) [0|0] "" Vector__XXX
 SG_ 刹车开关信号 : 28|2@1+ (1,0) [0|0] "" Vector__XXX
 SG_ 车速信号 : 8|8@1+ (0.00390625,0) [0|250] "km/h" Vector__XXX

BA_ "VFrameFormat" BO_ 2566844695 1;
CM_ BO_ 2566844695 "保留 / 刹车开关信号 | 信号数 7";
CM_ SG_ 2566844695 手刹信号 "手刹信号 [枚举: 放下|拉起|错误|未激活]";
VAL_ 2566844695 手刹信号 0 "放下" 1 "拉起" 2 "错误" 3 "未激活";
CM_ SG_ 2566844695 刹车开关信号 "刹车开关信号 [枚举: 松开|踩下|错误|未激活]";
VAL_ 2566844695 刹车开关信号 0 "松开" 1 "踩下" 2 "错误" 3 "未激活";
CM_ SG_ 2566844695 车速信号 "车速信号";

BO_ 2566844928 ZT_18FEF200: 8 Vector__XXX
 SG_ 平均燃油经济性 : 8|8@1+ (1,0) [0|1000] "" Vector__XXX

BA_ "VFrameFormat" BO_ 2566844928 1;
CM_ BO_ 2566844928 "平均燃油经济性 | 信号数 1";
CM_ SG_ 2566844928 平均燃油经济性 "平均燃油经济性";

BO_ 2566845696 ZT_18FEF500: 8 Vector__XXX
 SG_ 环境温度 : 8|8@1+ (1,0) [0|1000] "℃" Vector__XXX
 SG_ 大气压力 : 16|8@1+ (1,0) [0|1000] "" Vector__XXX

BA_ "VFrameFormat" BO_ 2566845696 1;
CM_ BO_ 2566845696 "大气压力 / 环境温度 | 信号数 2";
CM_ SG_ 2566845696 环境温度 "环境温度";
CM_ SG_ 2566845696 大气压力 "大气压力";

BO_ 2566848256 ZT_18FEFF00: 8 Vector__XXX
 SG_ 驾驶员警告灯 : 8|8@1+ (1,0) [0|1000] "" Vector__XXX
 SG_ 燃油含水指示灯 : 16|8@1+ (1,0) [0|1000] "" Vector__XXX

BA_ "VFrameFormat" BO_ 2566848256 1;
CM_ BO_ 2566848256 "燃油含水指示灯 / 驾驶员警告灯 | 信号数 2";
CM_ SG_ 2566848256 驾驶员警告灯 "驾驶员警告灯";
CM_ SG_ 2566848256 燃油含水指示灯 "燃油含水指示灯";

BO_ 2566848495 ZT_18FEFFEF: 8 Vector__XXX
 SG_ 锁车状态 : 0|4@1+ (1,0) [0|2] "" Vector__XXX
 SG_ 锁车原因 : 4|4@1+ (1,0) [0|255] "" Vector__XXX
 SG_ 远程锁车执行模式 : 8|4@1+ (1,0) [0|255] "" Vector__XXX
 SG_ 剩余动车次数 : 16|8@1+ (1,0) [0|255] "" Vector__XXX

BA_ "VFrameFormat" BO_ 2566848495 1;
CM_ BO_ 2566848495 "剩余动车次数 / 远程锁车执行模式 | 信号数 4";
CM_ SG_ 2566848495 锁车状态 "锁车状态 [枚举: 无效|车辆未锁|车辆已锁]";
VAL_ 2566848495 锁车状态 0 "无效" 1 "车辆未锁" 2 "车辆已锁";
CM_ SG_ 2566848495 锁车原因 "锁车原因 [枚举: 无效|终端命令锁车|终端通讯异常锁车|流量卡状态异常锁车]";
VAL_ 2566848495 锁车原因 0 "无效" 1 "终端命令锁车" 2 "终端通讯异常锁车" 3 "流量卡状态异常锁车";
CM_ SG_ 2566848495 远程锁车执行模式 "远程锁车执行模式 [枚举: 无效|闭锁指令缓存成功|闭锁指令缓存失败|缓存闭锁执行成功|缓存闭锁执行失败|解锁指令缓存成功|解锁指令缓存失败|缓存解锁执行成功|缓存解锁执行失败]";
VAL_ 2566848495 远程锁车执行模式 0 "无效" 1 "闭锁指令缓存成功" 2 "闭锁指令缓存失败" 3 "缓存闭锁执行成功" 4 "缓存闭锁执行失败" 5 "解锁指令缓存成功" 6 "解锁指令缓存失败" 7 "缓存解锁执行成功" 8 "缓存解锁执行失败";
CM_ SG_ 2566848495 剩余动车次数 "剩余动车次数 [枚举: 无效|剩余0次|剩余1次|剩余2次|剩余3次|剩余4次|剩余5次|剩余6次|剩余7次|剩余8次|剩余9次|剩余10次]";
VAL_ 2566848495 剩余动车次数 0 "无效" 1 "剩余0次" 2 "剩余1次" 3 "剩余2次" 4 "剩余3次" 5 "剩余4次" 6 "剩余5次" 7 "剩余6次" 8 "剩余7次" 9 "剩余8次" 10 "剩余9次" 11 "剩余10次";

BO_ 2566849200 ZT_18FF02B0: 8 Vector__XXX
 SG_ 终端锁车命令 : 8|2@1+ (1,0) [0|0] "" Vector__XXX
 SG_ 终端网络状态 : 16|2@1+ (1,0) [0|0] "" Vector__XXX
 SG_ 终端SIM 卡安装状态 : 18|2@1+ (1,0) [0|0] "" Vector__XXX
 SG_ 终端Life 信号 : 56|8@1+ (1,0) [0|255] "" Vector__XXX

BA_ "VFrameFormat" BO_ 2566849200 1;
CM_ BO_ 2566849200 "SIM 卡安装状态 / 信号 | 信号数 4";
CM_ SG_ 2566849200 终端锁车命令 "终端锁车命令 [枚举: 无请求|一级锁车|二级锁车|解锁]";
VAL_ 2566849200 终端锁车命令 0 "无请求" 1 "一级锁车" 2 "二级锁车" 3 "解锁";
CM_ SG_ 2566849200 终端网络状态 "终端网络状态 [枚举: 离线|在线]";
VAL_ 2566849200 终端网络状态 0 "离线" 1 "在线";
CM_ SG_ 2566849200 终端SIM 卡安装状态 "终端SIM 卡安装状态 [枚举: 未安装|已安装]";
VAL_ 2566849200 终端SIM 卡安装状态 0 "未安装" 1 "已安装";
CM_ SG_ 2566849200 终端Life 信号 "终端Life 信号";

BO_ 2566849519 ZT_18FF03EF: 8 Vector__XXX
 SG_ 终端锁车执行状态 : 0|8@1+ (1,0) [0|0] "" Vector__XXX
 SG_ 终端锁车原因 : 8|8@1+ (1,0) [0|0] "" Vector__XXX
 SG_ 终端通信Life : 56|8@1+ (1,0) [0|255] "" Vector__XXX

BA_ "VFrameFormat" BO_ 2566849519 1;
CM_ BO_ 2566849519 "终端通信Life / 终端锁车原因 | 信号数 9";
CM_ SG_ 2566849519 终端锁车执行状态 "终端锁车执行状态 [原始公式: if((BYTE[0])==1) 0; else if((BYTE[0])==2) 1; else if((BYTE[0])==3) 2; else if((BYTE[0])==4) 3; else if((BYTE[0])==5) 4; else 5] [枚举: 一级锁车已执行|收到一级锁车指令但未执行|二级锁车已执行|收到二级锁车指令但未执行|解锁|预留]";
CM_ SG_ 2566849519 终端锁车原因 "终端锁车原因 [原始公式: if((BYTE[1])==1) 0; else if((BYTE[1])==2) 1; else if((BYTE[1])==3) 2; else 3] [枚举: 未收到监控终端通知life值|未收到监控终端SIM卡安装状态|未收到监控终端锁车命令|预留]";
CM_ SG_ 2566849519 终端通信Life "终端通信Life";

BO_ 2566849794 ZT_18FF0502: 8 Vector__XXX
 SG_ 使能后氢控制器打开主阀 : 0|2@1+ (1,0) [0|3] "" Vector__XXX
 SG_ 使能后氢控制器打开所有瓶阀 : 2|2@1+ (1,0) [0|3] "" Vector__XXX

BA_ "VFrameFormat" BO_ 2566849794 1;
CM_ BO_ 2566849794 "使能后氢控制器打开主阀 / 使能后氢控制器打开所有瓶阀 | 信号数 2";
CM_ SG_ 2566849794 使能后氢控制器打开主阀 "使能后氢控制器打开主阀 [枚举: 关闭|打开]";
VAL_ 2566849794 使能后氢控制器打开主阀 0 "关闭" 1 "打开";
CM_ SG_ 2566849794 使能后氢控制器打开所有瓶阀 "使能后氢控制器打开所有瓶阀 [枚举: 关闭|打开]";
VAL_ 2566849794 使能后氢控制器打开所有瓶阀 0 "关闭" 1 "打开";

BO_ 2566852847 ZT_18FF10EF: 8 Vector__XXX
 SG_ 风扇使能 : 0|8@1+ (1,0) [0|255] "" Vector__XXX
 SG_ 目标温度 : 8|8@1+ (1,-40) [-40|215] "℃" Vector__XXX
 SG_ 电机转速 : 24|16@1+ (1,-15000) [0|1] "" Vector__XXX
 SG_ 驱动电机直流电压 : 40|16@1+ (0.1,0) [0|1] "" Vector__XXX

BA_ "VFrameFormat" BO_ 2566852847 1;
CM_ BO_ 2566852847 "MCU使能 / RCU状态 | 信号数 7";
CM_ SG_ 2566852847 风扇使能 "风扇使能 [枚举: 关闭|打开]";
VAL_ 2566852847 风扇使能 0 "关闭" 1 "打开";
CM_ SG_ 2566852847 目标温度 "目标温度";
CM_ SG_ 2566852847 电机转速 "电机转速";
CM_ SG_ 2566852847 驱动电机直流电压 "驱动电机直流电压";

BO_ 2566852851 ZT_18FF10F3: 8 Vector__XXX
 SG_ 电池包最高电压限制 : 0|8@1+ (4,0) [0|1000] "V" Vector__XXX
 SG_ 电池包最低电压限制 : 8|8@1+ (4,0) [0|1000] "V" Vector__XXX
 SG_ 接触器电池端电压 : 16|8@1+ (4,0) [0|1000] "V" Vector__XXX
 SG_ 接触器电机端电压 : 24|8@1+ (4,0) [0|1000] "V" Vector__XXX
 SG_ 单体最大电压-1 : 32|8@1+ (0.02,0) [0|5] "V" Vector__XXX
 SG_ 单体最小电压-1 : 40|8@1+ (0.02,0) [0|5] "V" Vector__XXX
 SG_ 单体累计电压 : 48|16@1+ (0.02,0) [0|1285.1] "V" Vector__XXX

BA_ "VFrameFormat" BO_ 2566852851 1;
CM_ BO_ 2566852851 "Cell  单体累计电压 / 单体最低电压 | 信号数 16";
CM_ SG_ 2566852851 电池包最高电压限制 "电池包最高电压限制";
CM_ SG_ 2566852851 电池包最低电压限制 "电池包最低电压限制";
CM_ SG_ 2566852851 接触器电池端电压 "接触器电池端电压";
CM_ SG_ 2566852851 接触器电机端电压 "接触器电机端电压";
CM_ SG_ 2566852851 单体最大电压-1 "单体最大电压-1";
CM_ SG_ 2566852851 单体最小电压-1 "单体最小电压-1";
CM_ SG_ 2566852851 单体累计电压 "单体累计电压";

BO_ 2566853107 ZT_18FF11F3: 8 Vector__XXX
 SG_ 充电电流限制 : 0|8@1+ (2,0) [0|500] "" Vector__XXX
 SG_ 放电电流限制 : 8|8@1+ (2,0) [0|500] "" Vector__XXX
 SG_ 充电功率限制 : 32|8@1+ (1.5,0) [0|375] "" Vector__XXX
 SG_ 放电功率限制-1 : 40|8@1+ (1.5,0) [0|375] "" Vector__XXX
 SG_ 电池总电流 : 16|16@1+ (0.02,-700) [-700|600] "" Vector__XXX
 SG_ 放电功率限制-2 : 48|16@1+ (0.01,-320) [-320|322.55] "" Vector__XXX

BA_ "VFrameFormat" BO_ 2566853107 1;
CM_ BO_ 2566853107 "充电功率限制 / 充电电流限制 | 信号数 24";
CM_ SG_ 2566853107 充电电流限制 "充电电流限制";
CM_ SG_ 2566853107 放电电流限制 "放电电流限制";
CM_ SG_ 2566853107 充电功率限制 "充电功率限制";
CM_ SG_ 2566853107 放电功率限制-1 "放电功率限制-1";
CM_ SG_ 2566853107 电池总电流 "电池总电流";
CM_ SG_ 2566853107 放电功率限制-2 "放电功率限制-2";

BO_ 2566853363 ZT_18FF12F3: 8 Vector__XXX
 SG_ 电池类型 : 0|4@1+ (1,0) [0|15] "" Vector__XXX
 SG_ 电池外并数量 : 4|4@1+ (1,0) [0|10] "个" Vector__XXX
 SG_ 单体标称电压 : 8|4@1+ (0.02,0) [0|5] "V" Vector__XXX
 SG_ 单体额定容量 : 16|8@1+ (2,0) [0|500] "Ah" Vector__XXX
 SG_ 电池串联数量 : 40|8@1+ (1,0) [0|250] "Count" Vector__XXX
 SG_ 电池并联数量 : 48|8@1+ (1,0) [0|250] "Count" Vector__XXX
 SG_ Soc最低限制 : 56|8@1+ (0.5,0) [0|125] "%" Vector__XXX
 SG_ 电池总能量 : 24|16@1+ (0.01,0) [0|642.55] "kWh" Vector__XXX

BA_ "VFrameFormat" BO_ 2566853363 1;
CM_ BO_ 2566853363 "SOC最低限值 / SOC最低限制 | 信号数 34";
CM_ SG_ 2566853363 电池类型 "电池类型 [枚举: 异常|磷酸铁锂|锰酸锂|钴酸锂|三元材料|聚合物锂离子|超级电容|钛酸锂|燃料电池|其他车载储能装置]";
VAL_ 2566853363 电池类型 0 "异常" 1 "磷酸铁锂" 2 "锰酸锂" 3 "钴酸锂" 4 "三元材料" 5 "聚合物锂离子" 6 "超级电容" 7 "钛酸锂" 8 "燃料电池" 9 "其他车载储能装置";
CM_ SG_ 2566853363 电池外并数量 "电池外并数量";
CM_ SG_ 2566853363 单体标称电压 "单体标称电压";
CM_ SG_ 2566853363 单体额定容量 "单体额定容量";
CM_ SG_ 2566853363 电池串联数量 "电池串联数量";
CM_ SG_ 2566853363 电池并联数量 "电池并联数量";
CM_ SG_ 2566853363 Soc最低限制 "Soc最低限制";
CM_ SG_ 2566853363 电池总能量 "电池总能量";

BO_ 2566853619 ZT_18FF13F3: 8 Vector__XXX
 SG_ 1#散热风扇运行状态 : 32|2@1+ (1,0) [0|3] "" Vector__XXX
 SG_ 2#散热风扇运行状态 : 34|2@1+ (1,0) [0|3] "" Vector__XXX
 SG_ 3#散热风扇运行状态 : 36|2@1+ (1,0) [0|3] "" Vector__XXX
 SG_ 4#散热风扇运行状态 : 38|2@1+ (1,0) [0|3] "" Vector__XXX
 SG_ 5#散热风扇运行状态 : 40|2@1+ (1,0) [0|3] "" Vector__XXX
 SG_ 6#散热风扇运行状态 : 42|2@1+ (1,0) [0|3] "" Vector__XXX
 SG_ 7#散热风扇运行状态 : 44|2@1+ (1,0) [0|3] "" Vector__XXX
 SG_ 8#散热风扇运行状态 : 46|2@1+ (1,0) [0|3] "" Vector__XXX
 SG_ 9#散热风扇运行状态 : 48|2@1+ (1,0) [0|3] "" Vector__XXX
 SG_ 10#散热风扇运行状态 : 50|2@1+ (1,0) [0|3] "" Vector__XXX
 SG_ 11#散热风扇运行状态 : 52|2@1+ (1,0) [0|3] "" Vector__XXX
 SG_ 电池加热装置运行状态 : 62|2@1+ (1,0) [0|3] "" Vector__XXX
 SG_ 加热装置运行状态 : 60|2@1+ (1,0) [0|3] "" Vector__XXX
 SG_ 最高温度限制 : 0|8@1+ (1,-40) [-40|210] "℃" Vector__XXX
 SG_ 单体电池最高温度 : 8|8@1+ (1,-40) [-40|210] "℃" Vector__XXX
 SG_ 单体电池最低温度 : 16|8@1+ (1,-40) [-40|210] "℃" Vector__XXX
 SG_ 进风/进水口温度 : 24|8@1+ (1,-40) [-40|250] "℃" Vector__XXX

BA_ "VFrameFormat" BO_ 2566853619 1;
CM_ BO_ 2566853619 "1#散热风扇运行状态 / 1#箱散热风扇运行状态 | 信号数 82";
CM_ SG_ 2566853619 1#散热风扇运行状态 "1#散热风扇运行状态 [枚举: 停止|运行|运行|未激活]";
VAL_ 2566853619 1#散热风扇运行状态 0 "停止" 1 "运行" 2 "运行" 3 "未激活";
CM_ SG_ 2566853619 2#散热风扇运行状态 "2#散热风扇运行状态 [枚举: 停止|运行|运行|未激活]";
VAL_ 2566853619 2#散热风扇运行状态 0 "停止" 1 "运行" 2 "运行" 3 "未激活";
CM_ SG_ 2566853619 3#散热风扇运行状态 "3#散热风扇运行状态 [枚举: 停止|运行|运行|未激活]";
VAL_ 2566853619 3#散热风扇运行状态 0 "停止" 1 "运行" 2 "运行" 3 "未激活";
CM_ SG_ 2566853619 4#散热风扇运行状态 "4#散热风扇运行状态 [枚举: 停止|运行|运行|未激活]";
VAL_ 2566853619 4#散热风扇运行状态 0 "停止" 1 "运行" 2 "运行" 3 "未激活";
CM_ SG_ 2566853619 5#散热风扇运行状态 "5#散热风扇运行状态 [枚举: 停止|运行|运行|未激活]";
VAL_ 2566853619 5#散热风扇运行状态 0 "停止" 1 "运行" 2 "运行" 3 "未激活";
CM_ SG_ 2566853619 6#散热风扇运行状态 "6#散热风扇运行状态 [枚举: 停止|运行|运行|未激活]";
VAL_ 2566853619 6#散热风扇运行状态 0 "停止" 1 "运行" 2 "运行" 3 "未激活";
CM_ SG_ 2566853619 7#散热风扇运行状态 "7#散热风扇运行状态 [枚举: 停止|运行|运行|未激活]";
VAL_ 2566853619 7#散热风扇运行状态 0 "停止" 1 "运行" 2 "运行" 3 "未激活";
CM_ SG_ 2566853619 8#散热风扇运行状态 "8#散热风扇运行状态 [枚举: 停止|运行|运行|未激活]";
VAL_ 2566853619 8#散热风扇运行状态 0 "停止" 1 "运行" 2 "运行" 3 "未激活";
CM_ SG_ 2566853619 9#散热风扇运行状态 "9#散热风扇运行状态 [枚举: 停止|运行|运行|未激活]";
VAL_ 2566853619 9#散热风扇运行状态 0 "停止" 1 "运行" 2 "运行" 3 "未激活";
CM_ SG_ 2566853619 10#散热风扇运行状态 "10#散热风扇运行状态 [枚举: 停止|运行|运行|未激活]";
VAL_ 2566853619 10#散热风扇运行状态 0 "停止" 1 "运行" 2 "运行" 3 "未激活";
CM_ SG_ 2566853619 11#散热风扇运行状态 "11#散热风扇运行状态 [枚举: 停止|运行|运行|未激活]";
VAL_ 2566853619 11#散热风扇运行状态 0 "停止" 1 "运行" 2 "运行" 3 "未激活";
CM_ SG_ 2566853619 电池加热装置运行状态 "电池加热装置运行状态 [枚举: 停止|运行|运行|未激活]";
VAL_ 2566853619 电池加热装置运行状态 0 "停止" 1 "运行" 2 "运行" 3 "未激活";
CM_ SG_ 2566853619 加热装置运行状态 "加热装置运行状态 [枚举: 停止|运行|运行|未激活]";
VAL_ 2566853619 加热装置运行状态 0 "停止" 1 "运行" 2 "运行" 3 "未激活";
CM_ SG_ 2566853619 最高温度限制 "最高温度限制";
CM_ SG_ 2566853619 单体电池最高温度 "单体电池最高温度";
CM_ SG_ 2566853619 单体电池最低温度 "单体电池最低温度";
CM_ SG_ 2566853619 进风/进水口温度 "进风/进水口温度";

BO_ 2566853875 ZT_18FF14F3: 8 Vector__XXX
 SG_ 主正接触器状态 : 0|2@1+ (1,0) [0|3] "" Vector__XXX
 SG_ 主负接触器状态 : 2|2@1+ (1,0) [0|3] "" Vector__XXX
 SG_ 预充接触器状态 : 4|2@1+ (1,0) [0|3] "" Vector__XXX
 SG_ 充电接触器状态 : 6|2@1+ (1,0) [0|3] "" Vector__XXX
 SG_ 辅助接触器状态 : 60|2@1+ (1,0) [0|3] "" Vector__XXX
 SG_ 加热接触器状态 : 62|2@1+ (1,0) [0|3] "" Vector__XXX
 SG_ 充电枪连接状态 : 39|3@1+ (1,0) [0|7] "" Vector__XXX
 SG_ 电池状态 : 32|4@1+ (1,0) [0|15] "" Vector__XXX
 SG_ 电池寿命状态 : 24|8@1+ (1,0) [0|100] "%" Vector__XXX
 SG_ 剩余电池电量 : 48|8@1+ (1,0) [0|500] "Kwh" Vector__XXX
 SG_ 电池电量状态 : 8|16@1+ (0.0025,0) [0|100] "%" Vector__XXX

BA_ "VFrameFormat" BO_ 2566853875 1;
CM_ BO_ 2566853875 "主正接触器状态 / 主负接触器状态 | 信号数 76";
CM_ SG_ 2566853875 主正接触器状态 "主正接触器状态 [枚举: 接触器开|接触器关|错误|未激活]";
VAL_ 2566853875 主正接触器状态 0 "接触器开" 1 "接触器关" 2 "错误" 3 "未激活";
CM_ SG_ 2566853875 主负接触器状态 "主负接触器状态 [枚举: 接触器开|接触器关|错误|未激活]";
VAL_ 2566853875 主负接触器状态 0 "接触器开" 1 "接触器关" 2 "错误" 3 "未激活";
CM_ SG_ 2566853875 预充接触器状态 "预充接触器状态 [枚举: 接触器开|接触器关|错误|未激活]";
VAL_ 2566853875 预充接触器状态 0 "接触器开" 1 "接触器关" 2 "错误" 3 "未激活";
CM_ SG_ 2566853875 充电接触器状态 "充电接触器状态 [枚举: 接触器开|接触器关|错误|未激活]";
VAL_ 2566853875 充电接触器状态 0 "接触器开" 1 "接触器关" 2 "错误" 3 "未激活";
CM_ SG_ 2566853875 辅助接触器状态 "辅助接触器状态 [枚举: 接触器开|接触器开|错误|未激活]";
VAL_ 2566853875 辅助接触器状态 0 "接触器开" 1 "接触器开" 2 "错误" 3 "未激活";
CM_ SG_ 2566853875 加热接触器状态 "加热接触器状态 [枚举: 接触器开|接触器开|错误|未激活]";
VAL_ 2566853875 加热接触器状态 0 "接触器开" 1 "接触器开" 2 "错误" 3 "未激活";
CM_ SG_ 2566853875 充电枪连接状态 "充电枪连接状态 [枚举: 未连接|已连接]";
VAL_ 2566853875 充电枪连接状态 0 "未连接" 1 "已连接";
CM_ SG_ 2566853875 电池状态 "电池状态 [枚举: Power_UP|Standby|Precharge|Ready|Opening|Save|Reserved|Reserved|Reserved|Reserved|Reserved|Reserved|Reserved|Reserved|Reserved|NotAvailable]";
VAL_ 2566853875 电池状态 0 "Power_UP" 1 "Standby" 2 "Precharge" 3 "Ready" 4 "Opening" 5 "Save" 6 "Reserved" 7 "Reserved" 8 "Reserved" 9 "Reserved" 10 "Reserved" 11 "Reserved" 12 "Reserved" 13 "Reserved" 14 "Reserved" 15 "NotAvailable";
CM_ SG_ 2566853875 电池寿命状态 "电池寿命状态";
CM_ SG_ 2566853875 剩余电池电量 "剩余电池电量";
CM_ SG_ 2566853875 电池电量状态 "电池电量状态";

BO_ 2566854131 ZT_18FF15F3: 8 Vector__XXX
 SG_ 最高单体电压所在箱体编号 : 40|6@1+ (1,0) [0|250] "" Vector__XXX
 SG_ 最低单体电压所在箱体编号 : 46|6@1+ (1,0) [0|250] "" Vector__XXX
 SG_ 最高单体温度所在箱体编号 : 52|6@1+ (1,0) [0|250] "" Vector__XXX
 SG_ 最低单体温度所在箱体编号 : 58|6@1+ (1,0) [0|250] "" Vector__XXX
 SG_ 最高单体电压编号 : 0|8@1+ (1,0) [0|1000] "" Vector__XXX
 SG_ 最高单体温度编号 : 24|8@1+ (1,0) [0|250] "" Vector__XXX
 SG_ 最低单体温度编号 : 32|8@1+ (1,0) [0|250] "" Vector__XXX
 SG_ 最低单体电压编号 : 12|12@1+ (1,0) [0|1000] "" Vector__XXX

BA_ "VFrameFormat" BO_ 2566854131 1;
CM_ BO_ 2566854131 "最低单体温度所在箱体编号 / 最低单体温度编号 | 信号数 48";
CM_ SG_ 2566854131 最高单体电压所在箱体编号 "最高单体电压所在箱体编号";
CM_ SG_ 2566854131 最低单体电压所在箱体编号 "最低单体电压所在箱体编号";
CM_ SG_ 2566854131 最高单体温度所在箱体编号 "最高单体温度所在箱体编号";
CM_ SG_ 2566854131 最低单体温度所在箱体编号 "最低单体温度所在箱体编号";
CM_ SG_ 2566854131 最高单体电压编号 "最高单体电压编号 [原始公式: (BYTE[0]+BYTE[1]*256)&4095]";
CM_ SG_ 2566854131 最高单体温度编号 "最高单体温度编号";
CM_ SG_ 2566854131 最低单体温度编号 "最低单体温度编号";
CM_ SG_ 2566854131 最低单体电压编号 "最低单体电压编号";

BO_ 2566854387 ZT_18FF16F3: 8 Vector__XXX
 SG_ 支路1累计电压 : 0|16@1+ (0.02,0) [0|1285.1] "V" Vector__XXX
 SG_ 支路2累计电压 : 16|16@1+ (0.02,0) [0|1285.1] "V" Vector__XXX
 SG_ 支路3累计电压 : 32|16@1+ (0.02,0) [0|1350] "V" Vector__XXX

BA_ "VFrameFormat" BO_ 2566854387 1;
CM_ BO_ 2566854387 "支路1累计电压 / 支路2累计电压 | 信号数 6";
CM_ SG_ 2566854387 支路1累计电压 "支路1累计电压";
CM_ SG_ 2566854387 支路2累计电压 "支路2累计电压";
CM_ SG_ 2566854387 支路3累计电压 "支路3累计电压";

BO_ 2566854639 ZT_18FF17EF: 8 Vector__XXX
 SG_ 周期内电耗/次 : 0|16@1+ (0.01,0) [0|655.35] "kWh" Vector__XXX
 SG_ 平均电耗 : 32|16@1+ (0.01,-300) [-300|355.35] "kWh/km" Vector__XXX
 SG_ VCH保存的平均电耗 : 48|16@1+ (0.01,-300) [-300|355.35] "kWh/km" Vector__XXX

BA_ "VFrameFormat" BO_ 2566854639 1;
CM_ BO_ 2566854639 "VCH保存的平均电耗 / VCU 保存的平均电耗数值 | 信号数 15";
CM_ SG_ 2566854639 周期内电耗/次 "周期内电耗/次";
CM_ SG_ 2566854639 平均电耗 "平均电耗";
CM_ SG_ 2566854639 VCH保存的平均电耗 "VCH保存的平均电耗";

BO_ 2566854643 ZT_18FF17F3: 8 Vector__XXX
 SG_ 充电机最大电流限制 : 48|8@1+ (3,0) [0|800] "V" Vector__XXX
 SG_ 支路1电流 : 0|16@1+ (0.0125,-400) [-400|400] "A" Vector__XXX
 SG_ 支路2电流 : 16|16@1+ (0.0125,-400) [-400|400] "A" Vector__XXX
 SG_ 支路3电流 : 32|16@1+ (0.0125,-400) [-400|500] "A" Vector__XXX

BA_ "VFrameFormat" BO_ 2566854643 1;
CM_ BO_ 2566854643 "充电机最大电流限制 / 支路1电流 | 信号数 8";
CM_ SG_ 2566854643 充电机最大电流限制 "充电机最大电流限制";
CM_ SG_ 2566854643 支路1电流 "支路1电流";
CM_ SG_ 2566854643 支路2电流 "支路2电流";
CM_ SG_ 2566854643 支路3电流 "支路3电流";

BO_ 2566854899 ZT_18FF18F3: 8 Vector__XXX
 SG_ 电池剩余能量 : 48|8@1+ (1,0) [0|1000000] "Kwh" Vector__XXX
 SG_ 生命周期内 放电总能量 : 0|24@1+ (0.1,0) [0|1000000] "Kwh" Vector__XXX
 SG_ 生命周期内 充电总能量 : 24|24@1+ (0.1,0) [0|1000000] "Kwh" Vector__XXX

BA_ "VFrameFormat" BO_ 2566854899 1;
CM_ BO_ 2566854899 "REESS生命周期内 充电总能量 / REESS生命周期内 放电总能量 | 信号数 21";
CM_ SG_ 2566854899 电池剩余能量 "电池剩余能量 [原始公式: ((BYTE[6]+BYTE[7]*256)&1023)*0.1]";
CM_ SG_ 2566854899 生命周期内 放电总能量 "生命周期内 放电总能量";
CM_ SG_ 2566854899 生命周期内 充电总能量 "生命周期内 充电总能量";

BO_ 2566855407 ZT_18FF1AEF: 8 Vector__XXX
 SG_ 主控制器控制指令 : 0|2@1+ (1,0) [0|0] "" Vector__XXX
 SG_ 主辅助接触器控制指令 : 2|2@1+ (1,0) [0|0] "" Vector__XXX
 SG_ 2 # 辅助接触器控制指令 : 4|2@1+ (1,0) [0|0] "" Vector__XXX
 SG_ 温度控制请求 : 8|2@1+ (1,0) [0|0] "" Vector__XXX
 SG_ 关机命令 : 10|2@1+ (1,0) [0|0] "" Vector__XXX
 SG_ 充电连接信号 : 12|2@1+ (1,0) [0|0] "" Vector__XXX
 SG_ 空调接触器控制指令 : 6|2@1+ (1,0) [0|1] "" Vector__XXX
 SG_ 电除霜接触器控制指令 : 14|2@1+ (1,0) [0|1] "" Vector__XXX
 SG_ 电暖风接触器控制指令 : 16|2@1+ (1,0) [0|1] "" Vector__XXX
 SG_ DCDC接触器控制指令 : 18|2@1+ (1,0) [0|0] "" Vector__XXX
 SG_ 报文计数器 : 56|4@1+ (1,0) [0|15] "" Vector__XXX
 SG_ 报文校验码 : 60|4@1+ (1,0) [0|15] "" Vector__XXX

BA_ "VFrameFormat" BO_ 2566855407 1;
CM_ BO_ 2566855407 "2 # 辅助接触器控制指令 / DCDC接触器控制指令 | 信号数 33";
CM_ SG_ 2566855407 主控制器控制指令 "主控制器控制指令 [枚举: 下高压|上高压]";
VAL_ 2566855407 主控制器控制指令 0 "下高压" 1 "上高压";
CM_ SG_ 2566855407 主辅助接触器控制指令 "主辅助接触器控制指令 [枚举: 断开|闭合]";
VAL_ 2566855407 主辅助接触器控制指令 0 "断开" 1 "闭合";
CM_ SG_ 2566855407 2 # 辅助接触器控制指令 "2 # 辅助接触器控制指令 [枚举: 断开|闭合]";
VAL_ 2566855407 2 # 辅助接触器控制指令 0 "断开" 1 "闭合";
CM_ SG_ 2566855407 温度控制请求 "温度控制请求 [枚举: 断开|闭合]";
VAL_ 2566855407 温度控制请求 0 "断开" 1 "闭合";
CM_ SG_ 2566855407 关机命令 "关机命令 [枚举: 断开|闭合]";
VAL_ 2566855407 关机命令 0 "断开" 1 "闭合";
CM_ SG_ 2566855407 充电连接信号 "充电连接信号 [枚举: 未连接|已连接]";
VAL_ 2566855407 充电连接信号 0 "未连接" 1 "已连接";
CM_ SG_ 2566855407 空调接触器控制指令 "空调接触器控制指令 [枚举: 断开|闭合]";
VAL_ 2566855407 空调接触器控制指令 0 "断开" 1 "闭合";
CM_ SG_ 2566855407 电除霜接触器控制指令 "电除霜接触器控制指令 [枚举: 断开|闭合]";
VAL_ 2566855407 电除霜接触器控制指令 0 "断开" 1 "闭合";
CM_ SG_ 2566855407 电暖风接触器控制指令 "电暖风接触器控制指令 [枚举: 断开|闭合]";
VAL_ 2566855407 电暖风接触器控制指令 0 "断开" 1 "闭合";
CM_ SG_ 2566855407 DCDC接触器控制指令 "DCDC接触器控制指令";
CM_ SG_ 2566855407 报文计数器 "报文计数器";
CM_ SG_ 2566855407 报文校验码 "报文校验码";

BO_ 2566855411 ZT_18FF1AF3: 8 Vector__XXX
 SG_ 电池端总电压 : 0|32@1+ (0.001,0) [0|1000] "V" Vector__XXX
 SG_ 电机端总电压 : 32|32@1+ (0.001,0) [0|1000] "V" Vector__XXX

BA_ "VFrameFormat" BO_ 2566855411 1;
CM_ BO_ 2566855411 "主正接触器电池电压 / 电机端总电压 | 信号数 10";
CM_ SG_ 2566855411 电池端总电压 "电池端总电压";
CM_ SG_ 2566855411 电机端总电压 "电机端总电压";

BO_ 2566856947 ZT_18FF20F3: 8 Vector__XXX
 SG_ 单体最大SOC : 40|8@1+ (0.5,0) [0|127.5] "%" Vector__XXX
 SG_ 单体最小SOC : 48|8@1+ (0.5,0) [0|127.5] "%" Vector__XXX
 SG_ 充电次数 : 24|8@1+ (1,0) [0|60000] "" Vector__XXX
 SG_ 生命周期内制动回收总能量 : 0|24@1+ (0.1,0) [0|1000000] "Kwh" Vector__XXX

BA_ "VFrameFormat" BO_ 2566856947 1;
CM_ BO_ 2566856947 "REESS生命周期充电次数统 / REESS生命周期内制动能量回 收总能量 | 信号数 16";
CM_ SG_ 2566856947 单体最大SOC "单体最大SOC";
CM_ SG_ 2566856947 单体最小SOC "单体最小SOC";
CM_ SG_ 2566856947 充电次数 "充电次数";
CM_ SG_ 2566856947 生命周期内制动回收总能量 "生命周期内制动回收总能量";

BO_ 2566860818 ZT_18FF3012: 8 Vector__XXX
 SG_ 锁定状态激活 : 61|1@1+ (1,0) [0|0] "" Vector__XXX
 SG_ SIS互锁 : 62|1@1+ (1,0) [0|0] "" Vector__XXX
 SG_ 氢气供气阀使能 : 56|2@1+ (1,0) [0|0] "" Vector__XXX
 SG_ 故障等级 : 8|8@1+ (1,0) [0|255] "" Vector__XXX
 SG_ 燃料电池发动机心跳信号 : 0|8@1+ (1,0) [0|255] "" Vector__XXX
 SG_ 燃料电池发动机允许输出最大电流 : 16|16@1+ (0.1,0) [-500|500] "A" Vector__XXX

BA_ "VFrameFormat" BO_ 2566860818 1;
CM_ BO_ 2566860818 "SIS互锁 / 故障等级 | 信号数 6";
CM_ SG_ 2566860818 锁定状态激活 "锁定状态激活 [枚举: 激活|未激活]";
VAL_ 2566860818 锁定状态激活 0 "激活" 1 "未激活";
CM_ SG_ 2566860818 SIS互锁 "SIS互锁 [枚举: 正常|互锁]";
VAL_ 2566860818 SIS互锁 0 "正常" 1 "互锁";
CM_ SG_ 2566860818 氢气供气阀使能 "氢气供气阀使能 [枚举: 关闭指令|开启指令]";
VAL_ 2566860818 氢气供气阀使能 0 "关闭指令" 1 "开启指令";
CM_ SG_ 2566860818 故障等级 "故障等级 [枚举: 一级故障|二级故障|三级故障]";
VAL_ 2566860818 故障等级 0 "一级故障" 1 "二级故障" 2 "三级故障";
CM_ SG_ 2566860818 燃料电池发动机心跳信号 "燃料电池发动机心跳信号";
CM_ SG_ 2566860818 燃料电池发动机允许输出最大电流 "燃料电池发动机允许输出最大电流";

BO_ 2566861074 ZT_18FF3112: 8 Vector__XXX
 SG_ 燃料电池发动机工作状态 : 24|8@1+ (1,0) [0|255] "" Vector__XXX
 SG_ 电堆输出电压 : 0|16@1+ (1,-500) [-500|1000] "V" Vector__XXX

BA_ "VFrameFormat" BO_ 2566861074 1;
CM_ BO_ 2566861074 "燃料电池发动机工作状态 / 电堆输出电压 | 信号数 3";
CM_ SG_ 2566861074 燃料电池发动机工作状态 "燃料电池发动机工作状态 [原始公式: if((BYTE[3])==10) 0; else if((BYTE[3])==20) 1; else if((BYTE[3])==25) 2; else if((BYTE[3])==40) 3; else if((BYTE[3])==100) 4; else if((BYTE[3])==138) 5; else 6] [枚举: 锁止状态|休眠状态|解锁状态|等待状态|运行状态|紧急停机状态|预留]";
CM_ SG_ 2566861074 电堆输出电压 "电堆输出电压";

BO_ 2566861330 ZT_18FF3212: 8 Vector__XXX
 SG_ 燃料电池发动机冷却水入口温度 : 0|8@1+ (1,-40) [-40|214] "℃" Vector__XXX
 SG_ 燃料电池发动机冷却水出口温度 : 8|8@1+ (1,-40) [-40|214] "℃" Vector__XXX
 SG_ 空压机入口温度 : 24|8@1+ (1,-40) [-40|214] "℃" Vector__XXX
 SG_ 氢气浓度（传感器） : 32|8@1+ (0.02,0) [0|5.08] "%" Vector__XXX

BA_ "VFrameFormat" BO_ 2566861330 1;
CM_ BO_ 2566861330 "氢气浓度（传感器） / 燃料电池发动机冷却水入口温度 | 信号数 4";
CM_ SG_ 2566861330 燃料电池发动机冷却水入口温度 "燃料电池发动机冷却水入口温度";
CM_ SG_ 2566861330 燃料电池发动机冷却水出口温度 "燃料电池发动机冷却水出口温度";
CM_ SG_ 2566861330 空压机入口温度 "空压机入口温度";
CM_ SG_ 2566861330 氢气浓度（传感器） "氢气浓度（传感器）";

BO_ 2566861586 ZT_18FF3312: 8 Vector__XXX
 SG_ 空压机电机温度 : 0|8@1+ (1,-40) [0|214] "℃" Vector__XXX
 SG_ 空压机控制器温度 : 16|8@1+ (1,0) [0|214] "℃" Vector__XXX
 SG_ 氢气入堆压力 : 24|8@1+ (0.01,-0.25) [0|2.29] "bar" Vector__XXX

BA_ "VFrameFormat" BO_ 2566861586 1;
CM_ BO_ 2566861586 "氢气入堆压力 / 空压机控制器温度 | 信号数 3";
CM_ SG_ 2566861586 空压机电机温度 "空压机电机温度";
CM_ SG_ 2566861586 空压机控制器温度 "空压机控制器温度 [原始公式: if((BYTE[2])==18446744073709551576) @1; else BYTE[2]-40] [枚举: %d|未启用]";
CM_ SG_ 2566861586 氢气入堆压力 "氢气入堆压力";

BO_ 2566866420 ZT_18FF45F4: 8 Vector__XXX
 SG_ TMS上高压指令 : 2|2@1+ (1,0) [0|0] "" Vector__XXX
 SG_ 电池充放电状态 : 4|2@1+ (1,0) [0|0] "" Vector__XXX
 SG_ 辅助接触器状态 : 6|2@1+ (1,0) [0|0] "" Vector__XXX
 SG_ 液冷需求信号 : 40|2@1+ (1,0) [0|0] "" Vector__XXX
 SG_ TMS工作模式控制状态 : 0|2@1+ (1,0) [0|3] "" Vector__XXX
 SG_ 电池单体最高温度 : 24|8@1+ (1,-40) [-40|210] "deg C" Vector__XXX
 SG_ BMS电池出水温度 : 32|8@1+ (1,-40) [-40|215] "deg C" Vector__XXX
 SG_ BMS生命值 : 48|8@1+ (1,0) [0|255] "" Vector__XXX
 SG_ CRC校验值 : 56|8@1+ (1,0) [0|255] "" Vector__XXX
 SG_ 电池总电压 : 8|16@1+ (1,0) [0|1000] "V" Vector__XXX

BA_ "VFrameFormat" BO_ 2566866420 1;
CM_ BO_ 2566866420 "BMS校验信号 / BMS生命值 | 信号数 16";
CM_ SG_ 2566866420 TMS上高压指令 "TMS上高压指令 [枚举: 上电|下电]";
VAL_ 2566866420 TMS上高压指令 0 "上电" 1 "下电";
CM_ SG_ 2566866420 电池充放电状态 "电池充放电状态 [枚举: 放电状态（行车状态）|充电状态（外接充电）]";
VAL_ 2566866420 电池充放电状态 0 "放电状态（行车状态）" 1 "充电状态（外接充电）";
CM_ SG_ 2566866420 辅助接触器状态 "辅助接触器状态 [枚举: 接触器断开|接触器闭合]";
VAL_ 2566866420 辅助接触器状态 0 "接触器断开" 1 "接触器闭合";
CM_ SG_ 2566866420 液冷需求信号 "液冷需求信号 [枚举: 无信号|有信号]";
VAL_ 2566866420 液冷需求信号 0 "无信号" 1 "有信号";
CM_ SG_ 2566866420 TMS工作模式控制状态 "TMS工作模式控制状态";
CM_ SG_ 2566866420 电池单体最高温度 "电池单体最高温度";
CM_ SG_ 2566866420 BMS电池出水温度 "BMS电池出水温度";
CM_ SG_ 2566866420 BMS生命值 "BMS生命值";
CM_ SG_ 2566866420 CRC校验值 "CRC校验值";
CM_ SG_ 2566866420 电池总电压 "电池总电压";

BO_ 2566867695 ZT_18FF4AEF: 8 Vector__XXX
 SG_ 功率受限状态 : 2|1@1+ (1,0) [0|0] "" Vector__XXX
 SG_ 制动信号-2 : 52|1@1+ (1,0) [0|0] "" Vector__XXX
 SG_ 驱动信号 : 53|1@1+ (1,0) [0|0] "" Vector__XXX
 SG_ 整车系统状态 : 0|2@1+ (1,0) [0|0] "" Vector__XXX
 SG_ 手刹信号-2 : 3|2@1+ (1,0) [0|0] "" Vector__XXX
 SG_ 档位信号-1 : 5|2@1+ (1,0) [0|0] "" Vector__XXX
 SG_ 主接触器状态 : 22|2@1+ (1,0) [0|0] "" Vector__XXX
 SG_ 发动机状态 : 24|2@1+ (1,0) [0|0] "" Vector__XXX
 SG_ 系统类型识别（vcu转发给EPB） : 16|2@1+ (1,0) [0|3] "" Vector__XXX
 SG_ 档位信号 : 48|4@1+ (1,0) [0|15] "" Vector__XXX
 SG_ 整车运行模式 : 8|8@1+ (1,0) [0|0] "" Vector__XXX
 SG_ 油门模拟信号 : 32|8@1+ (0.4,0) [0|100] "%" Vector__XXX
 SG_ 制动模拟信号 : 40|8@1+ (0.4,0) [0|100] "%" Vector__XXX
 SG_ 车辆状态 : 56|8@1+ (1,0) [0|0] "" Vector__XXX

BA_ "VFrameFormat" BO_ 2566867695 1;
CM_ BO_ 2566867695 "ON档电/车辆状态 / 主接触器状态 | 信号数 48";
CM_ SG_ 2566867695 功率受限状态 "功率受限状态 [枚举: 正常|功率受限]";
VAL_ 2566867695 功率受限状态 0 "正常" 1 "功率受限";
CM_ SG_ 2566867695 制动信号-2 "制动信号-2 [枚举: 无效|有效]";
VAL_ 2566867695 制动信号-2 0 "无效" 1 "有效";
CM_ SG_ 2566867695 驱动信号 "驱动信号 [枚举: 无效|有效]";
VAL_ 2566867695 驱动信号 0 "无效" 1 "有效";
CM_ SG_ 2566867695 整车系统状态 "整车系统状态 [枚举: 无效|准备就绪（高压闭合）|有故障|无效]";
VAL_ 2566867695 整车系统状态 0 "无效" 1 "准备就绪（高压闭合）" 2 "有故障" 3 "无效";
CM_ SG_ 2566867695 手刹信号-2 "手刹信号-2 [枚举: 无效|手刹松开|手刹拉起|无效]";
VAL_ 2566867695 手刹信号-2 0 "无效" 1 "手刹松开" 2 "手刹拉起" 3 "无效";
CM_ SG_ 2566867695 档位信号-1 "档位信号-1 [枚举: N空挡|D前进挡|R倒挡]";
VAL_ 2566867695 档位信号-1 0 "N空挡" 1 "D前进挡" 2 "R倒挡";
CM_ SG_ 2566867695 主接触器状态 "主接触器状态 [枚举: 闭合|断开]";
VAL_ 2566867695 主接触器状态 0 "闭合" 1 "断开";
CM_ SG_ 2566867695 发动机状态 "发动机状态 [枚举: 启动|关闭]";
VAL_ 2566867695 发动机状态 0 "启动" 1 "关闭";
CM_ SG_ 2566867695 系统类型识别（vcu转发给EPB） "系统类型识别（vcu转发给EPB）";
CM_ SG_ 2566867695 档位信号 "档位信号";
CM_ SG_ 2566867695 整车运行模式 "整车运行模式 [原始公式: if((BYTE[1])==1) 0; else if((BYTE[1])==2) 1; else if((BYTE[1])==3) 2; else 3] [枚举: 纯电|混动|燃油|预留]";
CM_ SG_ 2566867695 油门模拟信号 "油门模拟信号";
CM_ SG_ 2566867695 制动模拟信号 "制动模拟信号";
CM_ SG_ 2566867695 车辆状态 "车辆状态 [原始公式: if((BYTE[7])==1) 0; else if((BYTE[7])==2) 1; else if((BYTE[7])==3) 2; else if((BYTE[7])==254) 3; else if((BYTE[7])==255) 4; else 5] [枚举: 启动|熄火|其他状态|异常|无效状态|预留]";

BO_ 2566869251 ZT_18FF5103: 8 Vector__XXX
 SG_ 风扇信号反馈 : 6|2@1+ (1,0) [0|3] "" Vector__XXX
 SG_ 液位信号反馈 : 8|8@1+ (1,0) [0|0] "" Vector__XXX
 SG_ 风扇1/5故障反馈 : 32|8@1+ (1,0) [0|255] "" Vector__XXX
 SG_ 风扇2/6故障反馈 : 40|8@1+ (1,0) [0|255] "" Vector__XXX
 SG_ 风扇3/7故障反馈 : 48|8@1+ (1,0) [0|255] "" Vector__XXX
 SG_ 风扇1/2故障反馈 : 56|8@1+ (1,0) [0|255] "" Vector__XXX
 SG_ 进水口温度 : 16|8@1+ (0.5,-40) [-40|85] "℃" Vector__XXX
 SG_ 出水口温度 : 24|8@1+ (0.5,-40) [-40|85] "℃" Vector__XXX

BA_ "VFrameFormat" BO_ 2566869251 1;
CM_ BO_ 2566869251 "出水口温度 / 液位信号反馈 | 信号数 8";
CM_ SG_ 2566869251 风扇信号反馈 "风扇信号反馈 [枚举: 打开|关闭]";
VAL_ 2566869251 风扇信号反馈 0 "打开" 1 "关闭";
CM_ SG_ 2566869251 液位信号反馈 "液位信号反馈 [枚举: 有效|无效]";
VAL_ 2566869251 液位信号反馈 0 "有效" 1 "无效";
CM_ SG_ 2566869251 风扇1/5故障反馈 "风扇1/5故障反馈 [枚举: 有效|无效]";
VAL_ 2566869251 风扇1/5故障反馈 0 "有效" 1 "无效";
CM_ SG_ 2566869251 风扇2/6故障反馈 "风扇2/6故障反馈 [枚举: 有效|无效]";
VAL_ 2566869251 风扇2/6故障反馈 0 "有效" 1 "无效";
CM_ SG_ 2566869251 风扇3/7故障反馈 "风扇3/7故障反馈 [枚举: 有效|无效]";
VAL_ 2566869251 风扇3/7故障反馈 0 "有效" 1 "无效";
CM_ SG_ 2566869251 风扇1/2故障反馈 "风扇1/2故障反馈 [枚举: 有效|无效]";
VAL_ 2566869251 风扇1/2故障反馈 0 "有效" 1 "无效";
CM_ SG_ 2566869251 进水口温度 "进水口温度";
CM_ SG_ 2566869251 出水口温度 "出水口温度";

BO_ 2566871633 ZT_18FF5A51: 8 Vector__XXX
 SG_ 火灾预警状态 : 16|1@1+ (1,0) [0|0] "" Vector__XXX
 SG_ 温度跳变状态 : 17|1@1+ (1,0) [0|1] "" Vector__XXX
 SG_ 工作状态 : 0|8@1+ (1,0) [0|0] "" Vector__XXX
 SG_ 检测温度值 : 24|8@1+ (1,-40) [-40|125] "deg C" Vector__XXX
 SG_ 烟雾报警器温度 : 48|8@1+ (1,-40) [-40|215] "" Vector__XXX
 SG_ 烟雾报警器周期 : 56|8@1+ (1,0) [0|255] "" Vector__XXX

BA_ "VFrameFormat" BO_ 2566871633 1;
CM_ BO_ 2566871633 "工作状态 / 检测温度值 | 信号数 10";
CM_ SG_ 2566871633 火灾预警状态 "火灾预警状态 [枚举: 未探测到火灾|探测到 火灾]";
VAL_ 2566871633 火灾预警状态 0 "未探测到火灾" 1 "探测到 火灾";
CM_ SG_ 2566871633 温度跳变状态 "温度跳变状态 [枚举: 正常|跳变]";
VAL_ 2566871633 温度跳变状态 0 "正常" 1 "跳变";
CM_ SG_ 2566871633 工作状态 "工作状态 [原始公式: if(((BYTE[0]>>0)&15)==2) 0; else if(((BYTE[0]>>0)&15)==4) 1; else 2] [枚举: 工作正常|报警状态|预留]";
CM_ SG_ 2566871633 检测温度值 "检测温度值";
CM_ SG_ 2566871633 烟雾报警器温度 "烟雾报警器温度";
CM_ SG_ 2566871633 烟雾报警器周期 "烟雾报警器周期";

BO_ 2566871791 ZT_18FF5AEF: 8 Vector__XXX
 SG_ 燃料电池故障状态 : 14|2@1+ (1,0) [0|3] "" Vector__XXX
 SG_ 整车运行模式 : 16|2@1+ (1,0) [0|3] "" Vector__XXX
 SG_ 目标输出功率 : 0|8@1+ (1,0) [0|350] "" Vector__XXX

BA_ "VFrameFormat" BO_ 2566871791 1;
CM_ BO_ 2566871791 "整车运行模式 / 燃料电池开机状态 | 信号数 4";
CM_ SG_ 2566871791 燃料电池故障状态 "燃料电池故障状态 [枚举: 正常|紧急停机|关闭]";
VAL_ 2566871791 燃料电池故障状态 0 "正常" 1 "紧急停机" 2 "关闭";
CM_ SG_ 2566871791 整车运行模式 "整车运行模式 [枚举: 无效|纯电|氢电|保留]";
VAL_ 2566871791 整车运行模式 0 "无效" 1 "纯电" 2 "氢电" 3 "保留";
CM_ SG_ 2566871791 目标输出功率 "目标输出功率 [原始公式: ((BYTE[0]+BYTE[1]*256)&4095)*0.1]";

BO_ 2566877458 ZT_18FF7112: 8 Vector__XXX
 SG_ 燃点电池发动机运行时间（整数位） : 0|16@1+ (1,0) [0|65535] "小时" Vector__XXX
 SG_ 燃料电池发动机运行时间（小数位） : 16|16@1+ (0.0001,0) [0|0.9999] "小时" Vector__XXX

BA_ "VFrameFormat" BO_ 2566877458 1;
CM_ BO_ 2566877458 "燃料电池发动机运行时间（小数位） / 燃点电池发动机运行时间（整数位） | 信号数 2";
CM_ SG_ 2566877458 燃点电池发动机运行时间（整数位） "燃点电池发动机运行时间（整数位）";
CM_ SG_ 2566877458 燃料电池发动机运行时间（小数位） "燃料电池发动机运行时间（小数位）";

BO_ 2566881025 ZT_18FF7F01: 8 Vector__XXX
 SG_ 高压接触器请求命令 : 0|2@1+ (1,0) [0|3] "" Vector__XXX
 SG_ 主接接触器预充 : 2|2@1+ (1,0) [0|3] "" Vector__XXX
 SG_ 辅助继电器闭合 : 4|2@1+ (1,0) [0|3] "" Vector__XXX
 SG_ 辅助预充继电器命令 : 6|2@1+ (1,0) [0|3] "" Vector__XXX
 SG_ DC继电器请求 : 32|2@1+ (1,0) [0|3] "" Vector__XXX
 SG_ 外接DC接触器请求 : 34|2@1+ (1,0) [0|3] "" Vector__XXX
 SG_ FC接触器请求 : 36|2@1+ (1,0) [0|3] "" Vector__XXX
 SG_ PTC接触器请求 : 38|2@1+ (1,0) [0|3] "" Vector__XXX
 SG_ 燃料电池预充接触器命令 : 56|2@1+ (1,0) [0|3] "" Vector__XXX
 SG_ 电机主动放电状态 : 8|8@1+ (1,0) [0|255] "" Vector__XXX
 SG_ 电机母线电压 : 16|16@1+ (1,0) [0|65535] "V" Vector__XXX

BA_ "VFrameFormat" BO_ 2566881025 1;
CM_ BO_ 2566881025 "DC继电器请求 / FC接触器请求 | 信号数 11";
CM_ SG_ 2566881025 高压接触器请求命令 "高压接触器请求命令 [枚举: 断开|闭合]";
VAL_ 2566881025 高压接触器请求命令 0 "断开" 1 "闭合";
CM_ SG_ 2566881025 主接接触器预充 "主接接触器预充 [枚举: 断开|闭合]";
VAL_ 2566881025 主接接触器预充 0 "断开" 1 "闭合";
CM_ SG_ 2566881025 辅助继电器闭合 "辅助继电器闭合 [枚举: 断开|闭合]";
VAL_ 2566881025 辅助继电器闭合 0 "断开" 1 "闭合";
CM_ SG_ 2566881025 辅助预充继电器命令 "辅助预充继电器命令 [枚举: 断开|闭合]";
VAL_ 2566881025 辅助预充继电器命令 0 "断开" 1 "闭合";
CM_ SG_ 2566881025 DC继电器请求 "DC继电器请求 [枚举: 断开|闭合]";
VAL_ 2566881025 DC继电器请求 0 "断开" 1 "闭合";
CM_ SG_ 2566881025 外接DC接触器请求 "外接DC接触器请求 [枚举: 断开|闭合]";
VAL_ 2566881025 外接DC接触器请求 0 "断开" 1 "闭合";
CM_ SG_ 2566881025 FC接触器请求 "FC接触器请求 [枚举: 断开|闭合]";
VAL_ 2566881025 FC接触器请求 0 "断开" 1 "闭合";
CM_ SG_ 2566881025 PTC接触器请求 "PTC接触器请求 [枚举: 断开|闭合]";
VAL_ 2566881025 PTC接触器请求 0 "断开" 1 "闭合";
CM_ SG_ 2566881025 燃料电池预充接触器命令 "燃料电池预充接触器命令 [枚举: 断开|闭合]";
VAL_ 2566881025 燃料电池预充接触器命令 0 "断开" 1 "闭合";
CM_ SG_ 2566881025 电机主动放电状态 "电机主动放电状态 [枚举: 放电完成|主动放电中]";
VAL_ 2566881025 电机主动放电状态 0 "放电完成" 1 "主动放电中";
CM_ SG_ 2566881025 电机母线电压 "电机母线电压";

BO_ 2566881027 ZT_18FF7F03: 8 Vector__XXX
 SG_ 主正接触器状态 : 0|1@1+ (1,0) [0|1] "" Vector__XXX
 SG_ 预充接触器状态 : 1|1@1+ (1,0) [0|1] "" Vector__XXX
 SG_ 充电接触器状态 : 2|1@1+ (1,0) [0|1] "" Vector__XXX
 SG_ 主负接触器状态 : 3|1@1+ (1,0) [0|1] "" Vector__XXX
 SG_ 辅助接触器状态 : 4|1@1+ (1,0) [0|1] "" Vector__XXX
 SG_ 辅助预充接触器状态 : 5|1@1+ (1,0) [0|1] "" Vector__XXX
 SG_ 加热接触器状态-2 : 6|1@1+ (1,0) [0|1] "" Vector__XXX
 SG_ 高压系统自检状态 : 7|1@1+ (1,0) [0|1] "" Vector__XXX
 SG_ 燃料电池主接触器状态 : 56|1@1+ (1,0) [0|1] "" Vector__XXX
 SG_ PTC接触器状态 : 60|1@1+ (1,0) [0|1] "" Vector__XXX
 SG_ 燃料电池预充接触器状态 : 57|1@1+ (1,0) [0|1] "" Vector__XXX
 SG_ HVCM检测电压 : 24|16@1+ (1,0) [0|800] "" Vector__XXX

BA_ "VFrameFormat" BO_ 2566881027 1;
CM_ BO_ 2566881027 "HVCM检测电压 / PTC接触器状态 | 信号数 12";
CM_ SG_ 2566881027 主正接触器状态 "主正接触器状态 [枚举: 断开|闭合]";
VAL_ 2566881027 主正接触器状态 0 "断开" 1 "闭合";
CM_ SG_ 2566881027 预充接触器状态 "预充接触器状态 [枚举: 断开|闭合]";
VAL_ 2566881027 预充接触器状态 0 "断开" 1 "闭合";
CM_ SG_ 2566881027 充电接触器状态 "充电接触器状态 [枚举: 断开|闭合]";
VAL_ 2566881027 充电接触器状态 0 "断开" 1 "闭合";
CM_ SG_ 2566881027 主负接触器状态 "主负接触器状态 [枚举: 断开|闭合]";
VAL_ 2566881027 主负接触器状态 0 "断开" 1 "闭合";
CM_ SG_ 2566881027 辅助接触器状态 "辅助接触器状态 [枚举: 断开|闭合]";
VAL_ 2566881027 辅助接触器状态 0 "断开" 1 "闭合";
CM_ SG_ 2566881027 辅助预充接触器状态 "辅助预充接触器状态 [枚举: 断开|闭合]";
VAL_ 2566881027 辅助预充接触器状态 0 "断开" 1 "闭合";
CM_ SG_ 2566881027 加热接触器状态-2 "加热接触器状态-2 [枚举: 断开|闭合]";
VAL_ 2566881027 加热接触器状态-2 0 "断开" 1 "闭合";
CM_ SG_ 2566881027 高压系统自检状态 "高压系统自检状态 [枚举: 未完成|完成]";
VAL_ 2566881027 高压系统自检状态 0 "未完成" 1 "完成";
CM_ SG_ 2566881027 燃料电池主接触器状态 "燃料电池主接触器状态 [枚举: 断开|闭合]";
VAL_ 2566881027 燃料电池主接触器状态 0 "断开" 1 "闭合";
CM_ SG_ 2566881027 PTC接触器状态 "PTC接触器状态 [枚举: 断开|闭合]";
VAL_ 2566881027 PTC接触器状态 0 "断开" 1 "闭合";
CM_ SG_ 2566881027 燃料电池预充接触器状态 "燃料电池预充接触器状态 [枚举: 断开|闭合]";
VAL_ 2566881027 燃料电池预充接触器状态 0 "断开" 1 "闭合";
CM_ SG_ 2566881027 HVCM检测电压 "HVCM检测电压";

BO_ 2566881298 ZT_18FF8012: 8 Vector__XXX
 SG_ 电堆最小输出电压 : 0|16@1+ (0.1,0) [0|1000] "" Vector__XXX
 SG_ 电堆最小输出电流 : 16|16@1+ (0.1,0) [0|1000] "" Vector__XXX
 SG_ 电堆最大输出电流 : 32|16@1+ (0.1,0) [0|1000] "" Vector__XXX

BA_ "VFrameFormat" BO_ 2566881298 1;
CM_ BO_ 2566881298 "电堆最大输出电流 / 电堆最小输出电压 | 信号数 3";
CM_ SG_ 2566881298 电堆最小输出电压 "电堆最小输出电压";
CM_ SG_ 2566881298 电堆最小输出电流 "电堆最小输出电流";
CM_ SG_ 2566881298 电堆最大输出电流 "电堆最大输出电流";

BO_ 2566882051 ZT_18FF8303: 8 Vector__XXX
 SG_ 剩余充电时间 : 0|16@1+ (1,0) [0|1440] "min" Vector__XXX

BA_ "VFrameFormat" BO_ 2566882051 1;
CM_ BO_ 2566882051 "剩余充电时间 | 信号数 1";
CM_ SG_ 2566882051 剩余充电时间 "剩余充电时间";

BO_ 2566883550 ZT_18FF88DE: 8 Vector__XXX
 SG_ ATS风扇散热系统 : 24|8@1+ (1,-40) [-40|40] "℃" Vector__XXX

BA_ "VFrameFormat" BO_ 2566883550 1;
CM_ BO_ 2566883550 "ATS风扇散热系统 | 信号数 1";
CM_ SG_ 2566883550 ATS风扇散热系统 "ATS风扇散热系统";

BO_ 2566884611 ZT_18FF8D03: 8 Vector__XXX
 SG_ 紧急停机指令 : 0|2@1+ (1,0) [0|3] "" Vector__XXX

BA_ "VFrameFormat" BO_ 2566884611 1;
CM_ BO_ 2566884611 "紧急停机指令 | 信号数 1";
CM_ SG_ 2566884611 紧急停机指令 "紧急停机指令 [枚举: 无效|有效]";
VAL_ 2566884611 紧急停机指令 0 "无效" 1 "有效";

BO_ 2566885619 ZT_18FF90F3: 8 Vector__XXX
 SG_ 最高单体电压所在系统编号 : 56|2@1+ (1,0) [0|3] "" Vector__XXX
 SG_ 最低单体电压所在系统编号 : 58|2@1+ (1,0) [0|3] "" Vector__XXX
 SG_ 最高单体温度所在系统编号 : 60|2@1+ (1,0) [0|3] "" Vector__XXX
 SG_ 最低单体温度所在系统编号 : 62|2@1+ (1,0) [0|3] "" Vector__XXX
 SG_ 可充电储能系统个数 : 0|8@1+ (1,0) [0|255] "" Vector__XXX
 SG_ 可充电储能系统1温度采样点个数 : 24|8@1+ (1,0) [0|250] "" Vector__XXX
 SG_ 可充电储能系统2温度采样点个数 : 48|8@1+ (1,0) [0|255] "" Vector__XXX
 SG_ 可充电储能系统1电压采样点个数 : 8|16@1+ (1,0) [0|65535] "" Vector__XXX
 SG_ 可充电储能系统2电压采样点个数 : 32|16@1+ (1,0) [0|62235] "" Vector__XXX

BA_ "VFrameFormat" BO_ 2566885619 1;
CM_ BO_ 2566885619 "可充电储能系统1温度采样点个数 / 可充电储能系统1温度采样点个数-1 | 信号数 56";
CM_ SG_ 2566885619 最高单体电压所在系统编号 "最高单体电压所在系统编号";
CM_ SG_ 2566885619 最低单体电压所在系统编号 "最低单体电压所在系统编号";
CM_ SG_ 2566885619 最高单体温度所在系统编号 "最高单体温度所在系统编号";
CM_ SG_ 2566885619 最低单体温度所在系统编号 "最低单体温度所在系统编号";
CM_ SG_ 2566885619 可充电储能系统个数 "可充电储能系统个数";
CM_ SG_ 2566885619 可充电储能系统1温度采样点个数 "可充电储能系统1温度采样点个数";
CM_ SG_ 2566885619 可充电储能系统2温度采样点个数 "可充电储能系统2温度采样点个数";
CM_ SG_ 2566885619 可充电储能系统1电压采样点个数 "可充电储能系统1电压采样点个数";
CM_ SG_ 2566885619 可充电储能系统2电压采样点个数 "可充电储能系统2电压采样点个数";

BO_ 2566885875 ZT_18FF91F3: 8 Vector__XXX
 SG_ 唤醒状态 : 56|2@1+ (1,0) [0|3] "" Vector__XXX
 SG_ 车辆充电状态 : 0|8@1+ (1,0) [0|4] "" Vector__XXX
 SG_ 1充电口DC+温度 : 8|8@1+ (1,-50) [-50|200] "V" Vector__XXX
 SG_ 1充电口DC-温度 : 16|8@1+ (1,-50) [-50|200] "V" Vector__XXX
 SG_ 2充电口DC+温度 : 24|8@1+ (1,-50) [-50|205] "V" Vector__XXX
 SG_ 2充电口DC-温度 : 32|8@1+ (1,-50) [-50|205] "V" Vector__XXX
 SG_ 剩余充电时间 : 40|16@1+ (0.1,0) [0|600] "min" Vector__XXX

BA_ "VFrameFormat" BO_ 2566885875 1;
CM_ BO_ 2566885875 "1充电口DC+温度 / 1充电口DC-温度 | 信号数 38";
CM_ SG_ 2566885875 唤醒状态 "唤醒状态 [枚举: 无唤醒|行车唤醒|充电唤醒|自唤醒]";
VAL_ 2566885875 唤醒状态 0 "无唤醒" 1 "行车唤醒" 2 "充电唤醒" 3 "自唤醒";
CM_ SG_ 2566885875 车辆充电状态 "车辆充电状态 [原始公式: if((BYTE[0])==1) 0; else if((BYTE[0])==2) 1; else if((BYTE[0])==3) 2; else if((BYTE[0])==4) 3; else if((BYTE[0])==254) 4; else if((BYTE[0])==255) 5; else 6] [枚举: 停车充电|行驶充电|未充电状态|充电完成|异常|无效|预留]";
CM_ SG_ 2566885875 1充电口DC+温度 "1充电口DC+温度";
CM_ SG_ 2566885875 1充电口DC-温度 "1充电口DC-温度";
CM_ SG_ 2566885875 2充电口DC+温度 "2充电口DC+温度";
CM_ SG_ 2566885875 2充电口DC-温度 "2充电口DC-温度";
CM_ SG_ 2566885875 剩余充电时间 "剩余充电时间";

BO_ 2566886131 ZT_18FF92F3: 8 Vector__XXX
 SG_ 温度差异报警状态 : 16|1@1+ (1,0) [0|1] "" Vector__XXX
 SG_ 电池高温报警状态 : 17|1@1+ (1,0) [0|1] "" Vector__XXX
 SG_ 车载储能装置类型过压报警状态 : 18|1@1+ (1,0) [0|1] "" Vector__XXX
 SG_ 车载储能装置类型欠压报警状态 : 19|1@1+ (1,0) [0|1] "" Vector__XXX
 SG_ 电量过低报警状态 : 20|1@1+ (1,0) [0|1] "" Vector__XXX
 SG_ 单体电池过压报警状态 : 21|1@1+ (1,0) [0|1] "" Vector__XXX
 SG_ 单体电池欠压报警 状态 : 22|1@1+ (1,0) [0|1] "" Vector__XXX
 SG_ SOC过高报警状态 : 23|1@1+ (1,0) [0|1] "" Vector__XXX
 SG_ SOC跳变报警状态 : 24|1@1+ (1,0) [0|1] "" Vector__XXX
 SG_ 可充电储能系统不匹配报警状态 : 25|1@1+ (1,0) [0|1] "" Vector__XXX
 SG_ 电池单体一致性差报警状态 : 26|1@1+ (1,0) [0|1] "" Vector__XXX
 SG_ 绝缘报警状态 : 27|1@1+ (1,0) [0|1] "" Vector__XXX
 SG_ 车载储能装置类型过充状态 : 28|1@1+ (1,0) [0|1] "" Vector__XXX
 SG_ 故障等级-2 : 0|8@1+ (1,0) [0|255] "" Vector__XXX
 SG_ 故障总数 : 8|8@1+ (1,0) [0|255] "" Vector__XXX

BA_ "VFrameFormat" BO_ 2566886131 1;
CM_ BO_ 2566886131 "SOC低报警 / SOC跳变报警 | 信号数 86";
CM_ SG_ 2566886131 温度差异报警状态 "温度差异报警状态 [枚举: 无故障|有故障]";
VAL_ 2566886131 温度差异报警状态 0 "无故障" 1 "有故障";
CM_ SG_ 2566886131 电池高温报警状态 "电池高温报警状态 [枚举: 无故障|有故障]";
VAL_ 2566886131 电池高温报警状态 0 "无故障" 1 "有故障";
CM_ SG_ 2566886131 车载储能装置类型过压报警状态 "车载储能装置类型过压报警状态 [枚举: 无故障|有故障]";
VAL_ 2566886131 车载储能装置类型过压报警状态 0 "无故障" 1 "有故障";
CM_ SG_ 2566886131 车载储能装置类型欠压报警状态 "车载储能装置类型欠压报警状态 [枚举: 无故障|有故障]";
VAL_ 2566886131 车载储能装置类型欠压报警状态 0 "无故障" 1 "有故障";
CM_ SG_ 2566886131 电量过低报警状态 "电量过低报警状态 [枚举: 无故障|有故障]";
VAL_ 2566886131 电量过低报警状态 0 "无故障" 1 "有故障";
CM_ SG_ 2566886131 单体电池过压报警状态 "单体电池过压报警状态 [枚举: 无故障|有故障]";
VAL_ 2566886131 单体电池过压报警状态 0 "无故障" 1 "有故障";
CM_ SG_ 2566886131 单体电池欠压报警 状态 "单体电池欠压报警 状态 [枚举: 无故障|有故障]";
VAL_ 2566886131 单体电池欠压报警 状态 0 "无故障" 1 "有故障";
CM_ SG_ 2566886131 SOC过高报警状态 "SOC过高报警状态 [枚举: 无故障|有故障]";
VAL_ 2566886131 SOC过高报警状态 0 "无故障" 1 "有故障";
CM_ SG_ 2566886131 SOC跳变报警状态 "SOC跳变报警状态 [枚举: 无故障|有故障]";
VAL_ 2566886131 SOC跳变报警状态 0 "无故障" 1 "有故障";
CM_ SG_ 2566886131 可充电储能系统不匹配报警状态 "可充电储能系统不匹配报警状态 [枚举: 无故障|有故障]";
VAL_ 2566886131 可充电储能系统不匹配报警状态 0 "无故障" 1 "有故障";
CM_ SG_ 2566886131 电池单体一致性差报警状态 "电池单体一致性差报警状态 [枚举: 无故障|有故障]";
VAL_ 2566886131 电池单体一致性差报警状态 0 "无故障" 1 "有故障";
CM_ SG_ 2566886131 绝缘报警状态 "绝缘报警状态 [枚举: 无故障|有故障]";
VAL_ 2566886131 绝缘报警状态 0 "无故障" 1 "有故障";
CM_ SG_ 2566886131 车载储能装置类型过充状态 "车载储能装置类型过充状态 [枚举: 无故障|有故障]";
VAL_ 2566886131 车载储能装置类型过充状态 0 "无故障" 1 "有故障";
CM_ SG_ 2566886131 故障等级-2 "故障等级-2 [枚举: 无故障|一级故障|二级故障|三级故障]";
VAL_ 2566886131 故障等级-2 0 "无故障" 1 "一级故障" 2 "二级故障" 3 "三级故障";
CM_ SG_ 2566886131 故障总数 "故障总数";

BO_ 2566889972 ZT_18FFA1F4: 8 Vector__XXX
 SG_ 氢控制器主阀 : 8|2@1+ (1,0) [0|3] "" Vector__XXX
 SG_ 氢控制器瓶阀 : 10|2@1+ (1,0) [0|3] "" Vector__XXX
 SG_ 故障等级-1 : 4|4@1+ (1,0) [0|15] "" Vector__XXX
 SG_ 封装氢气浓度 : 16|8@1+ (200,0) [0|50000] "ppm" Vector__XXX
 SG_ 燃料电池输出功率 : 56|8@1+ (1,0) [0|250] "kw" Vector__XXX
 SG_ 电堆入口氢气压力 : 24|16@1+ (1,0) [0|65000] "kpa" Vector__XXX
 SG_ 电堆入口空气压力 : 40|16@1+ (1,0) [0|65000] "kpa" Vector__XXX

BA_ "VFrameFormat" BO_ 2566889972 1;
CM_ BO_ 2566889972 "封装氢气浓度 / 故障等级-1 | 信号数 8";
CM_ SG_ 2566889972 氢控制器主阀 "氢控制器主阀 [枚举: 关闭|打开]";
VAL_ 2566889972 氢控制器主阀 0 "关闭" 1 "打开";
CM_ SG_ 2566889972 氢控制器瓶阀 "氢控制器瓶阀 [枚举: 关闭|打开]";
VAL_ 2566889972 氢控制器瓶阀 0 "关闭" 1 "打开";
CM_ SG_ 2566889972 故障等级-1 "故障等级-1 [枚举: 无故障|轻微故障|警告故障|一般故障（降载）|严重故障(停机）]";
VAL_ 2566889972 故障等级-1 0 "无故障" 1 "轻微故障" 2 "警告故障" 3 "一般故障（降载）" 4 "严重故障(停机）";
CM_ SG_ 2566889972 封装氢气浓度 "封装氢气浓度";
CM_ SG_ 2566889972 燃料电池输出功率 "燃料电池输出功率";
CM_ SG_ 2566889972 电堆入口氢气压力 "电堆入口氢气压力";
CM_ SG_ 2566889972 电堆入口空气压力 "电堆入口空气压力";

BO_ 2566889973 ZT_18FFA1F5: 8 Vector__XXX
 SG_ 瓶阀状态1 : 24|1@1+ (1,0) [0|1] "" Vector__XXX
 SG_ 瓶阀状态2 : 25|1@1+ (1,0) [0|1] "" Vector__XXX
 SG_ 瓶阀状态3 : 26|1@1+ (1,0) [0|1] "" Vector__XXX
 SG_ 瓶阀状态4 : 27|1@1+ (1,0) [0|1] "" Vector__XXX
 SG_ 瓶阀状态6 : 29|1@1+ (1,0) [0|1] "" Vector__XXX
 SG_ 瓶阀状态7 : 30|1@1+ (1,0) [0|1] "" Vector__XXX
 SG_ 瓶阀状态8 : 31|1@1+ (1,0) [0|1] "" Vector__XXX
 SG_ 氢系统断整车高压请求 : 6|2@1+ (1,0) [0|3] "" Vector__XXX
 SG_ 主阀状态 : 16|2@1+ (1,0) [0|3] "" Vector__XXX
 SG_ 瓶阀供电 : 18|2@1+ (1,0) [0|3] "" Vector__XXX
 SG_ 氢系统状态 : 0|3@1+ (1,0) [0|350] "" Vector__XXX
 SG_ 氢系统故障等级 : 3|3@1+ (1,0) [0|7] "" Vector__XXX
 SG_ 瓶阀状态5 : 28|1@1+ (1,0) [0|1] "" Vector__XXX
 SG_ 氢气余量 : 8|8@1+ (0.4,0) [0|102] "%" Vector__XXX

BA_ "VFrameFormat" BO_ 2566889973 1;
CM_ BO_ 2566889973 "主阀状态 / 氢气余量 | 信号数 14";
CM_ SG_ 2566889973 瓶阀状态1 "瓶阀状态1 [枚举: 阀关|阀开]";
VAL_ 2566889973 瓶阀状态1 0 "阀关" 1 "阀开";
CM_ SG_ 2566889973 瓶阀状态2 "瓶阀状态2 [枚举: 阀关|阀开]";
VAL_ 2566889973 瓶阀状态2 0 "阀关" 1 "阀开";
CM_ SG_ 2566889973 瓶阀状态3 "瓶阀状态3 [枚举: 阀关|阀开]";
VAL_ 2566889973 瓶阀状态3 0 "阀关" 1 "阀开";
CM_ SG_ 2566889973 瓶阀状态4 "瓶阀状态4 [枚举: 阀关|阀开]";
VAL_ 2566889973 瓶阀状态4 0 "阀关" 1 "阀开";
CM_ SG_ 2566889973 瓶阀状态6 "瓶阀状态6 [枚举: 阀关|阀开]";
VAL_ 2566889973 瓶阀状态6 0 "阀关" 1 "阀开";
CM_ SG_ 2566889973 瓶阀状态7 "瓶阀状态7 [枚举: 阀关|阀开]";
VAL_ 2566889973 瓶阀状态7 0 "阀关" 1 "阀开";
CM_ SG_ 2566889973 瓶阀状态8 "瓶阀状态8 [枚举: 阀关|阀开]";
VAL_ 2566889973 瓶阀状态8 0 "阀关" 1 "阀开";
CM_ SG_ 2566889973 氢系统断整车高压请求 "氢系统断整车高压请求 [枚举: 无请求|强制断高压请求(FCU急停,VCU断高压)]";
VAL_ 2566889973 氢系统断整车高压请求 0 "无请求" 1 "强制断高压请求(FCU急停,VCU断高压)";
CM_ SG_ 2566889973 主阀状态 "主阀状态 [枚举: 阀关|阀开]";
VAL_ 2566889973 主阀状态 0 "阀关" 1 "阀开";
CM_ SG_ 2566889973 瓶阀供电 "瓶阀供电 [枚举: 未供电|供电]";
VAL_ 2566889973 瓶阀供电 0 "未供电" 1 "供电";
CM_ SG_ 2566889973 氢系统状态 "氢系统状态 [枚举: 开机上电|待机状态|工作状态]";
VAL_ 2566889973 氢系统状态 0 "开机上电" 1 "待机状态" 2 "工作状态";
CM_ SG_ 2566889973 氢系统故障等级 "氢系统故障等级 [枚举: 无故障|1级故障|2级故障（轻微）|3级故障（次严重）|4级故障（最严重）]";
VAL_ 2566889973 氢系统故障等级 0 "无故障" 1 "1级故障" 2 "2级故障（轻微）" 3 "3级故障（次严重）" 4 "4级故障（最严重）";
CM_ SG_ 2566889973 瓶阀状态5 "瓶阀状态5";
CM_ SG_ 2566889973 氢气余量 "氢气余量";

BO_ 2566890228 ZT_18FFA2F4: 8 Vector__XXX
 SG_ 工作使能信号 : 0|2@1+ (1,0) [0|3] "" Vector__XXX
 SG_ 输入电流设定 : 8|16@1+ (1,0.1) [0|1000] "A" Vector__XXX

BA_ "VFrameFormat" BO_ 2566890228 1;
CM_ BO_ 2566890228 "工作使能信号 / 输入电流设定 | 信号数 2";
CM_ SG_ 2566890228 工作使能信号 "工作使能信号 [枚举: 关闭|打开]";
VAL_ 2566890228 工作使能信号 0 "关闭" 1 "打开";
CM_ SG_ 2566890228 输入电流设定 "输入电流设定";

BO_ 2566890229 ZT_18FFA2F5: 8 Vector__XXX
 SG_ 氢气最高压力传感器代号 : 16|8@1+ (1,0) [0|252] "" Vector__XXX
 SG_ 氢气压力-高压1 : 24|8@1+ (0.5,0) [0|125] "Mpa" Vector__XXX
 SG_ 氢气压力-高压2 : 32|8@1+ (0.5,0) [0|125] "Mpa" Vector__XXX
 SG_ 氢气压力-低压1 : 40|8@1+ (0.05,0) [0|12.5] "Mpa" Vector__XXX
 SG_ 氢气最高压力 : 0|16@1+ (0.1,0) [0|1000] "Mpa" Vector__XXX

BA_ "VFrameFormat" BO_ 2566890229 1;
CM_ BO_ 2566890229 "氢气压力-低压1 / 氢气压力-高压1 | 信号数 5";
CM_ SG_ 2566890229 氢气最高压力传感器代号 "氢气最高压力传感器代号";
CM_ SG_ 2566890229 氢气压力-高压1 "氢气压力-高压1";
CM_ SG_ 2566890229 氢气压力-高压2 "氢气压力-高压2";
CM_ SG_ 2566890229 氢气压力-低压1 "氢气压力-低压1";
CM_ SG_ 2566890229 氢气最高压力 "氢气最高压力";

BO_ 2566890484 ZT_18FFA3F4: 8 Vector__XXX
 SG_ 故障等级-2 : 4|4@1+ (1,0) [0|15] "" Vector__XXX
 SG_ 工作温度 : 56|8@1+ (1,-40) [-40|200] "℃" Vector__XXX
 SG_ 输出电流 : 8|16@1+ (0.1,0) [0|1000] "A" Vector__XXX
 SG_ 输出电压 : 24|16@1+ (0.1,0) [0|1000] "V" Vector__XXX
 SG_ 输出功率 : 40|16@1+ (0.1,0) [0|350] "KW" Vector__XXX

BA_ "VFrameFormat" BO_ 2566890484 1;
CM_ BO_ 2566890484 "工作温度 / 工作状态 | 信号数 6";
CM_ SG_ 2566890484 故障等级-2 "故障等级-2 [枚举: 无故障|轻微故障|警告故障|一般故障（降载）|严重故障（关机）]";
VAL_ 2566890484 故障等级-2 0 "无故障" 1 "轻微故障" 2 "警告故障" 3 "一般故障（降载）" 4 "严重故障（关机）";
CM_ SG_ 2566890484 工作温度 "工作温度";
CM_ SG_ 2566890484 输出电流 "输出电流";
CM_ SG_ 2566890484 输出电压 "输出电压";
CM_ SG_ 2566890484 输出功率 "输出功率";

BO_ 2566890485 ZT_18FFA3F5: 8 Vector__XXX
 SG_ 氢系统中最高温度探针代号 : 16|8@1+ (1,0) [0|252] "0" Vector__XXX
 SG_ 氢瓶温度1 : 24|8@1+ (1,0) [-40|200] "℃" Vector__XXX
 SG_ 氢瓶温度2 : 32|8@1+ (1,0) [-40|200] "℃" Vector__XXX
 SG_ 氢瓶温度3 : 40|8@1+ (1,0) [-40|200] "℃" Vector__XXX
 SG_ 氢瓶温度4 : 48|8@1+ (1,0) [-40|200] "℃" Vector__XXX
 SG_ 氢瓶温度5 : 56|8@1+ (1,0) [-40|200] "℃" Vector__XXX
 SG_ 氢系统中最高温度 : 0|16@1+ (0.1,0) [-40|200] "℃" Vector__XXX

BA_ "VFrameFormat" BO_ 2566890485 1;
CM_ BO_ 2566890485 "氢瓶温度1 / 氢瓶温度2 | 信号数 7";
CM_ SG_ 2566890485 氢系统中最高温度探针代号 "氢系统中最高温度探针代号";
CM_ SG_ 2566890485 氢瓶温度1 "氢瓶温度1";
CM_ SG_ 2566890485 氢瓶温度2 "氢瓶温度2";
CM_ SG_ 2566890485 氢瓶温度3 "氢瓶温度3";
CM_ SG_ 2566890485 氢瓶温度4 "氢瓶温度4";
CM_ SG_ 2566890485 氢瓶温度5 "氢瓶温度5";
CM_ SG_ 2566890485 氢系统中最高温度 "氢系统中最高温度";

BO_ 2566890740 ZT_18FFA4F4: 8 Vector__XXX
 SG_ 电堆输出电流 : 0|16@1+ (0.1,0) [0|2000] "A" Vector__XXX
 SG_ 电堆输出电压 : 16|16@1+ (0.1,0) [0|2000] "V" Vector__XXX
 SG_ 电堆输出功率 : 32|16@1+ (0.1,0) [0|350] "KW" Vector__XXX
 SG_ 燃料消耗率 : 48|16@1+ (0.001,0) [0|60] "g/s" Vector__XXX

BA_ "VFrameFormat" BO_ 2566890740 1;
CM_ BO_ 2566890740 "燃料消耗率 / 电堆输出功率 | 信号数 4";
CM_ SG_ 2566890740 电堆输出电流 "电堆输出电流";
CM_ SG_ 2566890740 电堆输出电压 "电堆输出电压";
CM_ SG_ 2566890740 电堆输出功率 "电堆输出功率";
CM_ SG_ 2566890740 燃料消耗率 "燃料消耗率";

BO_ 2566890741 ZT_18FFA4F5: 8 Vector__XXX
 SG_ 氢瓶温度6 : 0|8@1+ (1,0) [-40|200] "℃" Vector__XXX
 SG_ 氢瓶温度7 : 8|8@1+ (1,0) [-40|200] "℃" Vector__XXX
 SG_ 氢瓶温度8 : 16|8@1+ (1,0) [-40|200] "℃" Vector__XXX
 SG_ 氢瓶温度9 : 24|8@1+ (1,0) [255|255] "℃" Vector__XXX
 SG_ 氢瓶温度10 : 32|8@1+ (1,0) [255|255] "℃" Vector__XXX
 SG_ 氢瓶温度11 : 40|8@1+ (1,0) [255|255] "℃" Vector__XXX
 SG_ 氢瓶温度12 : 48|8@1+ (1,0) [255|255] "℃" Vector__XXX

BA_ "VFrameFormat" BO_ 2566890741 1;
CM_ BO_ 2566890741 "氢瓶温度10 / 氢瓶温度11 | 信号数 7";
CM_ SG_ 2566890741 氢瓶温度6 "氢瓶温度6";
CM_ SG_ 2566890741 氢瓶温度7 "氢瓶温度7";
CM_ SG_ 2566890741 氢瓶温度8 "氢瓶温度8";
CM_ SG_ 2566890741 氢瓶温度9 "氢瓶温度9 [原始公式: if((BYTE[3])==255) @1; else BYTE[3]] [枚举: %d|未启用]";
CM_ SG_ 2566890741 氢瓶温度10 "氢瓶温度10 [原始公式: if((BYTE[4])==255) @1; else BYTE[4]] [枚举: %d|未启用]";
CM_ SG_ 2566890741 氢瓶温度11 "氢瓶温度11 [原始公式: if((BYTE[5])==255) @1; else BYTE[5]] [枚举: %d|未启用]";
CM_ SG_ 2566890741 氢瓶温度12 "氢瓶温度12 [原始公式: if((BYTE[6])==255) @1; else BYTE[6]] [枚举: %d|未启用]";

BO_ 2566890996 ZT_18FFA5F4: 8 Vector__XXX
 SG_ 燃料电池温度1（电堆水路入口温度） : 16|8@1+ (1,0) [-40|200] "℃" Vector__XXX
 SG_ 燃料电池温度2（电堆水路出口温度） : 24|8@1+ (1,0) [-40|200] "℃" Vector__XXX
 SG_ 燃料电池温度3（电堆空气入口） : 32|8@1+ (1,0) [-40|200] "℃" Vector__XXX
 SG_ 燃料电池温度4 : 40|8@1+ (1,0) [-40|200] "℃" Vector__XXX
 SG_ 燃料电池温度5 : 48|8@1+ (1,0) [-40|200] "℃" Vector__XXX
 SG_ 燃料电池温度6 : 56|8@1+ (1,0) [-40|200] "℃" Vector__XXX
 SG_ 燃料堆温度探针总数 : 0|16@1+ (1,0) [0|65531] "" Vector__XXX

BA_ "VFrameFormat" BO_ 2566890996 1;
CM_ BO_ 2566890996 "燃料堆温度探针总数 / 燃料电池温度1（电堆水路入口温度） | 信号数 7";
CM_ SG_ 2566890996 燃料电池温度1（电堆水路入口温度） "燃料电池温度1（电堆水路入口温度）";
CM_ SG_ 2566890996 燃料电池温度2（电堆水路出口温度） "燃料电池温度2（电堆水路出口温度）";
CM_ SG_ 2566890996 燃料电池温度3（电堆空气入口） "燃料电池温度3（电堆空气入口）";
CM_ SG_ 2566890996 燃料电池温度4 "燃料电池温度4";
CM_ SG_ 2566890996 燃料电池温度5 "燃料电池温度5";
CM_ SG_ 2566890996 燃料电池温度6 "燃料电池温度6";
CM_ SG_ 2566890996 燃料堆温度探针总数 "燃料堆温度探针总数";

BO_ 2566890997 ZT_18FFA5F5: 8 Vector__XXX
 SG_ 氢气最高浓度传感器代号 : 16|8@1+ (1,0) [0|252] "0" Vector__XXX
 SG_ 氢瓶浓度1（氢瓶总阀） : 24|8@1+ (200,0) [0|60000] "mg/kg" Vector__XXX
 SG_ 氢瓶浓度2（燃料电池系统） : 32|8@1+ (200,0) [0|60000] "mg/kg" Vector__XXX
 SG_ 氢瓶浓度3（加氢口） : 40|8@1+ (200,0) [0|60000] "mg/kg" Vector__XXX
 SG_ 氢瓶浓度4（乘客区） : 48|8@1+ (200,0) [0|60000] "mg/kg" Vector__XXX
 SG_ 氢瓶浓度5 : 56|8@1+ (200,0) [0|60000] "mg/kg" Vector__XXX
 SG_ 氢气最高浓度 : 0|16@1+ (1,0) [0|60000] "mg/kg" Vector__XXX

BA_ "VFrameFormat" BO_ 2566890997 1;
CM_ BO_ 2566890997 "氢气最高浓度 / 氢气最高浓度传感器代号 | 信号数 7";
CM_ SG_ 2566890997 氢气最高浓度传感器代号 "氢气最高浓度传感器代号";
CM_ SG_ 2566890997 氢瓶浓度1（氢瓶总阀） "氢瓶浓度1（氢瓶总阀）";
CM_ SG_ 2566890997 氢瓶浓度2（燃料电池系统） "氢瓶浓度2（燃料电池系统）";
CM_ SG_ 2566890997 氢瓶浓度3（加氢口） "氢瓶浓度3（加氢口）";
CM_ SG_ 2566890997 氢瓶浓度4（乘客区） "氢瓶浓度4（乘客区）";
CM_ SG_ 2566890997 氢瓶浓度5 "氢瓶浓度5";
CM_ SG_ 2566890997 氢气最高浓度 "氢气最高浓度";

BO_ 2566891252 ZT_18FFA6F4: 8 Vector__XXX
 SG_ 散热风扇状态 : 56|2@1+ (1,0) [0|3] "" Vector__XXX
 SG_ 散热风扇总数 : 58|3@1+ (1,0) [1|8] "" Vector__XXX
 SG_ 散热风扇正在工作的个数 : 61|3@1+ (1,0) [-40|200] "℃" Vector__XXX
 SG_ 循环泵转速 : 48|8@1+ (40,0) [-40|10200] "rpm" Vector__XXX
 SG_ 空气入口流量 : 0|16@1+ (1,0) [0|60000] "LPM" Vector__XXX
 SG_ 冷却水入口压力 : 16|16@1+ (0.01,0) [-100|500] "kpa" Vector__XXX
 SG_ 水泵转速 : 32|16@1+ (0.5,0) [0|10000] "rpm" Vector__XXX

BA_ "VFrameFormat" BO_ 2566891252 1;
CM_ BO_ 2566891252 "冷却水入口压力 / 循环泵转速 | 信号数 7";
CM_ SG_ 2566891252 散热风扇状态 "散热风扇状态 [枚举: 风扇不工作|风扇正在工作|风扇异常]";
VAL_ 2566891252 散热风扇状态 0 "风扇不工作" 1 "风扇正在工作" 2 "风扇异常";
CM_ SG_ 2566891252 散热风扇总数 "散热风扇总数";
CM_ SG_ 2566891252 散热风扇正在工作的个数 "散热风扇正在工作的个数";
CM_ SG_ 2566891252 循环泵转速 "循环泵转速";
CM_ SG_ 2566891252 空气入口流量 "空气入口流量";
CM_ SG_ 2566891252 冷却水入口压力 "冷却水入口压力";
CM_ SG_ 2566891252 水泵转速 "水泵转速";

BO_ 2566891253 ZT_18FFA6F5: 8 Vector__XXX
 SG_ 氢气剩余量 : 0|16@1+ (0.01,0) [0|655.35] "kg" Vector__XXX
 SG_ 单次耗氢量 : 16|16@1+ (0.01,0) [0|655.35] "0" Vector__XXX
 SG_ 累计耗氢量 : 32|32@1+ (0.01,0) [0|42949627.95] "mg/kg" Vector__XXX

BA_ "VFrameFormat" BO_ 2566891253 1;
CM_ BO_ 2566891253 "单次耗氢量 / 氢气剩余量 | 信号数 3";
CM_ SG_ 2566891253 氢气剩余量 "氢气剩余量";
CM_ SG_ 2566891253 单次耗氢量 "单次耗氢量";
CM_ SG_ 2566891253 累计耗氢量 "累计耗氢量";

BO_ 2566891508 ZT_18FFA7F4: 8 Vector__XXX
 SG_ 燃料电池累计运行时间（分） : 40|6@1+ (1,0) [0|60] "min" Vector__XXX
 SG_ 高压PTC功率 : 16|8@1+ (0.1,0) [0|25] "kw" Vector__XXX
 SG_ 空压机转速 : 0|16@1+ (2,0) [0|120000] "rpm" Vector__XXX
 SG_ 燃料电池累计运行时间（时） : 24|16@1+ (1,0) [0|60000] "h" Vector__XXX

BA_ "VFrameFormat" BO_ 2566891508 1;
CM_ BO_ 2566891508 "燃料电池累计运行时间（分） / 燃料电池累计运行时间（时） | 信号数 4";
CM_ SG_ 2566891508 燃料电池累计运行时间（分） "燃料电池累计运行时间（分）";
CM_ SG_ 2566891508 高压PTC功率 "高压PTC功率";
CM_ SG_ 2566891508 空压机转速 "空压机转速";
CM_ SG_ 2566891508 燃料电池累计运行时间（时） "燃料电池累计运行时间（时）";

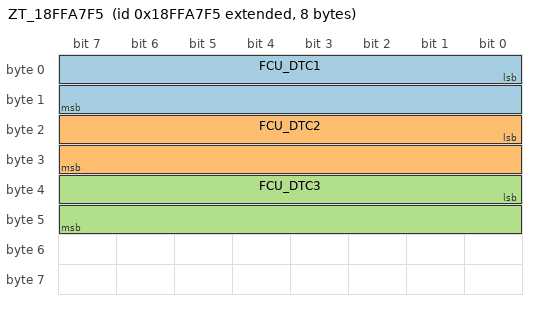
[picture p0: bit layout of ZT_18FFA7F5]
BO_ 2566891509 ZT_18FFA7F5: 8 Vector__XXX
 SG_ FCU_DTC1 : 0|16@1+ (1,0) [0|65535] "" Vector__XXX
 SG_ FCU_DTC2 : 16|16@1+ (1,0) [0|65535] "" Vector__XXX
 SG_ FCU_DTC3 : 32|16@1+ (1,0) [0|65535] "" Vector__XXX

BA_ "VFrameFormat" BO_ 2566891509 1;
CM_ BO_ 2566891509 "FCU_DTC1 / FCU_DTC2 | 信号数 4";
CM_ SG_ 2566891509 FCU_DTC1 "FCU_DTC1 [枚举: 无故障|有故障]";
CM_ SG_ 2566891509 FCU_DTC2 "FCU_DTC2 [枚举: 无故障|有故障]";
CM_ SG_ 2566891509 FCU_DTC3 "FCU_DTC3 [枚举: 无故障|有故障]";

BO_ 2566891764 ZT_18FFA8F4: 8 Vector__XXX
 SG_ 燃料电池DTC1 : 0|16@1+ (1,0) [0|65535] "" Vector__XXX
 SG_ 燃料电池DTC2 : 16|16@1+ (1,0) [0|65535] "" Vector__XXX
 SG_ 燃料电池DTC3 : 32|16@1+ (1,0) [0|65535] "" Vector__XXX

BA_ "VFrameFormat" BO_ 2566891764 1;
CM_ BO_ 2566891764 "燃料电池DTC1 / 燃料电池DTC2 | 信号数 4";
CM_ SG_ 2566891764 燃料电池DTC1 "燃料电池DTC1 [枚举: 无故障|有故障]";
CM_ SG_ 2566891764 燃料电池DTC2 "燃料电池DTC2 [枚举: 无故障|有故障]";
CM_ SG_ 2566891764 燃料电池DTC3 "燃料电池DTC3 [枚举: 无故障|有故障]";

BO_ 2566897978 ZT_18FFC13A: 8 Vector__XXX
 SG_ TMS工作模式 : 0|2@1+ (1,0) [0|0] "" Vector__XXX
 SG_ TMS空调的主接触器 状态 : 2|2@1+ (1,0) [0|0] "" Vector__XXX
 SG_ TMS故障等级 : 62|2@1+ (1,0) [0|3] "" Vector__XXX
 SG_ TMS故障码 : 56|6@1+ (1,0) [0|63] "" Vector__XXX
 SG_ 机组出水温度 : 8|8@1+ (1,-40) [-40|215] "deg C" Vector__XXX
 SG_ 机组进水温度 : 16|8@1+ (1,-40) [-40|215] "deg C" Vector__XXX
 SG_ 压缩机负载比率 : 32|8@1+ (1,0) [0|100] "%" Vector__XXX
 SG_ TMS实时功率 : 40|16@1+ (0.001,0) [0|100] "%" Vector__XXX

BA_ "VFrameFormat" BO_ 2566897978 1;
CM_ BO_ 2566897978 "TMS实时功率 / TMS工作模式 | 信号数 18";
CM_ SG_ 2566897978 TMS工作模式 "TMS工作模式 [枚举: 待机模式|制冷模式|制热模式|自循环模式]";
VAL_ 2566897978 TMS工作模式 0 "待机模式" 1 "制冷模式" 2 "制热模式" 3 "自循环模式";
CM_ SG_ 2566897978 TMS空调的主接触器 状态 "TMS空调的主接触器 状态 [枚举: 断开|闭合]";
VAL_ 2566897978 TMS空调的主接触器 状态 0 "断开" 1 "闭合";
CM_ SG_ 2566897978 TMS故障等级 "TMS故障等级 [枚举: 无故障（仪表绿灯显示机组正常）|1级故障（仪表红灯显示机组异常）|2级故障（仪表红灯显示机组异常）|3级故障（仪表红灯显示机组异常）]";
VAL_ 2566897978 TMS故障等级 0 "无故障（仪表绿灯显示机组正常）" 1 "1级故障（仪表红灯显示机组异常）" 2 "2级故障（仪表红灯显示机组异常）" 3 "3级故障（仪表红灯显示机组异常）";
CM_ SG_ 2566897978 TMS故障码 "TMS故障码";
CM_ SG_ 2566897978 机组出水温度 "机组出水温度";
CM_ SG_ 2566897978 机组进水温度 "机组进水温度";
CM_ SG_ 2566897978 压缩机负载比率 "压缩机负载比率";
CM_ SG_ 2566897978 TMS实时功率 "TMS实时功率";

BO_ 2566898201 ZT_18FFC219: 8 Vector__XXX
 SG_ 新风模式 : 0|2@1+ (1,0) [0|0] "" Vector__XXX
 SG_ 制热模式 : 2|2@1+ (1,0) [0|0] "" Vector__XXX
 SG_ 制冷模式 : 4|2@1+ (1,0) [0|0] "" Vector__XXX
 SG_ 空调开关状态 : 6|2@1+ (1,0) [0|0] "" Vector__XXX
 SG_ 空调PTC 加热开关状态 : 10|2@1+ (1,0) [0|0] "" Vector__XXX
 SG_ 空调通风状态 : 12|2@1+ (1,0) [0|0] "" Vector__XXX
 SG_ 空调自动模式状态 : 14|2@1+ (1,0) [0|0] "" Vector__XXX
 SG_ 蒸发风扇估算转速百分比 : 16|8@1+ (0.4,0) [0|100] "%" Vector__XXX
 SG_ 冷凝风扇估算转速百分比 : 24|8@1+ (0.4,0) [0|100] "%" Vector__XXX
 SG_ 压缩机运行状态百分比 : 32|8@1+ (0.4,0) [0|100] "%" Vector__XXX
 SG_ 空调设定温度 : 40|8@1+ (0.5,-40) [-40|87.5] "deg C" Vector__XXX
 SG_ 当前车内温度 : 48|8@1+ (0.5,-40) [-40|87.5] "deg C" Vector__XXX
 SG_ 当前车外温度 : 56|8@1+ (0.5,-40) [-40|87.5] "deg C" Vector__XXX

BA_ "VFrameFormat" BO_ 2566898201 1;
CM_ BO_ 2566898201 "PTC 加热开关状态 / 冷凝风扇估算转速百分比 | 信号数 13";
CM_ SG_ 2566898201 新风模式 "新风模式 [枚举: 关闭|工作]";
VAL_ 2566898201 新风模式 0 "关闭" 1 "工作";
CM_ SG_ 2566898201 制热模式 "制热模式 [枚举: 关闭|工作]";
VAL_ 2566898201 制热模式 0 "关闭" 1 "工作";
CM_ SG_ 2566898201 制冷模式 "制冷模式 [枚举: 关闭|工作]";
VAL_ 2566898201 制冷模式 0 "关闭" 1 "工作";
CM_ SG_ 2566898201 空调开关状态 "空调开关状态 [枚举: 关闭|工作]";
VAL_ 2566898201 空调开关状态 0 "关闭" 1 "工作";
CM_ SG_ 2566898201 空调PTC 加热开关状态 "空调PTC 加热开关状态 [枚举: 关闭|工作]";
VAL_ 2566898201 空调PTC 加热开关状态 0 "关闭" 1 "工作";
CM_ SG_ 2566898201 空调通风状态 "空调通风状态 [枚举: 关闭|工作]";
VAL_ 2566898201 空调通风状态 0 "关闭" 1 "工作";
CM_ SG_ 2566898201 空调自动模式状态 "空调自动模式状态 [枚举: 关闭|工作]";
VAL_ 2566898201 空调自动模式状态 0 "关闭" 1 "工作";
CM_ SG_ 2566898201 蒸发风扇估算转速百分比 "蒸发风扇估算转速百分比";
CM_ SG_ 2566898201 冷凝风扇估算转速百分比 "冷凝风扇估算转速百分比";
CM_ SG_ 2566898201 压缩机运行状态百分比 "压缩机运行状态百分比";
CM_ SG_ 2566898201 空调设定温度 "空调设定温度";
CM_ SG_ 2566898201 当前车内温度 "当前车内温度";
CM_ SG_ 2566898201 当前车外温度 "当前车外温度";

BO_ 2566898457 ZT_18FFC319: 8 Vector__XXX
 SG_ 蒸发器芯体温度 : 0|8@1+ (1,-40) [-40|100] "" Vector__XXX
 SG_ 冷凝器芯体温度 : 8|8@1+ (1,-40) [-40|210] "deg C" Vector__XXX
 SG_ 电机水箱进水口温度 : 48|8@1+ (1,-40) [-40|215] "deg C" Vector__XXX
 SG_ 电机水箱出水口温度 : 56|8@1+ (1,-40) [-40|215] "deg C" Vector__XXX

BA_ "VFrameFormat" BO_ 2566898457 1;
CM_ BO_ 2566898457 "冷凝器芯体温度 / 电机水箱出水口温度 | 信号数 7";
CM_ SG_ 2566898457 蒸发器芯体温度 "蒸发器芯体温度";
CM_ SG_ 2566898457 冷凝器芯体温度 "冷凝器芯体温度";
CM_ SG_ 2566898457 电机水箱进水口温度 "电机水箱进水口温度";
CM_ SG_ 2566898457 电机水箱出水口温度 "电机水箱出水口温度";

BO_ 2566898713 ZT_18FFC419: 8 Vector__XXX
 SG_ 空调电耗/次 : 0|8@1+ (0.1,0) [0|600] "kWh" Vector__XXX
 SG_ 空调总电耗 : 8|8@1+ (0.1,0) [0|100000] "kWh" Vector__XXX

BA_ "VFrameFormat" BO_ 2566898713 1;
CM_ BO_ 2566898713 "空调总电耗 / 空调总耗电 | 信号数 4";
CM_ SG_ 2566898713 空调电耗/次 "空调电耗/次";
CM_ SG_ 2566898713 空调总电耗 "空调总电耗";

BO_ 2566898969 ZT_18FFC519: 8 Vector__XXX
 SG_ 空调工作时间 : 0|16@1+ (0.5,0) [0|32700] "h" Vector__XXX
 SG_ 蒸发器工作时间 : 16|16@1+ (0.5,0) [0|32700] "h" Vector__XXX
 SG_ 压缩机工作累计时间 : 32|16@1+ (0.5,0) [0|32700] "h" Vector__XXX
 SG_ PTC工作累计时间 : 48|16@1+ (0.5,0) [0|32700] "h" Vector__XXX

BA_ "VFrameFormat" BO_ 2566898969 1;
CM_ BO_ 2566898969 "PTC工作累计时间 / 压缩机主接触器状态 | 信号数 6";
CM_ SG_ 2566898969 空调工作时间 "空调工作时间";
CM_ SG_ 2566898969 蒸发器工作时间 "蒸发器工作时间";
CM_ SG_ 2566898969 压缩机工作累计时间 "压缩机工作累计时间";
CM_ SG_ 2566898969 PTC工作累计时间 "PTC工作累计时间";

BO_ 2566899183 ZT_18FFC5EF: 8 Vector__XXX
 SG_ 集成风扇转速百分比 : 0|8@1+ (0.4,0) [0|100] "%" Vector__XXX

BA_ "VFrameFormat" BO_ 2566899183 1;
CM_ BO_ 2566899183 "集成风扇转速百分比 | 信号数 1";
CM_ SG_ 2566899183 集成风扇转速百分比 "集成风扇转速百分比";

BO_ 2566899225 ZT_18FFC619: 8 Vector__XXX
 SG_ 压缩机预充接触器状态 : 0|2@1+ (1,0) [0|0] "" Vector__XXX
 SG_ 压缩机主接触器状态 : 2|2@1+ (1,0) [0|0] "" Vector__XXX
 SG_ PTC接触器状态 : 4|2@1+ (1,0) [0|0] "" Vector__XXX
 SG_ 空调请求多合一内接触器状态 : 6|2@1+ (1,0) [0|0] "" Vector__XXX
 SG_ 水箱液位 : 48|16@1+ (0.4,0) [0|100] "%" Vector__XXX

BA_ "VFrameFormat" BO_ 2566899225 1;
CM_ BO_ 2566899225 "PTC接触器状态 / 压缩机主接触器状态 | 信号数 7";
CM_ SG_ 2566899225 压缩机预充接触器状态 "压缩机预充接触器状态 [枚举: 断开|闭合]";
VAL_ 2566899225 压缩机预充接触器状态 0 "断开" 1 "闭合";
CM_ SG_ 2566899225 压缩机主接触器状态 "压缩机主接触器状态 [枚举: 断开|闭合]";
VAL_ 2566899225 压缩机主接触器状态 0 "断开" 1 "闭合";
CM_ SG_ 2566899225 PTC接触器状态 "PTC接触器状态 [枚举: 断开|闭合]";
VAL_ 2566899225 PTC接触器状态 0 "断开" 1 "闭合";
CM_ SG_ 2566899225 空调请求多合一内接触器状态 "空调请求多合一内接触器状态 [枚举: 断开|闭合]";
VAL_ 2566899225 空调请求多合一内接触器状态 0 "断开" 1 "闭合";
CM_ SG_ 2566899225 水箱液位 "水箱液位";

BO_ 2566909951 ZT_18FFEFFF: 8 Vector__XXX
 SG_ 远程执行有效位 : 0|1@1+ (1,0) [0|1] "" Vector__XXX
 SG_ 终端网络状态 : 8|1@1+ (1,0) [0|1] "" Vector__XXX
 SG_ 流量卡安装状态 : 9|1@1+ (1,0) [0|1] "" Vector__XXX
 SG_ 远程锁车请求模式 : 1|2@1+ (1,0) [0|3] "" Vector__XXX
 SG_ 生命信号 : 56|8@1+ (1,0) [0|255] "" Vector__XXX

BA_ "VFrameFormat" BO_ 2566909951 1;
CM_ BO_ 2566909951 "流量卡安装状态 / 生命信号 | 信号数 5";
CM_ SG_ 2566909951 远程执行有效位 "远程执行有效位 [枚举: 无效|有效]";
VAL_ 2566909951 远程执行有效位 0 "无效" 1 "有效";
CM_ SG_ 2566909951 终端网络状态 "终端网络状态 [枚举: 离线|在线]";
VAL_ 2566909951 终端网络状态 0 "离线" 1 "在线";
CM_ SG_ 2566909951 流量卡安装状态 "流量卡安装状态 [枚举: 未安装|安装]";
VAL_ 2566909951 流量卡安装状态 0 "未安装" 1 "安装";
CM_ SG_ 2566909951 远程锁车请求模式 "远程锁车请求模式 [枚举: 无请求|锁车请求|解锁请求|锁车预警]";
VAL_ 2566909951 远程锁车请求模式 0 "无请求" 1 "锁车请求" 2 "解锁请求" 3 "锁车预警";
CM_ SG_ 2566909951 生命信号 "生命信号";

BO_ 2585788163 ZT_1A1FFF03: 8 Vector__XXX
 SG_ 数据S : 0|8@1+ (1,0) [0|255] "" Vector__XXX
 SG_ 数据T : 8|8@1+ (1,0) [0|1000] "" Vector__XXX
 SG_ 数据A : 16|8@1+ (1,0) [0|1000] "" Vector__XXX
 SG_ 数据B : 24|8@1+ (1,0) [0|1000] "" Vector__XXX
 SG_ 绝缘检测仪开关命令 : 32|8@1+ (1,0) [0|0] "" Vector__XXX
 SG_ 绝缘检测仪全生命周期值 : 40|8@1+ (1,0) [0|255] "" Vector__XXX

BA_ "VFrameFormat" BO_ 2585788163 1;
CM_ BO_ 2585788163 "信号检查 / 全生命周期 | 信号数 13";
CM_ SG_ 2585788163 数据S "数据S";
CM_ SG_ 2585788163 数据T "数据T";
CM_ SG_ 2585788163 数据A "数据A";
CM_ SG_ 2585788163 数据B "数据B";
CM_ SG_ 2585788163 绝缘检测仪开关命令 "绝缘检测仪开关命令 [原始公式: if((BYTE[4])==0) 0; else if((BYTE[4])==255) 1; else 2] [枚举: 已关闭或电池自带绝缘检测仪|已打开|预留]";
CM_ SG_ 2585788163 绝缘检测仪全生命周期值 "绝缘检测仪全生命周期值";
